VERSION "dbc-export 1 2026.26.6.5"

NS_ :

BS_:

BU_: ADSP APB APP APS APSB BB BMS CC CMP CMPD CP DAS DI DIF DIR DPB EPAS3P EPAS3S EPASTP EPASTS EPBL EPBR ESP EVSE FC GTW HCML HCMR HVP IBST ICR IDB LS OCS1P ODIN PARK PCS PCS2 PLG PM PMF PMR PNCD PTC RADC RCM RCM2 RCM3 RCU SCCM SCM SCS SDCR TAS TCU TCU2 TPMS TRCM UDS UI UIS UMC USM V2G VC VCBATT VCBATT0 VCBATT1 VCBATT2 VCCC VCFRONT VCFRONT1 VCFRONT2 VCLEFT VCRIGHT VCSEAT2L VCSEAT2R VCSEC VEH

BO_ 1317 PMF_alertLog: 8 PMF
 SG_ PMF_alertID M : 0|7@1+ (1,0) [0|127] "" Vector__XXX
 SG_ PMF_alertState : 15|1@1+ (1,0) [0|1] "" Vector__XXX
 SG_ PMF_a001_w0 m1 : 16|16@1+ (1,0) [0|65535] "" Vector__XXX
 SG_ PMF_a001_w1 m1 : 32|16@1+ (1,0) [0|65535] "" Vector__XXX
 SG_ PMF_a001_w2 m1 : 48|16@1+ (1,0) [0|65535] "" Vector__XXX
 SG_ PMF_a002_torqueAverage m2 : 16|1@1+ (1,0) [0|1] "" Vector__XXX
 SG_ PMF_a002_torqueWindow m2 : 17|1@1+ (1,0) [0|1] "" Vector__XXX
 SG_ PMF_a002_torqueMeasured m2 : 18|13@1- (2,0) [-8192|8190] "Nm" Vector__XXX
 SG_ PMF_a002_torqueAccelAverage m2 : 32|13@1- (2,0) [-8192|8190] "Nm" Vector__XXX
 SG_ PMF_a002_torqueAccelWindow m2 : 48|13@1- (2,0) [-8192|8190] "Nm" Vector__XXX
 SG_ PMF_a003_reverseGear m3 : 16|1@1+ (1,0) [0|1] "" Vector__XXX
 SG_ PMF_a003_pedalPos m3 : 24|8@1+ (0.4,0) [0|102] "%" Vector__XXX
 SG_ PMF_a003_zeroPointPedal m3 : 32|8@1+ (0.4,0) [0|102] "%" Vector__XXX
 SG_ PMF_a004_torqueAverage m4 : 16|1@1+ (1,0) [0|1] "" Vector__XXX
 SG_ PMF_a004_torqueWindow m4 : 17|1@1+ (1,0) [0|1] "" Vector__XXX
 SG_ PMF_a004_torqueMeasured m4 : 18|13@1- (2,0) [-8192|8190] "Nm" Vector__XXX
 SG_ PMF_a004_torqueDecelAverage m4 : 32|13@1- (2,0) [-8192|8190] "Nm" Vector__XXX
 SG_ PMF_a004_torqueDecelWindow m4 : 48|13@1- (2,0) [-8192|8190] "Nm" Vector__XXX
 SG_ PMF_a005_torqueReason m5 : 16|2@1+ (1,0) [0|3] "" Vector__XXX
 SG_ PMF_a005_torqueMeasured m5 : 18|13@1- (2,0) [-8192|8190] "Nm" Vector__XXX
 SG_ PMF_a005_iDQmagnitude m5 : 32|16@1- (0.0939,0) [-3076.9152|3076.8213] "A" Vector__XXX
 SG_ PMF_a006_torqueActual m6 : 16|13@1- (2,0) [-8192|8190] "Nm" Vector__XXX
 SG_ PMF_a006_motorRPM m6 : 32|16@1- (1,0) [-32768|32767] "RPM" Vector__XXX
 SG_ PMF_a006_torqueMeasured m6 : 48|13@1- (2,0) [-8192|8190] "Nm" Vector__XXX
 SG_ PMF_a010_messageId m10 : 16|16@1+ (1,0) [0|65535] "" Vector__XXX
 SG_ PMF_a010_DI_status m10 : 32|1@1+ (1,0) [0|1] "" Vector__XXX
 SG_ PMF_a010_DI_torque m10 : 33|1@1+ (1,0) [0|1] "" Vector__XXX
 SG_ PMF_a010_DI_slaveCommand m10 : 34|1@1+ (1,0) [0|1] "" Vector__XXX
 SG_ PMF_a010_DI_locStatus m10 : 35|1@1+ (1,0) [0|1] "" Vector__XXX
 SG_ PMF_a010_DI_speed m10 : 36|1@1+ (1,0) [0|1] "" Vector__XXX
 SG_ PMF_a010_DI_systemStatus m10 : 37|1@1+ (1,0) [0|1] "" Vector__XXX
 SG_ PMF_a010_DI_chassisControl m10 : 38|1@1+ (1,0) [0|1] "" Vector__XXX
 SG_ PMF_a010_DI_chassisControl2 m10 : 39|1@1+ (1,0) [0|1] "" Vector__XXX
 SG_ PMF_a010_vdcLeft m10 : 40|1@1+ (1,0) [0|1] "" Vector__XXX
 SG_ PMF_a010_vdcRight m10 : 41|1@1+ (1,0) [0|1] "" Vector__XXX
 SG_ PMF_a010_DI_vehicleEstimates m10 : 42|1@1+ (1,0) [0|1] "" Vector__XXX
 SG_ PMF_a010_DI_brakeCommand m10 : 43|1@1+ (1,0) [0|1] "" Vector__XXX
 SG_ PMF_a010_DI_autonomyHealth m10 : 44|1@1+ (1,0) [0|1] "" Vector__XXX
 SG_ PMF_a010_DI_difCommand m10 : 45|1@1+ (1,0) [0|1] "" Vector__XXX
 SG_ PMF_a010_DI_dirCommand m10 : 46|1@1+ (1,0) [0|1] "" Vector__XXX
 SG_ PMF_a010_DI_dirVehicle m10 : 47|1@1+ (1,0) [0|1] "" Vector__XXX
 SG_ PMF_a010_DI_locStatus2 m10 : 48|1@1+ (1,0) [0|1] "" Vector__XXX
 SG_ PMF_a011_Ia m11 : 16|9@1- (12.0192,0) [-3076.9152|3064.896] "A" Vector__XXX
 SG_ PMF_a011_IaDelta m11 : 25|8@1- (24.0384,0) [-3076.9152|3052.8768] "A" Vector__XXX
 SG_ PMF_a011_Ib m11 : 33|9@1- (12.0192,0) [-3076.9152|3064.896] "A" Vector__XXX
 SG_ PMF_a011_IbDelta m11 : 42|8@1- (24.0384,0) [-3076.9152|3052.8768] "A" Vector__XXX
 SG_ PMF_a011_currentVref m11 : 50|8@1+ (0.04,0) [0|10.2] "V" Vector__XXX
 SG_ PMF_a011_badPhaseAsample m11 : 58|1@1+ (1,0) [0|1] "" Vector__XXX
 SG_ PMF_a011_badPhaseBsample m11 : 59|1@1+ (1,0) [0|1] "" Vector__XXX
 SG_ PMF_a011_sampleFreeze m11 : 60|1@1+ (1,0) [0|1] "" Vector__XXX
 SG_ PMF_a011_rateOfChangeIrrational m11 : 61|1@1+ (1,0) [0|1] "" Vector__XXX
 SG_ PMF_a011_currentReadingIrrationa m11 : 62|1@1+ (1,0) [0|1] "" Vector__XXX
 SG_ PMF_a011_vrefIrrational m11 : 63|1@1+ (1,0) [0|1] "" Vector__XXX
 SG_ PMF_a017_EPBL_status m17 : 16|1@1+ (1,0) [0|1] "" Vector__XXX
 SG_ PMF_a017_EPBR_status m17 : 17|1@1+ (1,0) [0|1] "" Vector__XXX
 SG_ PMF_a017_EPBL_autonomyHealth m17 : 18|1@1+ (1,0) [0|1] "" Vector__XXX
 SG_ PMF_a017_EPBR_autonomyHealth m17 : 19|1@1+ (1,0) [0|1] "" Vector__XXX
 SG_ PMF_a018_w0 m18 : 16|16@1+ (1,0) [0|65535] "" Vector__XXX
 SG_ PMF_a018_w1 m18 : 32|16@1+ (1,0) [0|65535] "" Vector__XXX
 SG_ PMF_a018_w2 m18 : 48|16@1+ (1,0) [0|65535] "" Vector__XXX
 SG_ PMF_a019_statorTemp1 m19 : 16|16@1- (0.1,0) [-3276.8|3276.7] "DegC" Vector__XXX
 SG_ PMF_a019_statorTslope1 m19 : 32|16@1- (0.1,0) [-3276.8|3276.7] "DegC/s" Vector__XXX
 SG_ PMF_a025_sccReset m25 : 16|1@1+ (1,0) [0|1] "" Vector__XXX
 SG_ PMF_a025_hibernate m25 : 17|1@1+ (1,0) [0|1] "" Vector__XXX
 SG_ PMF_a025_hwBist m25 : 18|1@1+ (1,0) [0|1] "" Vector__XXX
 SG_ PMF_a025_nmiWatchdog m25 : 19|1@1+ (1,0) [0|1] "" Vector__XXX
 SG_ PMF_a025_watchdog m25 : 20|1@1+ (1,0) [0|1] "" Vector__XXX
 SG_ PMF_a025_clockFailNmi m25 : 21|1@1+ (1,0) [0|1] "" Vector__XXX
 SG_ PMF_a025_ramUncErrorNmi m25 : 22|1@1+ (1,0) [0|1] "" Vector__XXX
 SG_ PMF_a025_flashUncErrorNmi m25 : 23|1@1+ (1,0) [0|1] "" Vector__XXX
 SG_ PMF_a025_cpu1signMismatchNmi m25 : 24|1@1+ (1,0) [0|1] "" Vector__XXX
 SG_ PMF_a025_cpu2signMismatchNmi m25 : 25|1@1+ (1,0) [0|1] "" Vector__XXX
 SG_ PMF_a025_pieVectErrorNmi m25 : 26|1@1+ (1,0) [0|1] "" Vector__XXX
 SG_ PMF_a025_sysDbgNmi m25 : 27|1@1+ (1,0) [0|1] "" Vector__XXX
 SG_ PMF_a025_rlNmi m25 : 28|1@1+ (1,0) [0|1] "" Vector__XXX
 SG_ PMF_a025_ovfNmi m25 : 29|1@1+ (1,0) [0|1] "" Vector__XXX
 SG_ PMF_a025_possibleSafetyICReset m25 : 30|1@1+ (1,0) [0|1] "" Vector__XXX
 SG_ PMF_a025_powerOnReset m25 : 31|1@1+ (1,0) [0|1] "" Vector__XXX
 SG_ PMF_a025_watchdogTimer0 m25 : 32|1@1+ (1,0) [0|1] "" Vector__XXX
 SG_ PMF_a025_watchdogTimer1 m25 : 33|1@1+ (1,0) [0|1] "" Vector__XXX
 SG_ PMF_a025_watchdogTimer2 m25 : 34|1@1+ (1,0) [0|1] "" Vector__XXX
 SG_ PMF_a025_watchdogTimer3 m25 : 35|1@1+ (1,0) [0|1] "" Vector__XXX
 SG_ PMF_a025_warmResetReq m25 : 36|1@1+ (1,0) [0|1] "" Vector__XXX
 SG_ PMF_a025_externalPadReset m25 : 37|1@1+ (1,0) [0|1] "" Vector__XXX
 SG_ PMF_a025_hwSecModuleWatchdogTime m25 : 38|1@1+ (1,0) [0|1] "" Vector__XXX
 SG_ PMF_a025_debugReset m25 : 39|1@1+ (1,0) [0|1] "" Vector__XXX
 SG_ PMF_a025_tempSense0 m25 : 40|1@1+ (1,0) [0|1] "" Vector__XXX
 SG_ PMF_a025_tempSense1 m25 : 41|1@1+ (1,0) [0|1] "" Vector__XXX
 SG_ PMF_a026_reason m26 : 16|1@1+ (1,0) [0|1] "" Vector__XXX
 SG_ PMF_a026_isrCount20kHz m26 : 17|5@1+ (1,0) [0|31] "" Vector__XXX
 SG_ PMF_a026_isrCount1kHz m26 : 22|4@1+ (1,0) [0|15] "" Vector__XXX
 SG_ PMF_a026_switchingActive m26 : 26|1@1+ (1,0) [0|1] "" Vector__XXX
 SG_ PMF_a026_systemStackOvf m26 : 27|1@1+ (1,0) [0|1] "" Vector__XXX
 SG_ PMF_a026_controlStackOvf m26 : 28|1@1+ (1,0) [0|1] "" Vector__XXX
 SG_ PMF_a026_idleStackOvf m26 : 29|1@1+ (1,0) [0|1] "" Vector__XXX
 SG_ PMF_a026_eepStackOvf m26 : 30|1@1+ (1,0) [0|1] "" Vector__XXX
 SG_ PMF_a026_immStackOvf m26 : 31|1@1+ (1,0) [0|1] "" Vector__XXX
 SG_ PMF_a026_xdcErrorIdMSW m26 : 32|10@1+ (1,0) [0|1023] "" Vector__XXX
 SG_ PMF_a026_xdcErrorArg1 m26 : 42|22@1- (1,0) [-2097152|2097151] "" Vector__XXX
 SG_ PMF_a032_w0 m32 : 16|16@1+ (1,0) [0|65535] "" Vector__XXX
 SG_ PMF_a032_w1 m32 : 32|16@1+ (1,0) [0|65535] "" Vector__XXX
 SG_ PMF_a032_w2 m32 : 48|16@1+ (1,0) [0|65535] "" Vector__XXX
 SG_ PMF_a033_state m33 : 16|4@1+ (1,0) [0|15] "" Vector__XXX
 SG_ PMF_a033_failReason m33 : 20|3@1+ (1,0) [0|7] "" Vector__XXX
 SG_ PMF_a033_DSADC_Ia m33 : 24|16@1- (0.0939,0) [-3076.9152|3076.8213] "A" Vector__XXX
 SG_ PMF_a033_DSADC_Ib m33 : 40|16@1- (0.0939,0) [-3076.9152|3076.8213] "A" Vector__XXX
 SG_ PMF_a036_timeSinceTxHWI m36 : 16|6@1+ (64,0) [0|4032] "us" Vector__XXX
 SG_ PMF_a036_timeSinceRxHWI m36 : 22|6@1+ (64,0) [0|4032] "us" Vector__XXX
 SG_ PMF_a036_timeSince100HzTxSWI m36 : 28|6@1+ (0.32,0) [0|20.16] "ms" Vector__XXX
 SG_ PMF_a036_timeSince1kHzCLK m36 : 34|6@1+ (32,0) [0|2016] "us" Vector__XXX
 SG_ PMF_a036_timeSince1kHzSWI m36 : 40|6@1+ (32,0) [0|2016] "us" Vector__XXX
 SG_ PMF_a036_timeSinceIdle m36 : 46|6@1+ (0.16,0) [0|10.08] "ms" Vector__XXX
 SG_ PMF_a036_ovfStackId m36 : 52|4@1+ (1,0) [0|14] "" Vector__XXX
 SG_ PMF_a036_inTxISR m36 : 56|1@1+ (1,0) [0|1] "" Vector__XXX
 SG_ PMF_a036_inTxHWI m36 : 57|1@1+ (1,0) [0|1] "" Vector__XXX
 SG_ PMF_a036_inRxHWI m36 : 58|1@1+ (1,0) [0|1] "" Vector__XXX
 SG_ PMF_a036_in1kHzSWI m36 : 59|1@1+ (1,0) [0|1] "" Vector__XXX
 SG_ PMF_a036_in1kHzCLK m36 : 60|1@1+ (1,0) [0|1] "" Vector__XXX
 SG_ PMF_a036_in100HzCLK m36 : 61|1@1+ (1,0) [0|1] "" Vector__XXX
 SG_ PMF_a036_in10HzCLK m36 : 62|1@1+ (1,0) [0|1] "" Vector__XXX
 SG_ PMF_a036_in1HzCLK m36 : 63|1@1+ (1,0) [0|1] "" Vector__XXX
 SG_ PMF_a037_hvpFaults m37 : 16|1@1+ (1,0) [0|1] "" Vector__XXX
 SG_ PMF_a039_DIS_status m39 : 16|1@1+ (1,0) [0|1] "" Vector__XXX
 SG_ PMF_a039_DIS_torque m39 : 17|1@1+ (1,0) [0|1] "" Vector__XXX
 SG_ PMF_a039_messageId m39 : 24|16@1+ (1,0) [0|65535] "" Vector__XXX
 SG_ PMF_a040_PM_state m40 : 16|1@1+ (1,0) [0|1] "" Vector__XXX
 SG_ PMF_a040_messageId m40 : 24|16@1+ (1,0) [0|65535] "" Vector__XXX
 SG_ PMF_a040_PM_locState m40 : 40|1@1+ (1,0) [0|1] "" Vector__XXX
 SG_ PMF_a042_GTW_carConfig m42 : 16|1@1+ (1,0) [0|1] "" Vector__XXX
 SG_ PMF_a042_GTW_time m42 : 17|1@1+ (1,0) [0|1] "" Vector__XXX
 SG_ PMF_a042_GTW_drivetrainType m42 : 18|3@1+ (1,0) [0|7] "" Vector__XXX
 SG_ PMF_a042_expectedPerformanceCfg m42 : 21|3@1+ (1,0) [0|7] "" Vector__XXX
 SG_ PMF_a042_gearControl m42 : 24|1@1+ (1,0) [0|1] "" Vector__XXX
 SG_ PMF_a053_LVPowerState m53 : 16|1@1+ (1,0) [0|1] "" Vector__XXX
 SG_ PMF_a053_coolant m53 : 17|1@1+ (1,0) [0|1] "" Vector__XXX
 SG_ PMF_a053_vcleftSwitchStatus m53 : 18|1@1+ (1,0) [0|1] "" Vector__XXX
 SG_ PMF_a053_restraintStatus m53 : 19|1@1+ (1,0) [0|1] "" Vector__XXX
 SG_ PMF_a053_sensors m53 : 20|1@1+ (1,0) [0|1] "" Vector__XXX
 SG_ PMF_a054_uiPowertrainControl m54 : 16|1@1+ (1,0) [0|1] "" Vector__XXX
 SG_ PMF_a054_uiChassisControl m54 : 17|1@1+ (1,0) [0|1] "" Vector__XXX
 SG_ PMF_a054_uiCruiseControl m54 : 18|1@1+ (1,0) [0|1] "" Vector__XXX
 SG_ PMF_a054_uiTrackModeSettings m54 : 19|1@1+ (1,0) [0|1] "" Vector__XXX
 SG_ PMF_a054_uiTPMSRCPSetting m54 : 20|1@1+ (1,0) [0|1] "" Vector__XXX
 SG_ PMF_a055_motorRPM m55 : 16|16@1- (1,0) [-32768|32767] "RPM" Vector__XXX
 SG_ PMF_a055_phaseAngle m55 : 32|8@1+ (0.00308,0) [0|0.7854] "1" Vector__XXX
 SG_ PMF_a055_commonGain m55 : 40|8@1+ (0.02,0) [0|5.1] "1" Vector__XXX
 SG_ PMF_a055_notReady m55 : 48|1@1+ (1,0) [0|1] "" Vector__XXX
 SG_ PMF_a055_noCarrier m55 : 49|1@1+ (1,0) [0|1] "" Vector__XXX
 SG_ PMF_a055_phaseOutOfSpec m55 : 50|1@1+ (1,0) [0|1] "" Vector__XXX
 SG_ PMF_a055_diElecAngleMismatch m55 : 51|1@1+ (1,0) [0|1] "" Vector__XXX
 SG_ PMF_a055_diSpeedMismatch m55 : 52|1@1+ (1,0) [0|1] "" Vector__XXX
 SG_ PMF_a055_claMIA m55 : 53|1@1+ (1,0) [0|1] "" Vector__XXX
 SG_ PMF_a055_diMIA m55 : 54|1@1+ (1,0) [0|1] "" Vector__XXX
 SG_ PMF_a055_diElecAngleMismatchWarn m55 : 55|1@1+ (1,0) [0|1] "" Vector__XXX
 SG_ PMF_a058_hvilCurrent m58 : 16|8@1+ (0.1,0) [0|25.5] "mA" Vector__XXX
 SG_ PMF_a061_diIpcVersion m61 : 16|8@1+ (1,0) [0|255] "" Vector__XXX
 SG_ PMF_a061_pmIpcVersion m61 : 24|8@1+ (1,0) [0|255] "" Vector__XXX
 SG_ PMF_a062_address m62 : 16|32@1+ (1,0) [0|4294967295] "" Vector__XXX
 SG_ PMF_a062_errorType m62 : 48|4@1+ (1,0) [0|15] "" Vector__XXX
 SG_ PMF_a062_detectedByRamScrub m62 : 52|1@1+ (1,0) [0|1] "" Vector__XXX
 SG_ PMF_a064_interventionType m64 : 16|4@1+ (1,0) [0|15] "" Vector__XXX
 SG_ PMF_a064_torqueCmdState m64 : 20|4@1+ (1,0) [1|15] "" Vector__XXX
 SG_ PMF_a064_shortDetectedByDI m64 : 24|1@1+ (1,0) [0|1] "" Vector__XXX
 SG_ PMF_a064_UI_stoppingMode m64 : 25|2@1+ (1,0) [0|3] "" Vector__XXX
 SG_ PMF_a064_diCrsState m64 : 27|3@1+ (1,0) [0|7] "" Vector__XXX
 SG_ PMF_a064_pmCrsState m64 : 32|3@1+ (1,0) [0|7] "" Vector__XXX
 SG_ PMF_a082_faultAddress m82 : 16|32@1+ (1,0) [0|4294967295] "" Vector__XXX
 SG_ PMF_a082_isWriteNotRead m82 : 48|1@1+ (1,0) [0|1] "" Vector__XXX
 SG_ PMF_a084_faultAddress m84 : 16|32@1+ (1,0) [0|4294967295] "" Vector__XXX
 SG_ PMF_a084_firewallId m84 : 48|5@1+ (1,0) [0|31] "" Vector__XXX
 SG_ PMF_a084_privId m84 : 56|4@1+ (1,0) [0|15] "" Vector__XXX
 SG_ PMF_a084_ns m84 : 60|1@1+ (1,0) [0|1] "" Vector__XXX
 SG_ PMF_a084_faultType m84 : 61|3@1+ (1,0) [0|7] "" Vector__XXX
 SG_ PMF_a092_pllClockSource m92 : 16|2@1+ (1,0) [0|3] "" Vector__XXX
 SG_ PMF_a095_wwdErrIntFlag m95 : 16|1@1+ (1,0) [0|1] "" Vector__XXX
 SG_ PMF_a095_fwdErrIntFlag m95 : 17|1@1+ (1,0) [0|1] "" Vector__XXX
 SG_ PMF_a095_errMissStsFlag m95 : 18|1@1+ (1,0) [0|1] "" Vector__XXX
 SG_ PMF_a095_preRegulatorOT m95 : 19|1@1+ (1,0) [0|1] "" Vector__XXX
 SG_ PMF_a095_ucLdoOT m95 : 20|1@1+ (1,0) [0|1] "" Vector__XXX
 SG_ PMF_a095_monitoringOT m95 : 21|1@1+ (1,0) [0|1] "" Vector__XXX
 SG_ PMF_a095_preRegulatorVoltShort m95 : 22|1@1+ (1,0) [0|1] "" Vector__XXX
 SG_ PMF_a095_ucLdoShort m95 : 23|1@1+ (1,0) [0|1] "" Vector__XXX
 SG_ PMF_a095_standbyLdoShort m95 : 24|1@1+ (1,0) [0|1] "" Vector__XXX
 SG_ PMF_a095_coreVoltShort m95 : 25|1@1+ (1,0) [0|1] "" Vector__XXX
 SG_ PMF_a095_preRegulatorOV m95 : 26|1@1+ (1,0) [0|1] "" Vector__XXX
 SG_ PMF_a095_ucLdoOV m95 : 27|1@1+ (1,0) [0|1] "" Vector__XXX
 SG_ PMF_a095_standbyLdoOV m95 : 28|1@1+ (1,0) [0|1] "" Vector__XXX
 SG_ PMF_a095_coreOV m95 : 29|1@1+ (1,0) [0|1] "" Vector__XXX
 SG_ PMF_a095_voltRefOV m95 : 30|1@1+ (1,0) [0|1] "" Vector__XXX
 SG_ PMF_a095_ucLdoUV m95 : 31|1@1+ (1,0) [0|1] "" Vector__XXX
 SG_ PMF_a095_standbyLdoUV m95 : 32|1@1+ (1,0) [0|1] "" Vector__XXX
 SG_ PMF_a095_coreUV m95 : 33|1@1+ (1,0) [0|1] "" Vector__XXX
 SG_ PMF_a095_supplyVoltOV m95 : 34|1@1+ (1,0) [0|1] "" Vector__XXX
 SG_ PMF_a095_bandgapComparatorUV m95 : 35|1@1+ (1,0) [0|1] "" Vector__XXX
 SG_ PMF_a095_bandgapComparatorOV m95 : 36|1@1+ (1,0) [0|1] "" Vector__XXX
 SG_ PMF_a095_biasCurrentTooLow m95 : 37|1@1+ (1,0) [0|1] "" Vector__XXX
 SG_ PMF_a095_biasCurrentTooHigh m95 : 38|1@1+ (1,0) [0|1] "" Vector__XXX
 SG_ PMF_a095_safetyICstate m95 : 40|3@1+ (1,0) [0|7] "" Vector__XXX
 SG_ PMF_a095_motorRPM m95 : 43|12@1- (10,0) [-20480|20470] "RPM" Vector__XXX
 SG_ PMF_a095_wwdErrCounter m95 : 56|4@1+ (1,0) [0|15] "" Vector__XXX
 SG_ PMF_a095_fwdErrCounter m95 : 60|4@1+ (1,0) [0|15] "" Vector__XXX
 SG_ PMF_a100_index1kHzPeriodic m100 : 16|8@1+ (1,0) [0|255] "" Vector__XXX
 SG_ PMF_a100_index100HzPeriodic m100 : 24|8@1+ (1,0) [0|255] "" Vector__XXX
 SG_ PMF_a100_index10HzPeriodic m100 : 32|8@1+ (1,0) [0|255] "" Vector__XXX
 SG_ PMF_a100_indexSWI m100 : 40|8@1+ (1,0) [0|255] "" Vector__XXX
 SG_ PMF_a100_eepEvent m100 : 48|8@1+ (1,0) [0|255] "" Vector__XXX
 SG_ PMF_a100_module500HzActive m100 : 56|1@1+ (1,0) [0|1] "" Vector__XXX
 SG_ PMF_a100_module50HzActive m100 : 57|1@1+ (1,0) [0|1] "" Vector__XXX
 SG_ PMF_a100_module1HzActive m100 : 58|1@1+ (1,0) [0|1] "" Vector__XXX
 SG_ PMF_a100_task10HzActive m100 : 59|1@1+ (1,0) [0|1] "" Vector__XXX
 SG_ PMF_a100_taskUdsActive m100 : 60|1@1+ (1,0) [0|1] "" Vector__XXX

BO_ 772 PMF_alertMatrix: 8 PMF
 SG_ PMF_matrixIndex M : 0|4@1+ (1,0) [0|15] "" Vector__XXX
 SG_ PMF_a001_absoluteTorque m0 : 4|1@1+ (1,0) [0|1] "" Vector__XXX
 SG_ PMF_a002_excessiveAccelTorque m0 : 5|1@1+ (1,0) [0|1] "" Vector__XXX
 SG_ PMF_a003_excessiveReversalTorque m0 : 6|1@1+ (1,0) [0|1] "" Vector__XXX
 SG_ PMF_a004_excessiveDecelTorque m0 : 7|1@1+ (1,0) [0|1] "" Vector__XXX
 SG_ PMF_a005_torqueInNeutralOrPark m0 : 8|1@1+ (1,0) [0|1] "" Vector__XXX
 SG_ PMF_a006_underTorqueCheck m0 : 9|1@1+ (1,0) [0|1] "" Vector__XXX
 SG_ PMF_a008_memoryError m0 : 11|1@1+ (1,0) [0|1] "" Vector__XXX
 SG_ PMF_a010_diMIA m0 : 13|1@1+ (1,0) [0|1] "" Vector__XXX
 SG_ PMF_a011_phaseCurrentIrrational m0 : 14|1@1+ (1,0) [0|1] "" Vector__XXX
 SG_ PMF_a012_canDataBusA m0 : 15|1@1+ (1,0) [0|1] "" Vector__XXX
 SG_ PMF_a013_canHardwareBusA m0 : 16|1@1+ (1,0) [0|1] "" Vector__XXX
 SG_ PMF_a017_brakeMIA m0 : 20|1@1+ (1,0) [0|1] "" Vector__XXX
 SG_ PMF_a018_encoderIrrational m0 : 21|1@1+ (1,0) [0|1] "" Vector__XXX
 SG_ PMF_a019_statorTempIrrational m0 : 22|1@1+ (1,0) [0|1] "" Vector__XXX
 SG_ PMF_a025_unintendedReset m0 : 28|1@1+ (1,0) [0|1] "" Vector__XXX
 SG_ PMF_a026_diHeartBeatMIA m0 : 29|1@1+ (1,0) [0|1] "" Vector__XXX
 SG_ PMF_a027_torqueEstimationOutOfBo m0 : 30|1@1+ (1,0) [0|1] "" Vector__XXX
 SG_ PMF_a028_torqueCmdError m0 : 31|1@1+ (1,0) [0|1] "" Vector__XXX
 SG_ PMF_a031_highStackUsage m0 : 34|1@1+ (1,0) [0|1] "" Vector__XXX
 SG_ PMF_a032_registerConfigError m0 : 35|1@1+ (1,0) [0|1] "" Vector__XXX
 SG_ PMF_a033_selfTest m0 : 36|1@1+ (1,0) [0|1] "" Vector__XXX
 SG_ PMF_a034_trqCrossCheck m0 : 37|1@1+ (1,0) [0|1] "" Vector__XXX
 SG_ PMF_a035_udsTransactionInitiated m0 : 38|1@1+ (1,0) [0|1] "" Vector__XXX
 SG_ PMF_a036_preWatchdog m0 : 39|1@1+ (1,0) [0|1] "" Vector__XXX
 SG_ PMF_a037_hvpMIA m0 : 40|1@1+ (1,0) [0|1] "" Vector__XXX
 SG_ PMF_a039_disMIA m0 : 42|1@1+ (1,0) [0|1] "" Vector__XXX
 SG_ PMF_a040_pmMIA m0 : 43|1@1+ (1,0) [0|1] "" Vector__XXX
 SG_ PMF_a042_gtwMIA m0 : 45|1@1+ (1,0) [0|1] "" Vector__XXX
 SG_ PMF_a045_motorMovementDetected m0 : 48|1@1+ (1,0) [0|1] "" Vector__XXX
 SG_ PMF_a053_vcfrontMIA m0 : 56|1@1+ (1,0) [0|1] "" Vector__XXX
 SG_ PMF_a054_uiMIA m0 : 57|1@1+ (1,0) [0|1] "" Vector__XXX
 SG_ PMF_a055_resolver m0 : 58|1@1+ (1,0) [0|1] "" Vector__XXX
 SG_ PMF_a056_canHardwareBusB m0 : 59|1@1+ (1,0) [0|1] "" Vector__XXX
 SG_ PMF_a057_canDataBusB m0 : 60|1@1+ (1,0) [0|1] "" Vector__XXX
 SG_ PMF_a058_measuredHvilCurrentFroz m0 : 61|1@1+ (1,0) [0|1] "" Vector__XXX
 SG_ PMF_a061_DIPMVersionMismatch m1 : 4|1@1+ (1,0) [0|1] "" Vector__XXX
 SG_ PMF_a062_eccError m1 : 5|1@1+ (1,0) [0|1] "" Vector__XXX
 SG_ PMF_a064_torqueIntervention m1 : 7|1@1+ (1,0) [0|1] "" Vector__XXX
 SG_ PMF_a080_exceptionPrefetchAbort m1 : 23|1@1+ (1,0) [0|1] "" Vector__XXX
 SG_ PMF_a081_exceptionDataAbort m1 : 24|1@1+ (1,0) [0|1] "" Vector__XXX
 SG_ PMF_a082_exceptionDataAbort2 m1 : 25|1@1+ (1,0) [0|1] "" Vector__XXX
 SG_ PMF_a083_ahbWriteError m1 : 26|1@1+ (1,0) [0|1] "" Vector__XXX
 SG_ PMF_a084_exceptionMpuFirewall m1 : 27|1@1+ (1,0) [0|1] "" Vector__XXX
 SG_ PMF_a086_exceptionUndefinedInstr m1 : 29|1@1+ (1,0) [0|1] "" Vector__XXX
 SG_ PMF_a092_xtalOscillator m1 : 35|1@1+ (1,0) [0|1] "" Vector__XXX
 SG_ PMF_a094_safetyICWarn m1 : 37|1@1+ (1,0) [0|1] "" Vector__XXX
 SG_ PMF_a095_safetyICFault m1 : 38|1@1+ (1,0) [0|1] "" Vector__XXX
 SG_ PMF_a096_safetyICDebug m1 : 39|1@1+ (1,0) [0|1] "" Vector__XXX
 SG_ PMF_a097_lowFlowAlmostTripped m1 : 40|1@1+ (1,0) [0|1] "" Vector__XXX
 SG_ PMF_a100_diTraceInfo1 m1 : 43|1@1+ (1,0) [0|1] "" Vector__XXX
 SG_ PMF_a114_ramScrubTimedOut m1 : 57|1@1+ (1,0) [0|1] "" Vector__XXX
 SG_ PMF_a121_unintendedReset2 m2 : 4|1@1+ (1,0) [0|1] "" Vector__XXX

BO_ 790 PMF_info: 8 PMF
 SG_ PMF_infoIndex M : 0|8@1+ (1,0) [0|255] "" Vector__XXX
 SG_ PMF_buildType m10 : 8|8@1+ (1,0) [0|255] "" Vector__XXX
 SG_ PMF_buildConfigurationId m10 : 16|16@1+ (1,0) [0|65535] "" Vector__XXX
 SG_ PMF_hardwareId m10 : 32|8@1+ (1,0) [0|252] "" Vector__XXX
 SG_ PMF_deviceFused m10 : 40|1@1+ (1,0) [0|1] "" Vector__XXX
 SG_ PMF_componentId m10 : 48|16@1+ (1,0) [0|65535] "" Vector__XXX
 SG_ PMF_pcbaId m11 : 16|8@1+ (1,0) [0|255] "" Vector__XXX
 SG_ PMF_assemblyId m11 : 24|8@1+ (1,0) [0|255] "" Vector__XXX
 SG_ PMF_usageId m11 : 32|16@1+ (1,0) [0|65535] "" Vector__XXX
 SG_ PMF_subUsageId m11 : 48|16@1+ (1,0) [0|65535] "" Vector__XXX
 SG_ PMF_applicationCrc m13 : 32|32@1+ (1,0) [0|4294967295] "" Vector__XXX
 SG_ PMF_appGitHash m17 : 8|56@1+ (1,0) [0|7.20575940379e+16] "" Vector__XXX
 SG_ PMF_bootGitHash m18 : 8|56@1+ (1,0) [0|7.20575940379e+16] "" Vector__XXX
 SG_ PMF_platformTyp m19 : 8|8@1+ (1,0) [0|255] "" Vector__XXX
 SG_ PMF_udsProtocolVersion m20 : 8|8@1+ (1,0) [0|255] "" Vector__XXX
 SG_ PMF_bootloaderCrc m20 : 32|32@1+ (1,0) [0|4294967295] "" Vector__XXX

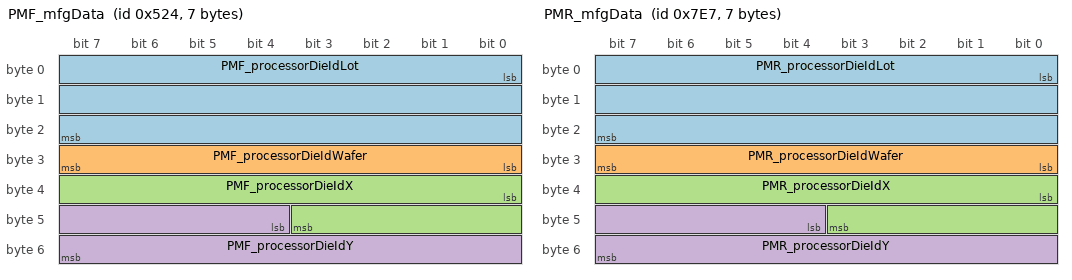
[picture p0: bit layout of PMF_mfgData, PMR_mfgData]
BO_ 1316 PMF_mfgData: 7 PMF
 SG_ PMF_processorDieIdLot : 0|24@1+ (1,0) [0|16777215] "" Vector__XXX
 SG_ PMF_processorDieIdWafer : 24|8@1+ (1,0) [0|255] "" Vector__XXX
 SG_ PMF_processorDieIdX : 32|12@1+ (1,0) [0|4095] "" Vector__XXX
 SG_ PMF_processorDieIdY : 44|12@1+ (1,0) [0|4095] "" Vector__XXX

BO_ 1620 PMF_udsResponse: 8 PMF
 SG_ PMF_udsResponseData : 7|64@0+ (1,0) [0|1.84467440737e+19] "" Vector__XXX

BO_ 1446 PMR_alertLog: 8 PMR
 SG_ PMR_alertID M : 0|7@1+ (1,0) [0|127] "" Vector__XXX
 SG_ PMR_alertState : 15|1@1+ (1,0) [0|1] "" Vector__XXX
 SG_ PMR_a001_w0 m1 : 16|16@1+ (1,0) [0|65535] "" Vector__XXX
 SG_ PMR_a001_w1 m1 : 32|16@1+ (1,0) [0|65535] "" Vector__XXX
 SG_ PMR_a001_w2 m1 : 48|16@1+ (1,0) [0|65535] "" Vector__XXX
 SG_ PMR_a002_torqueAverage m2 : 16|1@1+ (1,0) [0|1] "" Vector__XXX
 SG_ PMR_a002_torqueWindow m2 : 17|1@1+ (1,0) [0|1] "" Vector__XXX
 SG_ PMR_a002_torqueMeasured m2 : 18|13@1- (2,0) [-8192|8190] "Nm" Vector__XXX
 SG_ PMR_a002_torqueAccelAverage m2 : 32|13@1- (2,0) [-8192|8190] "Nm" Vector__XXX
 SG_ PMR_a002_torqueAccelWindow m2 : 48|13@1- (2,0) [-8192|8190] "Nm" Vector__XXX
 SG_ PMR_a003_reverseGear m3 : 16|1@1+ (1,0) [0|1] "" Vector__XXX
 SG_ PMR_a003_pedalPos m3 : 24|8@1+ (0.4,0) [0|102] "%" Vector__XXX
 SG_ PMR_a003_zeroPointPedal m3 : 32|8@1+ (0.4,0) [0|102] "%" Vector__XXX
 SG_ PMR_a004_torqueAverage m4 : 16|1@1+ (1,0) [0|1] "" Vector__XXX
 SG_ PMR_a004_torqueWindow m4 : 17|1@1+ (1,0) [0|1] "" Vector__XXX
 SG_ PMR_a004_torqueMeasured m4 : 18|13@1- (2,0) [-8192|8190] "Nm" Vector__XXX
 SG_ PMR_a004_torqueDecelAverage m4 : 32|13@1- (2,0) [-8192|8190] "Nm" Vector__XXX
 SG_ PMR_a004_torqueDecelWindow m4 : 48|13@1- (2,0) [-8192|8190] "Nm" Vector__XXX
 SG_ PMR_a005_torqueReason m5 : 16|2@1+ (1,0) [0|3] "" Vector__XXX
 SG_ PMR_a005_torqueMeasured m5 : 18|13@1- (2,0) [-8192|8190] "Nm" Vector__XXX
 SG_ PMR_a005_iDQmagnitude m5 : 32|16@1- (0.0939,0) [-3076.9152|3076.8213] "A" Vector__XXX
 SG_ PMR_a006_torqueActual m6 : 16|13@1- (2,0) [-8192|8190] "Nm" Vector__XXX
 SG_ PMR_a006_motorRPM m6 : 32|16@1- (1,0) [-32768|32767] "RPM" Vector__XXX
 SG_ PMR_a006_torqueMeasured m6 : 48|13@1- (2,0) [-8192|8190] "Nm" Vector__XXX
 SG_ PMR_a010_messageId m10 : 16|16@1+ (1,0) [0|65535] "" Vector__XXX
 SG_ PMR_a010_DI_status m10 : 32|1@1+ (1,0) [0|1] "" Vector__XXX
 SG_ PMR_a010_DI_torque m10 : 33|1@1+ (1,0) [0|1] "" Vector__XXX
 SG_ PMR_a010_DI_slaveCommand m10 : 34|1@1+ (1,0) [0|1] "" Vector__XXX
 SG_ PMR_a010_DI_locStatus m10 : 35|1@1+ (1,0) [0|1] "" Vector__XXX
 SG_ PMR_a010_DI_speed m10 : 36|1@1+ (1,0) [0|1] "" Vector__XXX
 SG_ PMR_a010_DI_systemStatus m10 : 37|1@1+ (1,0) [0|1] "" Vector__XXX
 SG_ PMR_a010_DI_chassisControl m10 : 38|1@1+ (1,0) [0|1] "" Vector__XXX
 SG_ PMR_a010_DI_chassisControl2 m10 : 39|1@1+ (1,0) [0|1] "" Vector__XXX
 SG_ PMR_a010_vdcLeft m10 : 40|1@1+ (1,0) [0|1] "" Vector__XXX
 SG_ PMR_a010_vdcRight m10 : 41|1@1+ (1,0) [0|1] "" Vector__XXX
 SG_ PMR_a010_DI_vehicleEstimates m10 : 42|1@1+ (1,0) [0|1] "" Vector__XXX
 SG_ PMR_a010_DI_brakeCommand m10 : 43|1@1+ (1,0) [0|1] "" Vector__XXX
 SG_ PMR_a010_DI_autonomyHealth m10 : 44|1@1+ (1,0) [0|1] "" Vector__XXX
 SG_ PMR_a010_DI_difCommand m10 : 45|1@1+ (1,0) [0|1] "" Vector__XXX
 SG_ PMR_a010_DI_dirCommand m10 : 46|1@1+ (1,0) [0|1] "" Vector__XXX
 SG_ PMR_a010_DI_dirVehicle m10 : 47|1@1+ (1,0) [0|1] "" Vector__XXX
 SG_ PMR_a010_DI_locStatus2 m10 : 48|1@1+ (1,0) [0|1] "" Vector__XXX
 SG_ PMR_a011_Ia m11 : 16|9@1- (12.0192,0) [-3076.9152|3064.896] "A" Vector__XXX
 SG_ PMR_a011_IaDelta m11 : 25|8@1- (24.0384,0) [-3076.9152|3052.8768] "A" Vector__XXX
 SG_ PMR_a011_Ib m11 : 33|9@1- (12.0192,0) [-3076.9152|3064.896] "A" Vector__XXX
 SG_ PMR_a011_IbDelta m11 : 42|8@1- (24.0384,0) [-3076.9152|3052.8768] "A" Vector__XXX
 SG_ PMR_a011_currentVref m11 : 50|8@1+ (0.04,0) [0|10.2] "V" Vector__XXX
 SG_ PMR_a011_badPhaseAsample m11 : 58|1@1+ (1,0) [0|1] "" Vector__XXX
 SG_ PMR_a011_badPhaseBsample m11 : 59|1@1+ (1,0) [0|1] "" Vector__XXX
 SG_ PMR_a011_sampleFreeze m11 : 60|1@1+ (1,0) [0|1] "" Vector__XXX
 SG_ PMR_a011_rateOfChangeIrrational m11 : 61|1@1+ (1,0) [0|1] "" Vector__XXX
 SG_ PMR_a011_currentReadingIrrationa m11 : 62|1@1+ (1,0) [0|1] "" Vector__XXX
 SG_ PMR_a011_vrefIrrational m11 : 63|1@1+ (1,0) [0|1] "" Vector__XXX
 SG_ PMR_a017_EPBL_status m17 : 16|1@1+ (1,0) [0|1] "" Vector__XXX
 SG_ PMR_a017_EPBR_status m17 : 17|1@1+ (1,0) [0|1] "" Vector__XXX
 SG_ PMR_a017_EPBL_autonomyHealth m17 : 18|1@1+ (1,0) [0|1] "" Vector__XXX
 SG_ PMR_a017_EPBR_autonomyHealth m17 : 19|1@1+ (1,0) [0|1] "" Vector__XXX
 SG_ PMR_a018_w0 m18 : 16|16@1+ (1,0) [0|65535] "" Vector__XXX
 SG_ PMR_a018_w1 m18 : 32|16@1+ (1,0) [0|65535] "" Vector__XXX
 SG_ PMR_a018_w2 m18 : 48|16@1+ (1,0) [0|65535] "" Vector__XXX
 SG_ PMR_a019_statorTemp1 m19 : 16|16@1- (0.1,0) [-3276.8|3276.7] "DegC" Vector__XXX
 SG_ PMR_a019_statorTslope1 m19 : 32|16@1- (0.1,0) [-3276.8|3276.7] "DegC/s" Vector__XXX
 SG_ PMR_a025_sccReset m25 : 16|1@1+ (1,0) [0|1] "" Vector__XXX
 SG_ PMR_a025_hibernate m25 : 17|1@1+ (1,0) [0|1] "" Vector__XXX
 SG_ PMR_a025_hwBist m25 : 18|1@1+ (1,0) [0|1] "" Vector__XXX
 SG_ PMR_a025_nmiWatchdog m25 : 19|1@1+ (1,0) [0|1] "" Vector__XXX
 SG_ PMR_a025_watchdog m25 : 20|1@1+ (1,0) [0|1] "" Vector__XXX
 SG_ PMR_a025_clockFailNmi m25 : 21|1@1+ (1,0) [0|1] "" Vector__XXX
 SG_ PMR_a025_ramUncErrorNmi m25 : 22|1@1+ (1,0) [0|1] "" Vector__XXX
 SG_ PMR_a025_flashUncErrorNmi m25 : 23|1@1+ (1,0) [0|1] "" Vector__XXX
 SG_ PMR_a025_cpu1signMismatchNmi m25 : 24|1@1+ (1,0) [0|1] "" Vector__XXX
 SG_ PMR_a025_cpu2signMismatchNmi m25 : 25|1@1+ (1,0) [0|1] "" Vector__XXX
 SG_ PMR_a025_pieVectErrorNmi m25 : 26|1@1+ (1,0) [0|1] "" Vector__XXX
 SG_ PMR_a025_sysDbgNmi m25 : 27|1@1+ (1,0) [0|1] "" Vector__XXX
 SG_ PMR_a025_rlNmi m25 : 28|1@1+ (1,0) [0|1] "" Vector__XXX
 SG_ PMR_a025_ovfNmi m25 : 29|1@1+ (1,0) [0|1] "" Vector__XXX
 SG_ PMR_a025_possibleSafetyICReset m25 : 30|1@1+ (1,0) [0|1] "" Vector__XXX
 SG_ PMR_a025_powerOnReset m25 : 31|1@1+ (1,0) [0|1] "" Vector__XXX
 SG_ PMR_a025_watchdogTimer0 m25 : 32|1@1+ (1,0) [0|1] "" Vector__XXX
 SG_ PMR_a025_watchdogTimer1 m25 : 33|1@1+ (1,0) [0|1] "" Vector__XXX
 SG_ PMR_a025_watchdogTimer2 m25 : 34|1@1+ (1,0) [0|1] "" Vector__XXX
 SG_ PMR_a025_watchdogTimer3 m25 : 35|1@1+ (1,0) [0|1] "" Vector__XXX
 SG_ PMR_a025_warmResetReq m25 : 36|1@1+ (1,0) [0|1] "" Vector__XXX
 SG_ PMR_a025_externalPadReset m25 : 37|1@1+ (1,0) [0|1] "" Vector__XXX
 SG_ PMR_a025_hwSecModuleWatchdogTime m25 : 38|1@1+ (1,0) [0|1] "" Vector__XXX
 SG_ PMR_a025_debugReset m25 : 39|1@1+ (1,0) [0|1] "" Vector__XXX
 SG_ PMR_a025_tempSense0 m25 : 40|1@1+ (1,0) [0|1] "" Vector__XXX
 SG_ PMR_a025_tempSense1 m25 : 41|1@1+ (1,0) [0|1] "" Vector__XXX
 SG_ PMR_a026_reason m26 : 16|1@1+ (1,0) [0|1] "" Vector__XXX
 SG_ PMR_a026_isrCount20kHz m26 : 17|5@1+ (1,0) [0|31] "" Vector__XXX
 SG_ PMR_a026_isrCount1kHz m26 : 22|4@1+ (1,0) [0|15] "" Vector__XXX
 SG_ PMR_a026_switchingActive m26 : 26|1@1+ (1,0) [0|1] "" Vector__XXX
 SG_ PMR_a026_systemStackOvf m26 : 27|1@1+ (1,0) [0|1] "" Vector__XXX
 SG_ PMR_a026_controlStackOvf m26 : 28|1@1+ (1,0) [0|1] "" Vector__XXX
 SG_ PMR_a026_idleStackOvf m26 : 29|1@1+ (1,0) [0|1] "" Vector__XXX
 SG_ PMR_a026_eepStackOvf m26 : 30|1@1+ (1,0) [0|1] "" Vector__XXX
 SG_ PMR_a026_immStackOvf m26 : 31|1@1+ (1,0) [0|1] "" Vector__XXX
 SG_ PMR_a026_xdcErrorIdMSW m26 : 32|10@1+ (1,0) [0|1023] "" Vector__XXX
 SG_ PMR_a026_xdcErrorArg1 m26 : 42|22@1- (1,0) [-2097152|2097151] "" Vector__XXX
 SG_ PMR_a032_w0 m32 : 16|16@1+ (1,0) [0|65535] "" Vector__XXX
 SG_ PMR_a032_w1 m32 : 32|16@1+ (1,0) [0|65535] "" Vector__XXX
 SG_ PMR_a032_w2 m32 : 48|16@1+ (1,0) [0|65535] "" Vector__XXX
 SG_ PMR_a033_state m33 : 16|4@1+ (1,0) [0|15] "" Vector__XXX
 SG_ PMR_a033_failReason m33 : 20|3@1+ (1,0) [0|7] "" Vector__XXX
 SG_ PMR_a033_DSADC_Ia m33 : 24|16@1- (0.0939,0) [-3076.9152|3076.8213] "A" Vector__XXX
 SG_ PMR_a033_DSADC_Ib m33 : 40|16@1- (0.0939,0) [-3076.9152|3076.8213] "A" Vector__XXX
 SG_ PMR_a036_timeSinceTxHWI m36 : 16|6@1+ (64,0) [0|4032] "us" Vector__XXX
 SG_ PMR_a036_timeSinceRxHWI m36 : 22|6@1+ (64,0) [0|4032] "us" Vector__XXX
 SG_ PMR_a036_timeSince100HzTxSWI m36 : 28|6@1+ (0.32,0) [0|20.16] "ms" Vector__XXX
 SG_ PMR_a036_timeSince1kHzCLK m36 : 34|6@1+ (32,0) [0|2016] "us" Vector__XXX
 SG_ PMR_a036_timeSince1kHzSWI m36 : 40|6@1+ (32,0) [0|2016] "us" Vector__XXX
 SG_ PMR_a036_timeSinceIdle m36 : 46|6@1+ (0.16,0) [0|10.08] "ms" Vector__XXX
 SG_ PMR_a036_ovfStackId m36 : 52|4@1+ (1,0) [0|14] "" Vector__XXX
 SG_ PMR_a036_inTxISR m36 : 56|1@1+ (1,0) [0|1] "" Vector__XXX
 SG_ PMR_a036_inTxHWI m36 : 57|1@1+ (1,0) [0|1] "" Vector__XXX
 SG_ PMR_a036_inRxHWI m36 : 58|1@1+ (1,0) [0|1] "" Vector__XXX
 SG_ PMR_a036_in1kHzSWI m36 : 59|1@1+ (1,0) [0|1] "" Vector__XXX
 SG_ PMR_a036_in1kHzCLK m36 : 60|1@1+ (1,0) [0|1] "" Vector__XXX
 SG_ PMR_a036_in100HzCLK m36 : 61|1@1+ (1,0) [0|1] "" Vector__XXX
 SG_ PMR_a036_in10HzCLK m36 : 62|1@1+ (1,0) [0|1] "" Vector__XXX
 SG_ PMR_a036_in1HzCLK m36 : 63|1@1+ (1,0) [0|1] "" Vector__XXX
 SG_ PMR_a037_hvpFaults m37 : 16|1@1+ (1,0) [0|1] "" Vector__XXX
 SG_ PMR_a039_DIS_status m39 : 16|1@1+ (1,0) [0|1] "" Vector__XXX
 SG_ PMR_a039_DIS_torque m39 : 17|1@1+ (1,0) [0|1] "" Vector__XXX
 SG_ PMR_a039_messageId m39 : 24|16@1+ (1,0) [0|65535] "" Vector__XXX
 SG_ PMR_a040_PM_state m40 : 16|1@1+ (1,0) [0|1] "" Vector__XXX
 SG_ PMR_a040_messageId m40 : 24|16@1+ (1,0) [0|65535] "" Vector__XXX
 SG_ PMR_a040_PM_locState m40 : 40|1@1+ (1,0) [0|1] "" Vector__XXX
 SG_ PMR_a042_GTW_carConfig m42 : 16|1@1+ (1,0) [0|1] "" Vector__XXX
 SG_ PMR_a042_GTW_time m42 : 17|1@1+ (1,0) [0|1] "" Vector__XXX
 SG_ PMR_a042_GTW_drivetrainType m42 : 18|3@1+ (1,0) [0|7] "" Vector__XXX
 SG_ PMR_a042_expectedPerformanceCfg m42 : 21|3@1+ (1,0) [0|7] "" Vector__XXX
 SG_ PMR_a042_gearControl m42 : 24|1@1+ (1,0) [0|1] "" Vector__XXX
 SG_ PMR_a053_LVPowerState m53 : 16|1@1+ (1,0) [0|1] "" Vector__XXX
 SG_ PMR_a053_coolant m53 : 17|1@1+ (1,0) [0|1] "" Vector__XXX
 SG_ PMR_a053_vcleftSwitchStatus m53 : 18|1@1+ (1,0) [0|1] "" Vector__XXX
 SG_ PMR_a053_restraintStatus m53 : 19|1@1+ (1,0) [0|1] "" Vector__XXX
 SG_ PMR_a053_sensors m53 : 20|1@1+ (1,0) [0|1] "" Vector__XXX
 SG_ PMR_a054_uiPowertrainControl m54 : 16|1@1+ (1,0) [0|1] "" Vector__XXX
 SG_ PMR_a054_uiChassisControl m54 : 17|1@1+ (1,0) [0|1] "" Vector__XXX
 SG_ PMR_a054_uiCruiseControl m54 : 18|1@1+ (1,0) [0|1] "" Vector__XXX
 SG_ PMR_a054_uiTrackModeSettings m54 : 19|1@1+ (1,0) [0|1] "" Vector__XXX
 SG_ PMR_a054_uiTPMSRCPSetting m54 : 20|1@1+ (1,0) [0|1] "" Vector__XXX
 SG_ PMR_a055_motorRPM m55 : 16|16@1- (1,0) [-32768|32767] "RPM" Vector__XXX
 SG_ PMR_a055_phaseAngle m55 : 32|8@1+ (0.00308,0) [0|0.7854] "1" Vector__XXX
 SG_ PMR_a055_commonGain m55 : 40|8@1+ (0.02,0) [0|5.1] "1" Vector__XXX
 SG_ PMR_a055_notReady m55 : 48|1@1+ (1,0) [0|1] "" Vector__XXX
 SG_ PMR_a055_noCarrier m55 : 49|1@1+ (1,0) [0|1] "" Vector__XXX
 SG_ PMR_a055_phaseOutOfSpec m55 : 50|1@1+ (1,0) [0|1] "" Vector__XXX
 SG_ PMR_a055_diElecAngleMismatch m55 : 51|1@1+ (1,0) [0|1] "" Vector__XXX
 SG_ PMR_a055_diSpeedMismatch m55 : 52|1@1+ (1,0) [0|1] "" Vector__XXX
 SG_ PMR_a055_claMIA m55 : 53|1@1+ (1,0) [0|1] "" Vector__XXX
 SG_ PMR_a055_diMIA m55 : 54|1@1+ (1,0) [0|1] "" Vector__XXX
 SG_ PMR_a055_diElecAngleMismatchWarn m55 : 55|1@1+ (1,0) [0|1] "" Vector__XXX
 SG_ PMR_a058_hvilCurrent m58 : 16|8@1+ (0.1,0) [0|25.5] "mA" Vector__XXX
 SG_ PMR_a061_diIpcVersion m61 : 16|8@1+ (1,0) [0|255] "" Vector__XXX
 SG_ PMR_a061_pmIpcVersion m61 : 24|8@1+ (1,0) [0|255] "" Vector__XXX
 SG_ PMR_a062_address m62 : 16|32@1+ (1,0) [0|4294967295] "" Vector__XXX
 SG_ PMR_a062_errorType m62 : 48|4@1+ (1,0) [0|15] "" Vector__XXX
 SG_ PMR_a062_detectedByRamScrub m62 : 52|1@1+ (1,0) [0|1] "" Vector__XXX
 SG_ PMR_a064_interventionType m64 : 16|4@1+ (1,0) [0|15] "" Vector__XXX
 SG_ PMR_a064_torqueCmdState m64 : 20|4@1+ (1,0) [1|15] "" Vector__XXX
 SG_ PMR_a064_shortDetectedByDI m64 : 24|1@1+ (1,0) [0|1] "" Vector__XXX
 SG_ PMR_a064_UI_stoppingMode m64 : 25|2@1+ (1,0) [0|3] "" Vector__XXX
 SG_ PMR_a064_diCrsState m64 : 27|3@1+ (1,0) [0|7] "" Vector__XXX
 SG_ PMR_a064_pmCrsState m64 : 32|3@1+ (1,0) [0|7] "" Vector__XXX
 SG_ PMR_a082_faultAddress m82 : 16|32@1+ (1,0) [0|4294967295] "" Vector__XXX
 SG_ PMR_a082_isWriteNotRead m82 : 48|1@1+ (1,0) [0|1] "" Vector__XXX
 SG_ PMR_a084_faultAddress m84 : 16|32@1+ (1,0) [0|4294967295] "" Vector__XXX
 SG_ PMR_a084_firewallId m84 : 48|5@1+ (1,0) [0|31] "" Vector__XXX
 SG_ PMR_a084_privId m84 : 56|4@1+ (1,0) [0|15] "" Vector__XXX
 SG_ PMR_a084_ns m84 : 60|1@1+ (1,0) [0|1] "" Vector__XXX
 SG_ PMR_a084_faultType m84 : 61|3@1+ (1,0) [0|7] "" Vector__XXX
 SG_ PMR_a092_pllClockSource m92 : 16|2@1+ (1,0) [0|3] "" Vector__XXX
 SG_ PMR_a095_wwdErrIntFlag m95 : 16|1@1+ (1,0) [0|1] "" Vector__XXX
 SG_ PMR_a095_fwdErrIntFlag m95 : 17|1@1+ (1,0) [0|1] "" Vector__XXX
 SG_ PMR_a095_errMissStsFlag m95 : 18|1@1+ (1,0) [0|1] "" Vector__XXX
 SG_ PMR_a095_preRegulatorOT m95 : 19|1@1+ (1,0) [0|1] "" Vector__XXX
 SG_ PMR_a095_ucLdoOT m95 : 20|1@1+ (1,0) [0|1] "" Vector__XXX
 SG_ PMR_a095_monitoringOT m95 : 21|1@1+ (1,0) [0|1] "" Vector__XXX
 SG_ PMR_a095_preRegulatorVoltShort m95 : 22|1@1+ (1,0) [0|1] "" Vector__XXX
 SG_ PMR_a095_ucLdoShort m95 : 23|1@1+ (1,0) [0|1] "" Vector__XXX
 SG_ PMR_a095_standbyLdoShort m95 : 24|1@1+ (1,0) [0|1] "" Vector__XXX
 SG_ PMR_a095_coreVoltShort m95 : 25|1@1+ (1,0) [0|1] "" Vector__XXX
 SG_ PMR_a095_preRegulatorOV m95 : 26|1@1+ (1,0) [0|1] "" Vector__XXX
 SG_ PMR_a095_ucLdoOV m95 : 27|1@1+ (1,0) [0|1] "" Vector__XXX
 SG_ PMR_a095_standbyLdoOV m95 : 28|1@1+ (1,0) [0|1] "" Vector__XXX
 SG_ PMR_a095_coreOV m95 : 29|1@1+ (1,0) [0|1] "" Vector__XXX
 SG_ PMR_a095_voltRefOV m95 : 30|1@1+ (1,0) [0|1] "" Vector__XXX
 SG_ PMR_a095_ucLdoUV m95 : 31|1@1+ (1,0) [0|1] "" Vector__XXX
 SG_ PMR_a095_standbyLdoUV m95 : 32|1@1+ (1,0) [0|1] "" Vector__XXX
 SG_ PMR_a095_coreUV m95 : 33|1@1+ (1,0) [0|1] "" Vector__XXX
 SG_ PMR_a095_supplyVoltOV m95 : 34|1@1+ (1,0) [0|1] "" Vector__XXX
 SG_ PMR_a095_bandgapComparatorUV m95 : 35|1@1+ (1,0) [0|1] "" Vector__XXX
 SG_ PMR_a095_bandgapComparatorOV m95 : 36|1@1+ (1,0) [0|1] "" Vector__XXX
 SG_ PMR_a095_biasCurrentTooLow m95 : 37|1@1+ (1,0) [0|1] "" Vector__XXX
 SG_ PMR_a095_biasCurrentTooHigh m95 : 38|1@1+ (1,0) [0|1] "" Vector__XXX
 SG_ PMR_a095_safetyICstate m95 : 40|3@1+ (1,0) [0|7] "" Vector__XXX
 SG_ PMR_a095_motorRPM m95 : 43|12@1- (10,0) [-20480|20470] "RPM" Vector__XXX
 SG_ PMR_a095_wwdErrCounter m95 : 56|4@1+ (1,0) [0|15] "" Vector__XXX
 SG_ PMR_a095_fwdErrCounter m95 : 60|4@1+ (1,0) [0|15] "" Vector__XXX
 SG_ PMR_a100_index1kHzPeriodic m100 : 16|8@1+ (1,0) [0|255] "" Vector__XXX
 SG_ PMR_a100_index100HzPeriodic m100 : 24|8@1+ (1,0) [0|255] "" Vector__XXX
 SG_ PMR_a100_index10HzPeriodic m100 : 32|8@1+ (1,0) [0|255] "" Vector__XXX
 SG_ PMR_a100_indexSWI m100 : 40|8@1+ (1,0) [0|255] "" Vector__XXX
 SG_ PMR_a100_eepEvent m100 : 48|8@1+ (1,0) [0|255] "" Vector__XXX
 SG_ PMR_a100_module500HzActive m100 : 56|1@1+ (1,0) [0|1] "" Vector__XXX
 SG_ PMR_a100_module50HzActive m100 : 57|1@1+ (1,0) [0|1] "" Vector__XXX
 SG_ PMR_a100_module1HzActive m100 : 58|1@1+ (1,0) [0|1] "" Vector__XXX
 SG_ PMR_a100_task10HzActive m100 : 59|1@1+ (1,0) [0|1] "" Vector__XXX
 SG_ PMR_a100_taskUdsActive m100 : 60|1@1+ (1,0) [0|1] "" Vector__XXX
 SG_ PMR_a101_VDDA18_ref33_uv m101 : 16|1@1+ (1,0) [0|1] "" Vector__XXX
 SG_ PMR_a101_VBGAP09_ov m101 : 17|1@1+ (1,0) [0|1] "" Vector__XXX
 SG_ PMR_a101_VBGAP09_uv m101 : 18|1@1+ (1,0) [0|1] "" Vector__XXX
 SG_ PMR_a101_VDDA18_refBGAP_ov m101 : 19|1@1+ (1,0) [0|1] "" Vector__XXX
 SG_ PMR_a101_VDDA18_refBGAP_uv m101 : 20|1@1+ (1,0) [0|1] "" Vector__XXX
 SG_ PMR_a101_VDD12_ov m101 : 21|1@1+ (1,0) [0|1] "" Vector__XXX
 SG_ PMR_a101_VDD12_uv m101 : 22|1@1+ (1,0) [0|1] "" Vector__XXX
 SG_ PMR_a101_VDDSBIO_ov m101 : 23|1@1+ (1,0) [0|1] "" Vector__XXX
 SG_ PMR_a101_VDDSBIO_uv m101 : 24|1@1+ (1,0) [0|1] "" Vector__XXX
 SG_ PMR_a101_VSYS_MON_uv m101 : 25|1@1+ (1,0) [0|1] "" Vector__XXX
 SG_ PMR_a101_VDDA33_uv m101 : 26|1@1+ (1,0) [0|1] "" Vector__XXX
 SG_ PMR_a101_ADC0_REF_ov m101 : 27|1@1+ (1,0) [0|1] "" Vector__XXX
 SG_ PMR_a101_ADC0_REF_uv m101 : 28|1@1+ (1,0) [0|1] "" Vector__XXX
 SG_ PMR_a101_ADC12_REF_ov m101 : 29|1@1+ (1,0) [0|1] "" Vector__XXX
 SG_ PMR_a101_ADC12_REF_uv m101 : 30|1@1+ (1,0) [0|1] "" Vector__XXX
 SG_ PMR_a101_ADC34_REF_ov m101 : 31|1@1+ (1,0) [0|1] "" Vector__XXX
 SG_ PMR_a101_ADC34_REF_uv m101 : 32|1@1+ (1,0) [0|1] "" Vector__XXX
 SG_ PMR_a101_ADCR01_REF_ov m101 : 33|1@1+ (1,0) [0|1] "" Vector__XXX
 SG_ PMR_a101_ADCR01_REF_uv m101 : 34|1@1+ (1,0) [0|1] "" Vector__XXX

BO_ 902 PMR_alertMatrix: 8 PMR
 SG_ PMR_matrixIndex M : 0|4@1+ (1,0) [0|15] "" Vector__XXX
 SG_ PMR_a001_absoluteTorque m0 : 4|1@1+ (1,0) [0|1] "" Vector__XXX
 SG_ PMR_a002_excessiveAccelTorque m0 : 5|1@1+ (1,0) [0|1] "" Vector__XXX
 SG_ PMR_a003_excessiveReversalTorque m0 : 6|1@1+ (1,0) [0|1] "" Vector__XXX
 SG_ PMR_a004_excessiveDecelTorque m0 : 7|1@1+ (1,0) [0|1] "" Vector__XXX
 SG_ PMR_a005_torqueInNeutralOrPark m0 : 8|1@1+ (1,0) [0|1] "" Vector__XXX
 SG_ PMR_a006_underTorqueCheck m0 : 9|1@1+ (1,0) [0|1] "" Vector__XXX
 SG_ PMR_a008_memoryError m0 : 11|1@1+ (1,0) [0|1] "" Vector__XXX
 SG_ PMR_a010_diMIA m0 : 13|1@1+ (1,0) [0|1] "" Vector__XXX
 SG_ PMR_a011_phaseCurrentIrrational m0 : 14|1@1+ (1,0) [0|1] "" Vector__XXX
 SG_ PMR_a012_canDataBusA m0 : 15|1@1+ (1,0) [0|1] "" Vector__XXX
 SG_ PMR_a013_canHardwareBusA m0 : 16|1@1+ (1,0) [0|1] "" Vector__XXX
 SG_ PMR_a017_brakeMIA m0 : 20|1@1+ (1,0) [0|1] "" Vector__XXX
 SG_ PMR_a018_encoderIrrational m0 : 21|1@1+ (1,0) [0|1] "" Vector__XXX
 SG_ PMR_a019_statorTempIrrational m0 : 22|1@1+ (1,0) [0|1] "" Vector__XXX
 SG_ PMR_a025_unintendedReset m0 : 28|1@1+ (1,0) [0|1] "" Vector__XXX
 SG_ PMR_a026_diHeartBeatMIA m0 : 29|1@1+ (1,0) [0|1] "" Vector__XXX
 SG_ PMR_a027_torqueEstimationOutOfBo m0 : 30|1@1+ (1,0) [0|1] "" Vector__XXX
 SG_ PMR_a028_torqueCmdError m0 : 31|1@1+ (1,0) [0|1] "" Vector__XXX
 SG_ PMR_a031_highStackUsage m0 : 34|1@1+ (1,0) [0|1] "" Vector__XXX
 SG_ PMR_a032_registerConfigError m0 : 35|1@1+ (1,0) [0|1] "" Vector__XXX
 SG_ PMR_a033_selfTest m0 : 36|1@1+ (1,0) [0|1] "" Vector__XXX
 SG_ PMR_a034_trqCrossCheck m0 : 37|1@1+ (1,0) [0|1] "" Vector__XXX
 SG_ PMR_a035_udsTransactionInitiated m0 : 38|1@1+ (1,0) [0|1] "" Vector__XXX
 SG_ PMR_a036_preWatchdog m0 : 39|1@1+ (1,0) [0|1] "" Vector__XXX
 SG_ PMR_a037_hvpMIA m0 : 40|1@1+ (1,0) [0|1] "" Vector__XXX
 SG_ PMR_a039_disMIA m0 : 42|1@1+ (1,0) [0|1] "" Vector__XXX
 SG_ PMR_a040_pmMIA m0 : 43|1@1+ (1,0) [0|1] "" Vector__XXX
 SG_ PMR_a042_gtwMIA m0 : 45|1@1+ (1,0) [0|1] "" Vector__XXX
 SG_ PMR_a045_motorMovementDetected m0 : 48|1@1+ (1,0) [0|1] "" Vector__XXX
 SG_ PMR_a053_vcfrontMIA m0 : 56|1@1+ (1,0) [0|1] "" Vector__XXX
 SG_ PMR_a054_uiMIA m0 : 57|1@1+ (1,0) [0|1] "" Vector__XXX
 SG_ PMR_a055_resolver m0 : 58|1@1+ (1,0) [0|1] "" Vector__XXX
 SG_ PMR_a056_canHardwareBusB m0 : 59|1@1+ (1,0) [0|1] "" Vector__XXX
 SG_ PMR_a057_canDataBusB m0 : 60|1@1+ (1,0) [0|1] "" Vector__XXX
 SG_ PMR_a058_measuredHvilCurrentFroz m0 : 61|1@1+ (1,0) [0|1] "" Vector__XXX
 SG_ PMR_a061_DIPMVersionMismatch m1 : 4|1@1+ (1,0) [0|1] "" Vector__XXX
 SG_ PMR_a062_eccError m1 : 5|1@1+ (1,0) [0|1] "" Vector__XXX
 SG_ PMR_a064_torqueIntervention m1 : 7|1@1+ (1,0) [0|1] "" Vector__XXX
 SG_ PMR_a080_exceptionPrefetchAbort m1 : 23|1@1+ (1,0) [0|1] "" Vector__XXX
 SG_ PMR_a081_exceptionDataAbort m1 : 24|1@1+ (1,0) [0|1] "" Vector__XXX
 SG_ PMR_a082_exceptionDataAbort2 m1 : 25|1@1+ (1,0) [0|1] "" Vector__XXX
 SG_ PMR_a083_ahbWriteError m1 : 26|1@1+ (1,0) [0|1] "" Vector__XXX
 SG_ PMR_a084_exceptionMpuFirewall m1 : 27|1@1+ (1,0) [0|1] "" Vector__XXX
 SG_ PMR_a086_exceptionUndefinedInstr m1 : 29|1@1+ (1,0) [0|1] "" Vector__XXX
 SG_ PMR_a092_xtalOscillator m1 : 35|1@1+ (1,0) [0|1] "" Vector__XXX
 SG_ PMR_a094_safetyICWarn m1 : 37|1@1+ (1,0) [0|1] "" Vector__XXX
 SG_ PMR_a095_safetyICFault m1 : 38|1@1+ (1,0) [0|1] "" Vector__XXX
 SG_ PMR_a096_safetyICDebug m1 : 39|1@1+ (1,0) [0|1] "" Vector__XXX
 SG_ PMR_a097_lowFlowAlmostTripped m1 : 40|1@1+ (1,0) [0|1] "" Vector__XXX
 SG_ PMR_a100_diTraceInfo1 m1 : 43|1@1+ (1,0) [0|1] "" Vector__XXX
 SG_ PMR_a101_hwVoltageMonitorTrip m1 : 44|1@1+ (1,0) [0|1] "" Vector__XXX
 SG_ PMR_a102_ipcFluidTempHigh m1 : 45|1@1+ (1,0) [0|1] "" Vector__XXX
 SG_ PMR_a114_ramScrubTimedOut m1 : 57|1@1+ (1,0) [0|1] "" Vector__XXX
 SG_ PMR_a121_unintendedReset2 m2 : 4|1@1+ (1,0) [0|1] "" Vector__XXX

BO_ 1748 PMR_info: 8 PMR
 SG_ PMR_infoIndex M : 0|8@1+ (1,0) [0|255] "" Vector__XXX
 SG_ PMR_buildType m10 : 8|8@1+ (1,0) [0|255] "" Vector__XXX
 SG_ PMR_buildConfigurationId m10 : 16|16@1+ (1,0) [0|65535] "" Vector__XXX
 SG_ PMR_hardwareId m10 : 32|8@1+ (1,0) [0|252] "" Vector__XXX
 SG_ PMR_deviceFused m10 : 40|1@1+ (1,0) [0|1] "" Vector__XXX
 SG_ PMR_componentId m10 : 48|16@1+ (1,0) [0|65535] "" Vector__XXX
 SG_ PMR_pcbaId m11 : 16|8@1+ (1,0) [0|255] "" Vector__XXX
 SG_ PMR_assemblyId m11 : 24|8@1+ (1,0) [0|255] "" Vector__XXX
 SG_ PMR_usageId m11 : 32|16@1+ (1,0) [0|65535] "" Vector__XXX
 SG_ PMR_subUsageId m11 : 48|16@1+ (1,0) [0|65535] "" Vector__XXX
 SG_ PMR_applicationCrc m13 : 32|32@1+ (1,0) [0|4294967295] "" Vector__XXX
 SG_ PMR_appGitHash m17 : 8|56@1+ (1,0) [0|7.20575940379e+16] "" Vector__XXX
 SG_ PMR_bootGitHash m18 : 8|56@1+ (1,0) [0|7.20575940379e+16] "" Vector__XXX
 SG_ PMR_platformTyp m19 : 8|8@1+ (1,0) [0|255] "" Vector__XXX
 SG_ PMR_udsProtocolVersion m20 : 8|8@1+ (1,0) [0|255] "" Vector__XXX
 SG_ PMR_bootloaderCrc m20 : 32|32@1+ (1,0) [0|4294967295] "" Vector__XXX

BO_ 2023 PMR_mfgData: 7 PMR
 SG_ PMR_processorDieIdLot : 0|24@1+ (1,0) [0|16777215] "" Vector__XXX
 SG_ PMR_processorDieIdWafer : 24|8@1+ (1,0) [0|255] "" Vector__XXX
 SG_ PMR_processorDieIdX : 32|12@1+ (1,0) [0|4095] "" Vector__XXX
 SG_ PMR_processorDieIdY : 44|12@1+ (1,0) [0|4095] "" Vector__XXX

BO_ 1556 PMR_udsResponse: 8 PMR
 SG_ PMR_udsResponseData : 7|64@0+ (1,0) [0|1.84467440737e+19] "" Vector__XXX

BO_ 1444 PM_alertLog: 8 PM
 SG_ PM_alertID M : 0|7@1+ (1,0) [0|127] "" Vector__XXX
 SG_ PM_alertState : 15|1@1+ (1,0) [0|1] "" Vector__XXX
 SG_ PM_a001_w0 m1 : 16|16@1+ (1,0) [0|65535] "" Vector__XXX
 SG_ PM_a001_w1 m1 : 32|16@1+ (1,0) [0|65535] "" Vector__XXX
 SG_ PM_a001_w2 m1 : 48|16@1+ (1,0) [0|65535] "" Vector__XXX
 SG_ PM_a002_torqueAverage m2 : 16|1@1+ (1,0) [0|1] "" Vector__XXX
 SG_ PM_a002_torqueWindow m2 : 17|1@1+ (1,0) [0|1] "" Vector__XXX
 SG_ PM_a002_torqueMeasured m2 : 18|13@1- (2,0) [-8192|8190] "Nm" Vector__XXX
 SG_ PM_a002_torqueAccelAverage m2 : 32|13@1- (2,0) [-8192|8190] "Nm" Vector__XXX
 SG_ PM_a002_torqueAccelWindow m2 : 48|13@1- (2,0) [-8192|8190] "Nm" Vector__XXX
 SG_ PM_a003_torqueMeasured m3 : 16|13@1- (2,0) [-8192|8190] "Nm" Vector__XXX
 SG_ PM_a003_torqueCommanded m3 : 32|13@1- (2,0) [-8192|8190] "Nm" Vector__XXX
 SG_ PM_a003_reverseGear m3 : 45|1@1+ (1,0) [0|1] "" Vector__XXX
 SG_ PM_a003_pedalPos m3 : 48|8@1+ (0.4,0) [0|102] "%" Vector__XXX
 SG_ PM_a003_zeroPointPedal m3 : 56|8@1+ (0.4,0) [0|102] "%" Vector__XXX
 SG_ PM_a004_torqueAverage m4 : 16|1@1+ (1,0) [0|1] "" Vector__XXX
 SG_ PM_a004_torqueWindow m4 : 17|1@1+ (1,0) [0|1] "" Vector__XXX
 SG_ PM_a004_torqueMeasured m4 : 18|13@1- (2,0) [-8192|8190] "Nm" Vector__XXX
 SG_ PM_a004_torqueDecelAverage m4 : 32|13@1- (2,0) [-8192|8190] "Nm" Vector__XXX
 SG_ PM_a004_torqueDecelWindow m4 : 48|13@1- (2,0) [-8192|8190] "Nm" Vector__XXX
 SG_ PM_a005_torqueReason m5 : 16|2@1+ (1,0) [0|3] "" Vector__XXX
 SG_ PM_a005_torqueMeasured m5 : 18|13@1- (2,0) [-8192|8190] "Nm" Vector__XXX
 SG_ PM_a005_iDQmagnitude m5 : 32|16@1- (0.0939,0) [-3076.9152|3076.8213] "A" Vector__XXX
 SG_ PM_a006_unknownGearAllowed m6 : 16|1@1+ (1,0) [0|1] "" Vector__XXX
 SG_ PM_a006_parkGearAllowed m6 : 17|1@1+ (1,0) [0|1] "" Vector__XXX
 SG_ PM_a006_reverseGearAllowed m6 : 18|1@1+ (1,0) [0|1] "" Vector__XXX
 SG_ PM_a006_neutralGearAllowed m6 : 19|1@1+ (1,0) [0|1] "" Vector__XXX
 SG_ PM_a006_driveGearAllowed m6 : 20|1@1+ (1,0) [0|1] "" Vector__XXX
 SG_ PM_a006_shiftState m6 : 21|3@1+ (1,0) [0|6] "" Vector__XXX
 SG_ PM_a006_brakePedalPress m6 : 24|1@1+ (1,0) [0|1] "" Vector__XXX
 SG_ PM_a006_accelPedalBelowLimit m6 : 25|1@1+ (1,0) [0|1] "" Vector__XXX
 SG_ PM_a006_allowReverseShiftSpeed m6 : 26|1@1+ (1,0) [0|1] "" Vector__XXX
 SG_ PM_a006_allowDriveShiftSpeed m6 : 27|1@1+ (1,0) [0|1] "" Vector__XXX
 SG_ PM_a006_requireAccelPedalCheckSp m6 : 28|1@1+ (1,0) [0|1] "" Vector__XXX
 SG_ PM_a006_requireParkSpeed m6 : 29|1@1+ (1,0) [0|1] "" Vector__XXX
 SG_ PM_a006_stalkCommandP m6 : 30|1@1+ (1,0) [0|1] "" Vector__XXX
 SG_ PM_a006_stalkCommandR m6 : 31|1@1+ (1,0) [0|1] "" Vector__XXX
 SG_ PM_a006_stalkCommandN m6 : 32|1@1+ (1,0) [0|1] "" Vector__XXX
 SG_ PM_a006_stalkCommandD m6 : 33|1@1+ (1,0) [0|1] "" Vector__XXX
 SG_ PM_a006_unsecuredNeutralRequest m6 : 34|1@1+ (1,0) [0|1] "" Vector__XXX
 SG_ PM_a006_recentGearChange m6 : 35|1@1+ (1,0) [0|1] "" Vector__XXX
 SG_ PM_a006_smartShiftCommandD m6 : 36|1@1+ (1,0) [0|1] "" Vector__XXX
 SG_ PM_a006_smartShiftCommandR m6 : 37|1@1+ (1,0) [0|1] "" Vector__XXX
 SG_ PM_a006_driverSeatbeltBuckled m6 : 38|1@1+ (1,0) [0|1] "" Vector__XXX
 SG_ PM_a006_secGearSelRisingEdgeR m6 : 39|1@1+ (1,0) [0|1] "" Vector__XXX
 SG_ PM_a006_secGearSelRisingEdgeN m6 : 40|1@1+ (1,0) [0|1] "" Vector__XXX
 SG_ PM_a006_secGearSelRisingEdgeD m6 : 41|1@1+ (1,0) [0|1] "" Vector__XXX
 SG_ PM_a007_IBST_party1 m7 : 16|1@1+ (1,0) [0|1] "" Vector__XXX
 SG_ PM_a007_BUS1_IBST_status m7 : 17|1@1+ (1,0) [0|1] "" Vector__XXX
 SG_ PM_a007_BUS2_IBST_status m7 : 18|1@1+ (1,0) [0|1] "" Vector__XXX
 SG_ PM_a009_ESP_brakeTorque m9 : 16|1@1+ (1,0) [0|1] "" Vector__XXX
 SG_ PM_a009_ESP_motorLimits m9 : 17|1@1+ (1,0) [0|1] "" Vector__XXX
 SG_ PM_a009_ESP_offsets m9 : 18|1@1+ (1,0) [0|1] "" Vector__XXX
 SG_ PM_a009_ESP_party3 m9 : 19|1@1+ (1,0) [0|1] "" Vector__XXX
 SG_ PM_a009_ESP_status m9 : 20|1@1+ (1,0) [0|1] "" Vector__XXX
 SG_ PM_a009_ESP_wheelSpeeds m9 : 21|1@1+ (1,0) [0|1] "" Vector__XXX
 SG_ PM_a010_messageId m10 : 16|16@1+ (1,0) [0|65535] "" Vector__XXX
 SG_ PM_a010_DI_status m10 : 32|1@1+ (1,0) [0|1] "" Vector__XXX
 SG_ PM_a010_DI_torque m10 : 33|1@1+ (1,0) [0|1] "" Vector__XXX
 SG_ PM_a010_DI_slaveCommand m10 : 34|1@1+ (1,0) [0|1] "" Vector__XXX
 SG_ PM_a010_DI_locStatus m10 : 35|1@1+ (1,0) [0|1] "" Vector__XXX
 SG_ PM_a010_DI_speed m10 : 36|1@1+ (1,0) [0|1] "" Vector__XXX
 SG_ PM_a010_DI_systemStatus m10 : 37|1@1+ (1,0) [0|1] "" Vector__XXX
 SG_ PM_a010_DI_chassisControl m10 : 38|1@1+ (1,0) [0|1] "" Vector__XXX
 SG_ PM_a010_DI_chassisControl2 m10 : 39|1@1+ (1,0) [0|1] "" Vector__XXX
 SG_ PM_a010_vdcLeft m10 : 40|1@1+ (1,0) [0|1] "" Vector__XXX
 SG_ PM_a010_vdcRight m10 : 41|1@1+ (1,0) [0|1] "" Vector__XXX
 SG_ PM_a010_DI_vehicleEstimates m10 : 42|1@1+ (1,0) [0|1] "" Vector__XXX
 SG_ PM_a010_DI_brakeCommand m10 : 43|1@1+ (1,0) [0|1] "" Vector__XXX
 SG_ PM_a010_DI_autonomyHealth m10 : 44|1@1+ (1,0) [0|1] "" Vector__XXX
 SG_ PM_a010_DI_difCommand m10 : 45|1@1+ (1,0) [0|1] "" Vector__XXX
 SG_ PM_a010_DI_dirCommand m10 : 46|1@1+ (1,0) [0|1] "" Vector__XXX
 SG_ PM_a010_DI_dirVehicle m10 : 47|1@1+ (1,0) [0|1] "" Vector__XXX
 SG_ PM_a010_DI_locStatus2 m10 : 48|1@1+ (1,0) [0|1] "" Vector__XXX
 SG_ PM_a010_stalklessInterfaces m10 : 49|1@1+ (1,0) [0|1] "" Vector__XXX
 SG_ PM_a011_pmfHvilStatus m11 : 16|2@1+ (1,0) [0|2] "" Vector__XXX
 SG_ PM_a011_pmfStatusValid m11 : 18|1@1+ (1,0) [0|1] "" Vector__XXX
 SG_ PM_a011_pmrHvilStatus m11 : 19|2@1+ (1,0) [0|2] "" Vector__XXX
 SG_ PM_a011_pmrStatusValid m11 : 21|1@1+ (1,0) [0|1] "" Vector__XXX
 SG_ PM_a011_vehiclePowerState m11 : 22|2@1+ (1,0) [0|3] "" Vector__XXX
 SG_ PM_a011_hvilSystemStatus m11 : 24|2@1+ (1,0) [0|2] "" Vector__XXX
 SG_ PM_a014_track1Voltage m14 : 16|16@1+ (0.001,0) [0|65.535] "V" Vector__XXX
 SG_ PM_a014_track2Voltage m14 : 32|16@1+ (0.001,0) [0|65.535] "V" Vector__XXX
 SG_ PM_a014_accelErrorType m14 : 48|2@1+ (1,0) [1|3] "" Vector__XXX
 SG_ PM_a015_SCCM_rightStalk m15 : 16|1@1+ (1,0) [0|1] "" Vector__XXX
 SG_ PM_a016_BB_status m16 : 16|1@1+ (1,0) [0|1] "" Vector__XXX
 SG_ PM_a016_BB_brakeActuation m16 : 17|1@1+ (1,0) [0|1] "" Vector__XXX
 SG_ PM_a017_EPBL_status m17 : 16|1@1+ (1,0) [0|1] "" Vector__XXX
 SG_ PM_a017_EPBR_status m17 : 17|1@1+ (1,0) [0|1] "" Vector__XXX
 SG_ PM_a017_EPBL_autonomyHealth m17 : 18|1@1+ (1,0) [0|1] "" Vector__XXX
 SG_ PM_a017_EPBR_autonomyHealth m17 : 19|1@1+ (1,0) [0|1] "" Vector__XXX
 SG_ PM_a021_torque m21 : 16|1@1+ (1,0) [0|1] "" Vector__XXX
 SG_ PM_a021_capability m21 : 17|1@1+ (1,0) [0|1] "" Vector__XXX
 SG_ PM_a021_status m21 : 18|1@1+ (1,0) [0|1] "" Vector__XXX
 SG_ PM_a021_capability2 m21 : 19|1@1+ (1,0) [0|1] "" Vector__XXX
 SG_ PM_a021_power m21 : 20|1@1+ (1,0) [0|1] "" Vector__XXX
 SG_ PM_a022_torque m22 : 16|1@1+ (1,0) [0|1] "" Vector__XXX
 SG_ PM_a022_capability m22 : 17|1@1+ (1,0) [0|1] "" Vector__XXX
 SG_ PM_a022_status m22 : 18|1@1+ (1,0) [0|1] "" Vector__XXX
 SG_ PM_a022_capability2 m22 : 19|1@1+ (1,0) [0|1] "" Vector__XXX
 SG_ PM_a022_power m22 : 20|1@1+ (1,0) [0|1] "" Vector__XXX
 SG_ PM_a023_diCrsState m23 : 16|3@1+ (1,0) [0|7] "" Vector__XXX
 SG_ PM_a023_pmCrsState m23 : 19|3@1+ (1,0) [0|7] "" Vector__XXX
 SG_ PM_a023_crsFaultReason m23 : 24|5@1+ (1,0) [0|31] "" Vector__XXX
 SG_ PM_a023_crsCancelReason m23 : 29|4@1+ (1,0) [0|15] "" Vector__XXX
 SG_ PM_a023_cruiseTorquePed m23 : 33|11@1- (1,0) [-1024|1023] "Nm" Vector__XXX
 SG_ PM_a023_wheelSpdEstimateAbs m23 : 44|10@1+ (0.25,0) [0|255.75] "kph" Vector__XXX
 SG_ PM_a023_accelEstimateDis m23 : 54|10@1- (0.05,-4.7) [-30.3|20.85] "m/s^2" Vector__XXX
 SG_ PM_a025_powerOnReset m25 : 16|1@1+ (1,0) [0|1] "" Vector__XXX
 SG_ PM_a025_watchdogTimer0 m25 : 17|1@1+ (1,0) [0|1] "" Vector__XXX
 SG_ PM_a025_watchdogTimer1 m25 : 18|1@1+ (1,0) [0|1] "" Vector__XXX
 SG_ PM_a025_watchdogTimer2 m25 : 19|1@1+ (1,0) [0|1] "" Vector__XXX
 SG_ PM_a025_watchdogTimer3 m25 : 20|1@1+ (1,0) [0|1] "" Vector__XXX
 SG_ PM_a025_warmResetReq m25 : 21|1@1+ (1,0) [0|1] "" Vector__XXX
 SG_ PM_a025_externalPadReset m25 : 22|1@1+ (1,0) [0|1] "" Vector__XXX
 SG_ PM_a025_hwSecModuleWatchdogTimer m25 : 23|1@1+ (1,0) [0|1] "" Vector__XXX
 SG_ PM_a025_debugReset m25 : 24|1@1+ (1,0) [0|1] "" Vector__XXX
 SG_ PM_a025_tempSense0 m25 : 25|1@1+ (1,0) [0|1] "" Vector__XXX
 SG_ PM_a025_tempSense1 m25 : 26|1@1+ (1,0) [0|1] "" Vector__XXX
 SG_ PM_a026_reason m26 : 16|1@1+ (1,0) [0|1] "" Vector__XXX
 SG_ PM_a026_isrCount20kHz m26 : 17|5@1+ (1,0) [0|31] "" Vector__XXX
 SG_ PM_a026_isrCount1kHz m26 : 22|4@1+ (1,0) [0|15] "" Vector__XXX
 SG_ PM_a026_switchingActive m26 : 26|1@1+ (1,0) [0|1] "" Vector__XXX
 SG_ PM_a026_systemStackOvf m26 : 27|1@1+ (1,0) [0|1] "" Vector__XXX
 SG_ PM_a026_controlStackOvf m26 : 28|1@1+ (1,0) [0|1] "" Vector__XXX
 SG_ PM_a026_idleStackOvf m26 : 29|1@1+ (1,0) [0|1] "" Vector__XXX
 SG_ PM_a026_eepStackOvf m26 : 30|1@1+ (1,0) [0|1] "" Vector__XXX
 SG_ PM_a026_immStackOvf m26 : 31|1@1+ (1,0) [0|1] "" Vector__XXX
 SG_ PM_a026_xdcErrorIdMSW m26 : 32|10@1+ (1,0) [0|1023] "" Vector__XXX
 SG_ PM_a026_xdcErrorArg1 m26 : 42|22@1- (1,0) [-2097152|2097151] "" Vector__XXX
 SG_ PM_a030_diAebState m30 : 16|3@1+ (1,0) [0|6] "" Vector__XXX
 SG_ PM_a030_pmAebState m30 : 19|3@1+ (1,0) [0|6] "" Vector__XXX
 SG_ PM_a030_dasAebEvent m30 : 22|2@1+ (1,0) [0|2] "" Vector__XXX
 SG_ PM_a030_aebFaultReason m30 : 24|3@1+ (1,0) [0|7] "" Vector__XXX
 SG_ PM_a030_aebUnavailableReason m30 : 27|4@1+ (1,0) [0|15] "" Vector__XXX
 SG_ PM_a030_aebCancelReason m30 : 32|2@1+ (1,0) [0|3] "" Vector__XXX
 SG_ PM_a030_diBrakeTorqueCommand m30 : 34|13@1+ (2,0) [0|16382] "Nm" Vector__XXX
 SG_ PM_a032_w0 m32 : 16|16@1+ (1,0) [0|65535] "" Vector__XXX
 SG_ PM_a032_w1 m32 : 32|16@1+ (1,0) [0|65535] "" Vector__XXX
 SG_ PM_a032_w2 m32 : 48|16@1+ (1,0) [0|65535] "" Vector__XXX
 SG_ PM_a036_timeSinceTxHWI m36 : 16|6@1+ (64,0) [0|4032] "us" Vector__XXX
 SG_ PM_a036_timeSinceRxHWI m36 : 22|6@1+ (64,0) [0|4032] "us" Vector__XXX
 SG_ PM_a036_timeSince100HzTxSWI m36 : 28|6@1+ (0.32,0) [0|20.16] "ms" Vector__XXX
 SG_ PM_a036_timeSince1kHzCLK m36 : 34|6@1+ (32,0) [0|2016] "us" Vector__XXX
 SG_ PM_a036_timeSince1kHzSWI m36 : 40|6@1+ (32,0) [0|2016] "us" Vector__XXX
 SG_ PM_a036_timeSinceIdle m36 : 46|6@1+ (0.16,0) [0|10.08] "ms" Vector__XXX
 SG_ PM_a036_ovfStackId m36 : 52|4@1+ (1,0) [0|14] "" Vector__XXX
 SG_ PM_a036_inTxISR m36 : 56|1@1+ (1,0) [0|1] "" Vector__XXX
 SG_ PM_a036_inTxHWI m36 : 57|1@1+ (1,0) [0|1] "" Vector__XXX
 SG_ PM_a036_inRxHWI m36 : 58|1@1+ (1,0) [0|1] "" Vector__XXX
 SG_ PM_a036_in1kHzSWI m36 : 59|1@1+ (1,0) [0|1] "" Vector__XXX
 SG_ PM_a036_in1kHzCLK m36 : 60|1@1+ (1,0) [0|1] "" Vector__XXX
 SG_ PM_a036_in100HzCLK m36 : 61|1@1+ (1,0) [0|1] "" Vector__XXX
 SG_ PM_a036_in10HzCLK m36 : 62|1@1+ (1,0) [0|1] "" Vector__XXX
 SG_ PM_a036_in1HzCLK m36 : 63|1@1+ (1,0) [0|1] "" Vector__XXX
 SG_ PM_a038_masterTorque m38 : 16|13@1- (0.4,0) [-1638.4|1638] "Nm" Vector__XXX
 SG_ PM_a038_slaveTorque m38 : 32|13@1- (0.4,0) [-1638.4|1638] "Nm" Vector__XXX
 SG_ PM_a038_pedalPos m38 : 48|8@1- (0.4,50.4) [-0.8|101.2] "%" Vector__XXX
 SG_ PM_a039_DIS_status m39 : 16|1@1+ (1,0) [0|1] "" Vector__XXX
 SG_ PM_a039_DIS_torque m39 : 17|1@1+ (1,0) [0|1] "" Vector__XXX
 SG_ PM_a039_messageId m39 : 24|16@1+ (1,0) [0|65535] "" Vector__XXX
 SG_ PM_a041_DAS_control m41 : 16|1@1+ (1,0) [0|1] "" Vector__XXX
 SG_ PM_a041_DAS_longControl m41 : 17|1@1+ (1,0) [0|1] "" Vector__XXX
 SG_ PM_a041_DAS_longControlTuningPar m41 : 18|1@1+ (1,0) [0|1] "" Vector__XXX
 SG_ PM_a041_DAS_status m41 : 19|1@1+ (1,0) [0|1] "" Vector__XXX
 SG_ PM_a041_DAS_status2 m41 : 20|1@1+ (1,0) [0|1] "" Vector__XXX
 SG_ PM_a041_DAS_smartShift m41 : 21|1@1+ (1,0) [0|1] "" Vector__XXX
 SG_ PM_a041_DAS_autonomyControl m41 : 22|1@1+ (1,0) [0|1] "" Vector__XXX
 SG_ PM_a042_GTW_carConfig m42 : 16|1@1+ (1,0) [0|1] "" Vector__XXX
 SG_ PM_a042_GTW_time m42 : 17|1@1+ (1,0) [0|1] "" Vector__XXX
 SG_ PM_a042_GTW_drivetrainType m42 : 18|3@1+ (1,0) [0|7] "" Vector__XXX
 SG_ PM_a042_expectedPerformanceCfg m42 : 21|3@1+ (1,0) [0|7] "" Vector__XXX
 SG_ PM_a042_gearControl m42 : 24|1@1+ (1,0) [0|1] "" Vector__XXX
 SG_ PM_a043_configInconsistent m43 : 16|1@1+ (1,0) [0|1] "" Vector__XXX
 SG_ PM_a043_GTW_autopilot m43 : 17|1@1+ (1,0) [0|1] "" Vector__XXX
 SG_ PM_a043_expectedAutopilot m43 : 18|1@1+ (1,0) [0|1] "" Vector__XXX
 SG_ PM_a043_GTW_drivetrainType m43 : 19|2@1+ (1,0) [0|3] "" Vector__XXX
 SG_ PM_a043_expectedDrivetrainType m43 : 21|2@1+ (1,0) [0|3] "" Vector__XXX
 SG_ PM_a043_GTW_chassisType m43 : 24|2@1+ (1,0) [0|3] "" Vector__XXX
 SG_ PM_a043_expectedChassisType m43 : 26|2@1+ (1,0) [0|3] "" Vector__XXX
 SG_ PM_a043_packEnergy m43 : 28|1@1+ (1,0) [0|1] "" Vector__XXX
 SG_ PM_a043_packPerformanceDeviation m43 : 29|1@1+ (1,0) [0|1] "" Vector__XXX
 SG_ PM_a043_performancePackage m43 : 30|1@1+ (1,0) [0|1] "" Vector__XXX
 SG_ PM_a043_GTW_vdcType m43 : 31|1@1+ (1,0) [0|1] "" Vector__XXX
 SG_ PM_a043_expectedVdcType m43 : 32|1@1+ (1,0) [0|1] "" Vector__XXX
 SG_ PM_a043_brakeHWType m43 : 33|1@1+ (1,0) [0|1] "" Vector__XXX
 SG_ PM_a043_cabinPTCHeaterType m43 : 34|1@1+ (1,0) [0|1] "" Vector__XXX
 SG_ PM_a043_softPerformanceLimit m43 : 35|1@1+ (1,0) [0|1] "" Vector__XXX
 SG_ PM_a043_GTW_dasHw m43 : 36|1@1+ (1,0) [0|1] "" Vector__XXX
 SG_ PM_a044_pmCruiseState m44 : 16|3@1+ (1,0) [0|7] "" Vector__XXX
 SG_ PM_a044_diCruiseState m44 : 19|3@1+ (1,0) [0|7] "" Vector__XXX
 SG_ PM_a044_pmAebState m44 : 24|3@1+ (1,0) [0|6] "" Vector__XXX
 SG_ PM_a044_diAebState m44 : 27|3@1+ (1,0) [0|6] "" Vector__XXX
 SG_ PM_a044_diBrakeTorqueCommand m44 : 30|13@1+ (2,0) [0|16382] "Nm" Vector__XXX
 SG_ PM_a044_pmBfillTorqueAllowed m44 : 43|13@1+ (2,0) [0|16382] "Nm" Vector__XXX
 SG_ PM_a044_pmVehicleHoldState m44 : 56|3@1+ (1,0) [0|7] "" Vector__XXX
 SG_ PM_a044_diVehicleHoldState m44 : 59|3@1+ (1,0) [0|7] "" Vector__XXX
 SG_ PM_a044_regenBackfillPmState m44 : 62|2@1+ (1,0) [0|3] "" Vector__XXX
 SG_ PM_a045_regenBackfillPmState m45 : 16|2@1+ (1,0) [0|3] "" Vector__XXX
 SG_ PM_a045_regenBackfillDiState m45 : 18|2@1+ (1,0) [0|3] "" Vector__XXX
 SG_ PM_a045_unavailableReason m45 : 24|5@1+ (1,0) [0|31] "" Vector__XXX
 SG_ PM_a045_diBrakeTorqueCommand m45 : 32|13@1+ (2,0) [0|16382] "Nm" Vector__XXX
 SG_ PM_a045_pmBrakeTorqueAllowed m45 : 48|13@1+ (2,0) [0|16382] "Nm" Vector__XXX
 SG_ PM_a046_diVhldState m46 : 16|3@1+ (1,0) [0|7] "" Vector__XXX
 SG_ PM_a046_pmVhldState m46 : 19|3@1+ (1,0) [0|7] "" Vector__XXX
 SG_ PM_a046_vhldFaultReason m46 : 24|3@1+ (1,0) [0|7] "" Vector__XXX
 SG_ PM_a046_vhldUnavailableReason m46 : 27|4@1+ (1,0) [0|15] "" Vector__XXX
 SG_ PM_a046_diBrakeTorqueCommand m46 : 32|13@1+ (2,0) [0|16382] "Nm" Vector__XXX
 SG_ PM_a046_diBrakeCommandType m46 : 45|3@1+ (1,0) [0|7] "" Vector__XXX
 SG_ PM_a047_pmAutoparkState m47 : 16|4@1+ (1,0) [0|14] "" Vector__XXX
 SG_ PM_a047_diAutoparkState m47 : 20|4@1+ (1,0) [0|14] "" Vector__XXX
 SG_ PM_a047_autoparkCancelReason m47 : 24|2@1+ (1,0) [0|3] "" Vector__XXX
 SG_ PM_a048_vdcFaultReason m48 : 16|4@1+ (1,0) [0|15] "" Vector__XXX
 SG_ PM_a053_LVPowerState m53 : 16|1@1+ (1,0) [0|1] "" Vector__XXX
 SG_ PM_a053_coolant m53 : 17|1@1+ (1,0) [0|1] "" Vector__XXX
 SG_ PM_a053_vcleftSwitchStatus m53 : 18|1@1+ (1,0) [0|1] "" Vector__XXX
 SG_ PM_a053_restraintStatus m53 : 19|1@1+ (1,0) [0|1] "" Vector__XXX
 SG_ PM_a053_sensors m53 : 20|1@1+ (1,0) [0|1] "" Vector__XXX
 SG_ PM_a054_uiPowertrainControl m54 : 16|1@1+ (1,0) [0|1] "" Vector__XXX
 SG_ PM_a054_uiChassisControl m54 : 17|1@1+ (1,0) [0|1] "" Vector__XXX
 SG_ PM_a054_uiCruiseControl m54 : 18|1@1+ (1,0) [0|1] "" Vector__XXX
 SG_ PM_a054_uiTrackModeSettings m54 : 19|1@1+ (1,0) [0|1] "" Vector__XXX
 SG_ PM_a054_uiTPMSRCPSetting m54 : 20|1@1+ (1,0) [0|1] "" Vector__XXX
 SG_ PM_a058_CMP_HVStatus m58 : 16|1@1+ (1,0) [0|1] "" Vector__XXX
 SG_ PM_a058_CMPD_state m58 : 17|1@1+ (1,0) [0|1] "" Vector__XXX
 SG_ PM_a059_PTC_feedbackStatus m59 : 16|1@1+ (1,0) [0|1] "" Vector__XXX
 SG_ PM_a060_TorqueAccelWindow m60 : 16|16@1- (0.05,0) [-1638.4|1638.35] "NmS" Vector__XXX
 SG_ PM_a060_TorqueDecelWindow m60 : 32|16@1- (0.05,0) [-1638.4|1638.35] "NmS" Vector__XXX
 SG_ PM_a060_TorqueReversalWindow m60 : 48|16@1- (0.05,0) [-1638.4|1638.35] "NmS" Vector__XXX
 SG_ PM_a061_diIpcVersion m61 : 16|8@1+ (1,0) [0|255] "" Vector__XXX
 SG_ PM_a061_pmIpcVersion m61 : 24|8@1+ (1,0) [0|255] "" Vector__XXX
 SG_ PM_a062_address m62 : 16|32@1+ (1,0) [0|4294967295] "" Vector__XXX
 SG_ PM_a062_errorType m62 : 48|4@1+ (1,0) [0|15] "" Vector__XXX
 SG_ PM_a062_detectedByRamScrub m62 : 52|1@1+ (1,0) [0|1] "" Vector__XXX
 SG_ PM_a063_totalSystemTorqueCommand m63 : 16|13@1- (0.4,0) [-1638.4|1638] "Nm" Vector__XXX
 SG_ PM_a063_totalSystemTorqueMeasure m63 : 32|13@1- (0.4,0) [-1638.4|1638] "Nm" Vector__XXX
 SG_ PM_a064_interventionType m64 : 16|4@1+ (1,0) [0|15] "" Vector__XXX
 SG_ PM_a064_torqueCmdState m64 : 20|4@1+ (1,0) [1|15] "" Vector__XXX
 SG_ PM_a064_shortDetectedByDI m64 : 24|1@1+ (1,0) [0|1] "" Vector__XXX
 SG_ PM_a064_UI_stoppingMode m64 : 25|2@1+ (1,0) [0|3] "" Vector__XXX
 SG_ PM_a064_diCrsState m64 : 27|3@1+ (1,0) [0|7] "" Vector__XXX
 SG_ PM_a064_pmCrsState m64 : 32|3@1+ (1,0) [0|7] "" Vector__XXX
 SG_ PM_a066_state4 m66 : 16|1@1+ (1,0) [0|1] "" Vector__XXX
 SG_ PM_a067_state4 m67 : 16|1@1+ (1,0) [0|1] "" Vector__XXX
 SG_ PM_a070_unitTorqueActualMonitor m70 : 16|3@1+ (1,0) [0|7] "" Vector__XXX
 SG_ PM_a070_unitTorqueCommandedMonit m70 : 19|3@1+ (1,0) [0|7] "" Vector__XXX
 SG_ PM_a070_diTorqueCommandedMonitor m70 : 24|3@1+ (1,0) [0|7] "" Vector__XXX
 SG_ PM_a070_rearAxleMotorTorqueLimit m70 : 27|1@1+ (1,0) [0|1] "" Vector__XXX
 SG_ PM_a070_areAllInputsValid m70 : 28|1@1+ (1,0) [0|1] "" Vector__XXX
 SG_ PM_a070_isBrakeBlendingAvailable m70 : 29|1@1+ (1,0) [0|1] "" Vector__XXX
 SG_ PM_a070_faultReason m70 : 32|4@1+ (1,0) [0|15] "" Vector__XXX
 SG_ PM_a079_VEH_RCU_actuation m79 : 16|1@1+ (1,0) [0|1] "" Vector__XXX
 SG_ PM_a079_PARTY_RCU_actuation m79 : 17|1@1+ (1,0) [0|1] "" Vector__XXX
 SG_ PM_a082_faultAddress m82 : 16|32@1+ (1,0) [0|4294967295] "" Vector__XXX
 SG_ PM_a082_isWriteNotRead m82 : 48|1@1+ (1,0) [0|1] "" Vector__XXX
 SG_ PM_a084_faultAddress m84 : 16|32@1+ (1,0) [0|4294967295] "" Vector__XXX
 SG_ PM_a084_firewallId m84 : 48|5@1+ (1,0) [0|31] "" Vector__XXX
 SG_ PM_a084_privId m84 : 56|4@1+ (1,0) [0|15] "" Vector__XXX
 SG_ PM_a084_ns m84 : 60|1@1+ (1,0) [0|1] "" Vector__XXX
 SG_ PM_a084_faultType m84 : 61|3@1+ (1,0) [0|7] "" Vector__XXX
 SG_ PM_a085_DPB_actuator3 m85 : 16|1@1+ (1,0) [0|1] "" Vector__XXX
 SG_ PM_a087_mailboxID m87 : 16|16@1+ (1,0) [0|65535] "" Vector__XXX
 SG_ PM_a087_canID m87 : 32|16@1+ (1,0) [0|65535] "" Vector__XXX
 SG_ PM_a087_errorType m87 : 48|3@1+ (1,0) [0|7] "" Vector__XXX
 SG_ PM_a092_pllClockSource m92 : 16|2@1+ (1,0) [0|3] "" Vector__XXX
 SG_ PM_a100_index1kHzPeriodic m100 : 16|8@1+ (1,0) [0|255] "" Vector__XXX
 SG_ PM_a100_index100HzPeriodic m100 : 24|8@1+ (1,0) [0|255] "" Vector__XXX
 SG_ PM_a100_index10HzPeriodic m100 : 32|8@1+ (1,0) [0|255] "" Vector__XXX
 SG_ PM_a100_indexSWI m100 : 40|8@1+ (1,0) [0|255] "" Vector__XXX
 SG_ PM_a100_eepEvent m100 : 48|8@1+ (1,0) [0|255] "" Vector__XXX
 SG_ PM_a100_module500HzActive m100 : 56|1@1+ (1,0) [0|1] "" Vector__XXX
 SG_ PM_a100_module50HzActive m100 : 57|1@1+ (1,0) [0|1] "" Vector__XXX
 SG_ PM_a100_module1HzActive m100 : 58|1@1+ (1,0) [0|1] "" Vector__XXX
 SG_ PM_a100_task10HzActive m100 : 59|1@1+ (1,0) [0|1] "" Vector__XXX
 SG_ PM_a100_taskUdsActive m100 : 60|1@1+ (1,0) [0|1] "" Vector__XXX
 SG_ PM_a110_itpmsWarningFrL m110 : 16|2@1+ (1,0) [0|3] "" Vector__XXX
 SG_ PM_a110_itpmsWarningFrR m110 : 18|2@1+ (1,0) [0|3] "" Vector__XXX
 SG_ PM_a110_itpmsWarningReL m110 : 20|2@1+ (1,0) [0|3] "" Vector__XXX
 SG_ PM_a110_itpmsWarningReR m110 : 22|2@1+ (1,0) [0|3] "" Vector__XXX
 SG_ PM_a111_prevGearUnit0 m111 : 16|3@1+ (1,0) [0|6] "" Vector__XXX
 SG_ PM_a111_prevGearUnit1 m111 : 19|3@1+ (1,0) [0|6] "" Vector__XXX
 SG_ PM_a111_prevGearUnit2 m111 : 24|3@1+ (1,0) [0|6] "" Vector__XXX
 SG_ PM_a111_vehicleSpeed m111 : 27|12@1+ (0.08,-40) [-40|287.6] "kph" Vector__XXX
 SG_ PM_a111_recoveryTargetGear m111 : 40|3@1+ (1,0) [0|6] "" Vector__XXX
 SG_ PM_a111_unitsConsensus m111 : 43|1@1+ (1,0) [0|1] "" Vector__XXX
 SG_ PM_a111_speedPolarityMatch m111 : 44|1@1+ (1,0) [0|1] "" Vector__XXX
 SG_ PM_a111_failureReason m111 : 48|4@1+ (1,0) [0|15] "" Vector__XXX
 SG_ PM_a112_itpmsWarningFrL m112 : 16|2@1+ (1,0) [0|3] "" Vector__XXX
 SG_ PM_a112_itpmsWarningFrR m112 : 18|2@1+ (1,0) [0|3] "" Vector__XXX
 SG_ PM_a112_itpmsWarningReL m112 : 20|2@1+ (1,0) [0|3] "" Vector__XXX
 SG_ PM_a112_itpmsWarningReR m112 : 22|2@1+ (1,0) [0|3] "" Vector__XXX
 SG_ PM_a120_diMIA m120 : 16|1@1+ (1,0) [0|1] "" Vector__XXX
 SG_ PM_a120_diUnitsMIA m120 : 17|1@1+ (1,0) [0|1] "" Vector__XXX
 SG_ PM_a120_rcmMIA m120 : 18|1@1+ (1,0) [0|1] "" Vector__XXX
 SG_ PM_a120_wssMIA m120 : 19|1@1+ (1,0) [0|1] "" Vector__XXX
 SG_ PM_a120_gtwMIA m120 : 20|1@1+ (1,0) [0|1] "" Vector__XXX
 SG_ PM_a120_vcMIA m120 : 21|1@1+ (1,0) [0|1] "" Vector__XXX
 SG_ PM_a120_steeringMIA m120 : 22|1@1+ (1,0) [0|1] "" Vector__XXX
 SG_ PM_a120_gnssEpochMIA m120 : 23|1@1+ (1,0) [0|1] "" Vector__XXX

BO_ 900 PM_alertMatrix: 8 PM
 SG_ PM_matrixIndex M : 0|4@1+ (1,0) [0|15] "" Vector__XXX
 SG_ PM_a001_absoluteTorque m0 : 4|1@1+ (1,0) [0|1] "" Vector__XXX
 SG_ PM_a002_excessiveAccelTorque m0 : 5|1@1+ (1,0) [0|1] "" Vector__XXX
 SG_ PM_a003_excessiveReversalTorque m0 : 6|1@1+ (1,0) [0|1] "" Vector__XXX
 SG_ PM_a004_excessiveDecelTorque m0 : 7|1@1+ (1,0) [0|1] "" Vector__XXX
 SG_ PM_a005_torqueInNeutralOrPark m0 : 8|1@1+ (1,0) [0|1] "" Vector__XXX
 SG_ PM_a006_inconsistentDIGear m0 : 9|1@1+ (1,0) [0|1] "" Vector__XXX
 SG_ PM_a007_ibstMIA m0 : 10|1@1+ (1,0) [0|1] "" Vector__XXX
 SG_ PM_a008_memoryError m0 : 11|1@1+ (1,0) [0|1] "" Vector__XXX
 SG_ PM_a009_espMIA m0 : 12|1@1+ (1,0) [0|1] "" Vector__XXX
 SG_ PM_a010_diMIA m0 : 13|1@1+ (1,0) [0|1] "" Vector__XXX
 SG_ PM_a011_systemHvilNotClosed m0 : 14|1@1+ (1,0) [0|1] "" Vector__XXX
 SG_ PM_a012_canDataBusA m0 : 15|1@1+ (1,0) [0|1] "" Vector__XXX
 SG_ PM_a013_canHardwareBusA m0 : 16|1@1+ (1,0) [0|1] "" Vector__XXX
 SG_ PM_a014_accelPedalError m0 : 17|1@1+ (1,0) [0|1] "" Vector__XXX
 SG_ PM_a015_shifterMIA m0 : 18|1@1+ (1,0) [0|1] "" Vector__XXX
 SG_ PM_a016_bbMIA m0 : 19|1@1+ (1,0) [0|1] "" Vector__XXX
 SG_ PM_a017_brakeMIA m0 : 20|1@1+ (1,0) [0|1] "" Vector__XXX
 SG_ PM_a021_difMIA m0 : 24|1@1+ (1,0) [0|1] "" Vector__XXX
 SG_ PM_a022_dirMIA m0 : 25|1@1+ (1,0) [0|1] "" Vector__XXX
 SG_ PM_a023_cruiseInhibit m0 : 26|1@1+ (1,0) [0|1] "" Vector__XXX
 SG_ PM_a024_brakeIrrational m0 : 27|1@1+ (1,0) [0|1] "" Vector__XXX
 SG_ PM_a025_unintendedReset m0 : 28|1@1+ (1,0) [0|1] "" Vector__XXX
 SG_ PM_a026_diHeartBeatMIA m0 : 29|1@1+ (1,0) [0|1] "" Vector__XXX
 SG_ PM_a028_torqueCmdError m0 : 31|1@1+ (1,0) [0|1] "" Vector__XXX
 SG_ PM_a029_cruiseRollback m0 : 32|1@1+ (1,0) [0|1] "" Vector__XXX
 SG_ PM_a030_inconsistentAebState m0 : 33|1@1+ (1,0) [0|1] "" Vector__XXX
 SG_ PM_a031_highStackUsage m0 : 34|1@1+ (1,0) [0|1] "" Vector__XXX
 SG_ PM_a032_registerConfigError m0 : 35|1@1+ (1,0) [0|1] "" Vector__XXX
 SG_ PM_a033_appMIA m0 : 36|1@1+ (1,0) [0|1] "" Vector__XXX
 SG_ PM_a034_trqCrossCheck m0 : 37|1@1+ (1,0) [0|1] "" Vector__XXX
 SG_ PM_a035_udsTransactionInitiated m0 : 38|1@1+ (1,0) [0|1] "" Vector__XXX
 SG_ PM_a036_preWatchdog m0 : 39|1@1+ (1,0) [0|1] "" Vector__XXX
 SG_ PM_a038_inconsistentTorqueSign m0 : 41|1@1+ (1,0) [0|1] "" Vector__XXX
 SG_ PM_a039_disMIA m0 : 42|1@1+ (1,0) [0|1] "" Vector__XXX
 SG_ PM_a040_alignmentDriftDetected m0 : 43|1@1+ (1,0) [0|1] "" Vector__XXX
 SG_ PM_a041_dasMIA m0 : 44|1@1+ (1,0) [0|1] "" Vector__XXX
 SG_ PM_a042_gtwMIA m0 : 45|1@1+ (1,0) [0|1] "" Vector__XXX
 SG_ PM_a043_inconsistentConfig m0 : 46|1@1+ (1,0) [0|1] "" Vector__XXX
 SG_ PM_a044_ebrIntervention m0 : 47|1@1+ (1,0) [0|1] "" Vector__XXX
 SG_ PM_a045_regenBackfillInterventio m0 : 48|1@1+ (1,0) [0|1] "" Vector__XXX
 SG_ PM_a046_inconsVehicleHoldState m0 : 49|1@1+ (1,0) [0|1] "" Vector__XXX
 SG_ PM_a047_inconsAutoparkState m0 : 50|1@1+ (1,0) [0|1] "" Vector__XXX
 SG_ PM_a048_stabilityControlInhibit m0 : 51|1@1+ (1,0) [0|1] "" Vector__XXX
 SG_ PM_a049_stbCtrlInWrongDir m0 : 52|1@1+ (1,0) [0|1] "" Vector__XXX
 SG_ PM_a050_excessiveStbCtrlTrq m0 : 53|1@1+ (1,0) [0|1] "" Vector__XXX
 SG_ PM_a051_unintDecelStbCtrl m0 : 54|1@1+ (1,0) [0|1] "" Vector__XXX
 SG_ PM_a052_stbCtrlDrvrDecelCflct m0 : 55|1@1+ (1,0) [0|1] "" Vector__XXX
 SG_ PM_a053_vcfrontMIA m0 : 56|1@1+ (1,0) [0|1] "" Vector__XXX
 SG_ PM_a054_uiMIA m0 : 57|1@1+ (1,0) [0|1] "" Vector__XXX
 SG_ PM_a055_accelPedalSyncWarn m0 : 58|1@1+ (1,0) [0|1] "" Vector__XXX
 SG_ PM_a056_canHardwareBusB m0 : 59|1@1+ (1,0) [0|1] "" Vector__XXX
 SG_ PM_a057_canDataBusB m0 : 60|1@1+ (1,0) [0|1] "" Vector__XXX
 SG_ PM_a058_cmpMIA m0 : 61|1@1+ (1,0) [0|1] "" Vector__XXX
 SG_ PM_a059_ptcMIA m0 : 62|1@1+ (1,0) [0|1] "" Vector__XXX
 SG_ PM_a060_onePedalDrivingInhibit m0 : 63|1@1+ (1,0) [0|1] "" Vector__XXX
 SG_ PM_a061_DIPMVersionMismatch m1 : 4|1@1+ (1,0) [0|1] "" Vector__XXX
 SG_ PM_a062_eccError m1 : 5|1@1+ (1,0) [0|1] "" Vector__XXX
 SG_ PM_a063_torqueCommandInhibit m1 : 6|1@1+ (1,0) [0|1] "" Vector__XXX
 SG_ PM_a064_torqueIntervention m1 : 7|1@1+ (1,0) [0|1] "" Vector__XXX
 SG_ PM_a066_pmfMIA m1 : 9|1@1+ (1,0) [0|1] "" Vector__XXX
 SG_ PM_a067_pmrMIA m1 : 10|1@1+ (1,0) [0|1] "" Vector__XXX
 SG_ PM_a068_brakePedalMonitor m1 : 11|1@1+ (1,0) [0|1] "" Vector__XXX
 SG_ PM_a069_brakeMonitorsUnhealthy m1 : 12|1@1+ (1,0) [0|1] "" Vector__XXX
 SG_ PM_a070_brakeTorqueSplitMonitorT m1 : 13|1@1+ (1,0) [0|1] "" Vector__XXX
 SG_ PM_a071_baseBrakingMonitor m1 : 14|1@1+ (1,0) [0|1] "" Vector__XXX
 SG_ PM_a072_brakeTorqueCommandInterf m1 : 15|1@1+ (1,0) [0|1] "" Vector__XXX
 SG_ PM_a073_canDataBusC m1 : 16|1@1+ (1,0) [0|1] "" Vector__XXX
 SG_ PM_a074_canHardwareBusC m1 : 17|1@1+ (1,0) [0|1] "" Vector__XXX
 SG_ PM_a075_canDataBusD m1 : 18|1@1+ (1,0) [0|1] "" Vector__XXX
 SG_ PM_a076_canHardwareBusD m1 : 19|1@1+ (1,0) [0|1] "" Vector__XXX
 SG_ PM_a077_canDataBusE m1 : 20|1@1+ (1,0) [0|1] "" Vector__XXX
 SG_ PM_a078_canHardwareBusE m1 : 21|1@1+ (1,0) [0|1] "" Vector__XXX
 SG_ PM_a079_rcuMIA m1 : 22|1@1+ (1,0) [0|1] "" Vector__XXX
 SG_ PM_a080_exceptionPrefetchAbort m1 : 23|1@1+ (1,0) [0|1] "" Vector__XXX
 SG_ PM_a081_exceptionDataAbort m1 : 24|1@1+ (1,0) [0|1] "" Vector__XXX
 SG_ PM_a082_exceptionDataAbort2 m1 : 25|1@1+ (1,0) [0|1] "" Vector__XXX
 SG_ PM_a083_ahbWriteError m1 : 26|1@1+ (1,0) [0|1] "" Vector__XXX
 SG_ PM_a084_exceptionMpuFirewall m1 : 27|1@1+ (1,0) [0|1] "" Vector__XXX
 SG_ PM_a085_dpbMIA m1 : 28|1@1+ (1,0) [0|1] "" Vector__XXX
 SG_ PM_a086_exceptionUndefinedInstru m1 : 29|1@1+ (1,0) [0|1] "" Vector__XXX
 SG_ PM_a087_canHardwareBusLIPC m1 : 30|1@1+ (1,0) [0|1] "" Vector__XXX
 SG_ PM_a088_absMonitor m1 : 31|1@1+ (1,0) [0|1] "" Vector__XXX
 SG_ PM_a092_xtalOscillator m1 : 35|1@1+ (1,0) [0|1] "" Vector__XXX
 SG_ PM_a093_accelPedalSupply m1 : 36|1@1+ (1,0) [0|1] "" Vector__XXX
 SG_ PM_a094_torqueSplitMonitor m1 : 37|1@1+ (1,0) [0|1] "" Vector__XXX
 SG_ PM_a095_ITPMSTimeoutGNSSConverge m1 : 38|1@1+ (1,0) [0|1] "" Vector__XXX
 SG_ PM_a096_ITPMSConvergedGNSSAbsRad m1 : 39|1@1+ (1,0) [0|1] "" Vector__XXX
 SG_ PM_a097_ITPMSRelativeCalibratedF m1 : 40|1@1+ (1,0) [0|1] "" Vector__XXX
 SG_ PM_a098_ITPMSTriggerDebug m1 : 41|1@1+ (1,0) [0|1] "" Vector__XXX
 SG_ PM_a099_ITPMSCalibrated m1 : 42|1@1+ (1,0) [0|1] "" Vector__XXX
 SG_ PM_a100_diTraceInfo1 m1 : 43|1@1+ (1,0) [0|1] "" Vector__XXX
 SG_ PM_a110_indirectTPMSPressureLoss m1 : 53|1@1+ (1,0) [0|1] "" Vector__XXX
 SG_ PM_a111_unintendedResetCausedNeu m1 : 54|1@1+ (1,0) [0|1] "" Vector__XXX
 SG_ PM_a112_indirectTPMSPressureLoss m1 : 55|1@1+ (1,0) [0|1] "" Vector__XXX
 SG_ PM_a113_btcMonitor m1 : 56|1@1+ (1,0) [0|1] "" Vector__XXX
 SG_ PM_a114_ramScrubTimedOut m1 : 57|1@1+ (1,0) [0|1] "" Vector__XXX
 SG_ PM_a115_indirectTPMSFaultedGhost m1 : 58|1@1+ (1,0) [0|1] "" Vector__XXX
 SG_ PM_a116_ITPMSBlowoutCalProgress m1 : 59|1@1+ (1,0) [0|1] "" Vector__XXX
 SG_ PM_a117_ITPMSPermeabilityCalibra m1 : 60|1@1+ (1,0) [0|1] "" Vector__XXX
 SG_ PM_a118_vehicleSpeedQFDiagnostic m1 : 61|1@1+ (1,0) [0|1] "" Vector__XXX
 SG_ PM_a120_indirectTPMSFaulted m1 : 63|1@1+ (1,0) [0|1] "" Vector__XXX
 SG_ PM_a121_unintendedReset2 m2 : 4|1@1+ (1,0) [0|1] "" Vector__XXX
 SG_ PM_a125_btcOutputIrrational m2 : 8|1@1+ (1,0) [0|1] "" Vector__XXX

BO_ 2022 PM_info: 8 PM
 SG_ PM_infoIndex M : 0|8@1+ (1,0) [0|255] "" Vector__XXX
 SG_ PM_buildType m10 : 8|8@1+ (1,0) [0|255] "" Vector__XXX
 SG_ PM_buildConfigurationId m10 : 16|16@1+ (1,0) [0|65535] "" Vector__XXX
 SG_ PM_hardwareId m10 : 32|8@1+ (1,0) [0|252] "" Vector__XXX
 SG_ PM_deviceFused m10 : 40|1@1+ (1,0) [0|1] "" Vector__XXX
 SG_ PM_componentId m10 : 48|16@1+ (1,0) [0|65535] "" Vector__XXX
 SG_ PM_pcbaId m11 : 16|8@1+ (1,0) [0|255] "" Vector__XXX
 SG_ PM_assemblyId m11 : 24|8@1+ (1,0) [0|255] "" Vector__XXX
 SG_ PM_usageId m11 : 32|16@1+ (1,0) [0|65535] "" Vector__XXX
 SG_ PM_subUsageId m11 : 48|16@1+ (1,0) [0|65535] "" Vector__XXX
 SG_ PM_applicationCrc m13 : 32|32@1+ (1,0) [0|4294967295] "" Vector__XXX
 SG_ PM_bootGitHash m18 : 8|56@1+ (1,0) [0|7.20575940379e+16] "" Vector__XXX

BO_ 1973 PM_itpmsDisplay: 3 PM
 SG_ PM_itpmsDisplaySelector M : 0|2@1+ (1,0) [0|3] "" Vector__XXX
 SG_ PM_indirectTPMSTellTale m0 : 2|2@1+ (1,0) [0|3] "" Vector__XXX
 SG_ PM_indirectTPMSDisplayState m0 : 4|2@1+ (1,0) [0|3] "" Vector__XXX
 SG_ PM_indirectTPMSDisplayProgress m0 : 8|5@1+ (0.05,0) [0|1] "-" Vector__XXX
 SG_ PM_indirectTPMSDisplayWarningInd m0 : 13|2@1+ (1,0) [0|3] "" Vector__XXX
 SG_ PM_indirectTPMSDisplayWarni_0001 m0 : 16|2@1+ (1,0) [0|3] "" Vector__XXX
 SG_ PM_indirectTPMSDisplayWarni_0002 m0 : 18|2@1+ (1,0) [0|3] "" Vector__XXX
 SG_ PM_indirectTPMSDisplayWarni_0003 m0 : 20|2@1+ (1,0) [0|3] "" Vector__XXX
 SG_ PM_indirectTPMSRecommendedColdPr m1 : 8|8@1+ (0.025,0) [0|6.35] "bar" Vector__XXX
 SG_ PM_indirectTPMSRecommendedC_0001 m1 : 16|8@1+ (0.025,0) [0|6.35] "bar" Vector__XXX
 SG_ PM_fusedPressureEstimateFrL m2 : 2|9@1+ (0.008,0) [0|4] "bar" Vector__XXX
 SG_ PM_fusedPressureEstimateFrR m2 : 11|9@1+ (0.008,0) [0|4] "bar" Vector__XXX
 SG_ PM_fusedPressureEstimateReL m3 : 2|9@1+ (0.008,0) [0|4] "bar" Vector__XXX
 SG_ PM_fusedPressureEstimateReR m3 : 11|9@1+ (0.008,0) [0|4] "bar" Vector__XXX

BO_ 485 PM_locState: 8 PM
 SG_ PM_cruiseFaultRequest : 0|1@1+ (1,0) [0|1] "" Vector__XXX
 SG_ PM_shiftState : 1|3@1+ (1,0) [0|6] "" Vector__XXX
 SG_ PM_cruiseState : 4|3@1+ (1,0) [0|7] "" Vector__XXX
 SG_ PM_vehicleHoldRequest : 7|1@1+ (1,0) [0|1] "" Vector__XXX
 SG_ PM_aebRequest : 8|1@1+ (1,0) [0|1] "" Vector__XXX
 SG_ PM_torqueCmdState : 9|4@1+ (1,0) [1|15] "" Vector__XXX
 SG_ PM_btcCmdState : 13|1@1+ (1,0) [0|1] "" Vector__XXX
 SG_ PM_unparkAllowed : 14|1@1+ (1,0) [0|1] "" Vector__XXX
 SG_ PM_stationaryMode : 15|1@1+ (1,0) [0|1] "" Vector__XXX
 SG_ PM_onePedalFaultRequest : 16|1@1+ (1,0) [0|1] "" Vector__XXX
 SG_ PM_backfillDisableRequest : 17|1@1+ (1,0) [0|1] "" Vector__XXX
 SG_ PM_autoparkState : 18|4@1+ (1,0) [0|14] "" Vector__XXX
 SG_ PM_regenBlendCmdQF : 22|1@1+ (1,0) [0|1] "" Vector__XXX
 SG_ PM_brakePedalCmdQF : 23|1@1+ (1,0) [0|1] "" Vector__XXX
 SG_ PM_latentFaultCheckIntResponse : 32|16@1+ (1,0) [0|65535] "" Vector__XXX
 SG_ PM_hvilSystemStatus : 48|2@1+ (1,0) [0|2] "" Vector__XXX
 SG_ PM_locStateCounter : 53|2@1+ (1,0) [0|3] "" Vector__XXX
 SG_ PM_locStateChecksum : 56|8@1+ (1,0) [0|255] "" Vector__XXX

BO_TX_BU_ 1317 : PMF;
BO_TX_BU_ 772 : PMF;
BO_TX_BU_ 790 : PMF;
BO_TX_BU_ 1316 : PMF;
BO_TX_BU_ 1620 : PMF;
BO_TX_BU_ 1446 : PMR;
BO_TX_BU_ 902 : PMR;
BO_TX_BU_ 1748 : PMR;
BO_TX_BU_ 2023 : PMR;
BO_TX_BU_ 1556 : PMR;
BO_TX_BU_ 1444 : PM;
BO_TX_BU_ 900 : PM;
BO_TX_BU_ 2022 : PM;
BO_TX_BU_ 1973 : PM;
BO_TX_BU_ 485 : PM;
CM_ BO_ 1317 "PMF ECU message: alert log";
CM_ SG_ 1317 PMF_alertID "PMF ECU: alert ID";
CM_ SG_ 1317 PMF_alertState "PMF ECU: alert state";
CM_ SG_ 1317 PMF_a001_w0 "PMF ECU: a001 w0";
CM_ SG_ 1317 PMF_a001_w1 "PMF ECU: a001 w1";
CM_ SG_ 1317 PMF_a001_w2 "PMF ECU: a001 w2";
CM_ SG_ 1317 PMF_a002_torqueAverage "PMF ECU: a002 torque average";
CM_ SG_ 1317 PMF_a002_torqueWindow "PMF ECU: a002 torque window";
CM_ SG_ 1317 PMF_a002_torqueMeasured "PMF ECU: a002 torque measured; raw 4096 = signal not available (SNA)";
CM_ SG_ 1317 PMF_a002_torqueAccelAverage "PMF ECU: a002 torque accel average; raw 4096 = signal not available (SNA)";
CM_ SG_ 1317 PMF_a002_torqueAccelWindow "PMF ECU: a002 torque accel window; raw 4096 = signal not available (SNA)";
CM_ SG_ 1317 PMF_a003_reverseGear "PMF ECU: a003 reverse gear";
CM_ SG_ 1317 PMF_a003_pedalPos "PMF ECU: a003 pedal pos";
CM_ SG_ 1317 PMF_a003_zeroPointPedal "PMF ECU: a003 zero point pedal";
CM_ SG_ 1317 PMF_a004_torqueAverage "PMF ECU: a004 torque average";
CM_ SG_ 1317 PMF_a004_torqueWindow "PMF ECU: a004 torque window";
CM_ SG_ 1317 PMF_a004_torqueMeasured "PMF ECU: a004 torque measured; raw 4096 = signal not available (SNA)";
CM_ SG_ 1317 PMF_a004_torqueDecelAverage "PMF ECU: a004 torque decel average; raw 4096 = signal not available (SNA)";
CM_ SG_ 1317 PMF_a004_torqueDecelWindow "PMF ECU: a004 torque decel window; raw 4096 = signal not available (SNA)";
CM_ SG_ 1317 PMF_a005_torqueReason "PMF ECU: a005 torque reason";
CM_ SG_ 1317 PMF_a005_torqueMeasured "PMF ECU: a005 torque measured; raw 4096 = signal not available (SNA)";
CM_ SG_ 1317 PMF_a005_iDQmagnitude "PMF ECU: a005 i d qmagnitude";
CM_ SG_ 1317 PMF_a006_torqueActual "PMF ECU: a006 torque actual; raw 4096 = signal not available (SNA)";
CM_ SG_ 1317 PMF_a006_motorRPM "PMF ECU: a006 motor RPM";
CM_ SG_ 1317 PMF_a006_torqueMeasured "PMF ECU: a006 torque measured; raw 4096 = signal not available (SNA)";
CM_ SG_ 1317 PMF_a010_messageId "PMF ECU: a010 message id";
CM_ SG_ 1317 PMF_a010_DI_status "PMF ECU: a010 DI status";
CM_ SG_ 1317 PMF_a010_DI_torque "PMF ECU: a010 DI torque";
CM_ SG_ 1317 PMF_a010_DI_slaveCommand "PMF ECU: a010 DI slave command";
CM_ SG_ 1317 PMF_a010_DI_locStatus "PMF ECU: a010 DI loc status";
CM_ SG_ 1317 PMF_a010_DI_speed "PMF ECU: a010 DI speed";
CM_ SG_ 1317 PMF_a010_DI_systemStatus "PMF ECU: a010 DI system status";
CM_ SG_ 1317 PMF_a010_DI_chassisControl "PMF ECU: a010 DI chassis control";
CM_ SG_ 1317 PMF_a010_DI_chassisControl2 "PMF ECU: a010 DI chassis control2";
CM_ SG_ 1317 PMF_a010_vdcLeft "PMF ECU: a010 vdc left";
CM_ SG_ 1317 PMF_a010_vdcRight "PMF ECU: a010 vdc right";
CM_ SG_ 1317 PMF_a010_DI_vehicleEstimates "PMF ECU: a010 DI vehicle estimates";
CM_ SG_ 1317 PMF_a010_DI_brakeCommand "PMF ECU: a010 DI brake command";
CM_ SG_ 1317 PMF_a010_DI_autonomyHealth "PMF ECU: a010 DI autonomy health";
CM_ SG_ 1317 PMF_a010_DI_difCommand "PMF ECU: a010 DI dif command";
CM_ SG_ 1317 PMF_a010_DI_dirCommand "PMF ECU: a010 DI dir command";
CM_ SG_ 1317 PMF_a010_DI_dirVehicle "PMF ECU: a010 DI dir vehicle";
CM_ SG_ 1317 PMF_a010_DI_locStatus2 "PMF ECU: a010 DI loc status2";
CM_ SG_ 1317 PMF_a011_Ia "PMF ECU: a011 ia";
CM_ SG_ 1317 PMF_a011_IaDelta "PMF ECU: a011 ia delta";
CM_ SG_ 1317 PMF_a011_Ib "PMF ECU: a011 ib";
CM_ SG_ 1317 PMF_a011_IbDelta "PMF ECU: a011 ib delta";
CM_ SG_ 1317 PMF_a011_currentVref "PMF ECU: a011 current vref";
CM_ SG_ 1317 PMF_a011_badPhaseAsample "PMF ECU: a011 bad phase asample";
CM_ SG_ 1317 PMF_a011_badPhaseBsample "PMF ECU: a011 bad phase bsample";
CM_ SG_ 1317 PMF_a011_sampleFreeze "PMF ECU: a011 sample freeze";
CM_ SG_ 1317 PMF_a011_rateOfChangeIrrational "PMF ECU: a011 rate of change irrational";
CM_ SG_ 1317 PMF_a011_currentReadingIrrationa "PMF ECU: a011 current reading irrational";
CM_ SG_ 1317 PMF_a011_vrefIrrational "PMF ECU: a011 vref irrational";
CM_ SG_ 1317 PMF_a017_EPBL_status "PMF ECU: a017 EPBL status";
CM_ SG_ 1317 PMF_a017_EPBR_status "PMF ECU: a017 EPBR status";
CM_ SG_ 1317 PMF_a017_EPBL_autonomyHealth "PMF ECU: a017 EPBL autonomy health";
CM_ SG_ 1317 PMF_a017_EPBR_autonomyHealth "PMF ECU: a017 EPBR autonomy health";
CM_ SG_ 1317 PMF_a018_w0 "PMF ECU: a018 w0";
CM_ SG_ 1317 PMF_a018_w1 "PMF ECU: a018 w1";
CM_ SG_ 1317 PMF_a018_w2 "PMF ECU: a018 w2";
CM_ SG_ 1317 PMF_a019_statorTemp1 "PMF ECU: a019 stator temp1";
CM_ SG_ 1317 PMF_a019_statorTslope1 "PMF ECU: a019 stator tslope1";
CM_ SG_ 1317 PMF_a025_sccReset "PMF ECU: a025 scc reset";
CM_ SG_ 1317 PMF_a025_hibernate "PMF ECU: a025 hibernate";
CM_ SG_ 1317 PMF_a025_hwBist "PMF ECU: a025 hw bist";
CM_ SG_ 1317 PMF_a025_nmiWatchdog "PMF ECU: a025 nmi watchdog";
CM_ SG_ 1317 PMF_a025_watchdog "PMF ECU: a025 watchdog";
CM_ SG_ 1317 PMF_a025_clockFailNmi "PMF ECU: a025 clock fail nmi";
CM_ SG_ 1317 PMF_a025_ramUncErrorNmi "PMF ECU: a025 ram unc error nmi";
CM_ SG_ 1317 PMF_a025_flashUncErrorNmi "PMF ECU: a025 flash unc error nmi";
CM_ SG_ 1317 PMF_a025_cpu1signMismatchNmi "PMF ECU: a025 cpu1sign mismatch nmi";
CM_ SG_ 1317 PMF_a025_cpu2signMismatchNmi "PMF ECU: a025 cpu2sign mismatch nmi";
CM_ SG_ 1317 PMF_a025_pieVectErrorNmi "PMF ECU: a025 pie vect error nmi";
CM_ SG_ 1317 PMF_a025_sysDbgNmi "PMF ECU: a025 sys dbg nmi";
CM_ SG_ 1317 PMF_a025_rlNmi "PMF ECU: a025 rl nmi";
CM_ SG_ 1317 PMF_a025_ovfNmi "PMF ECU: a025 ovf nmi";
CM_ SG_ 1317 PMF_a025_possibleSafetyICReset "PMF ECU: a025 possible safety IC reset";
CM_ SG_ 1317 PMF_a025_powerOnReset "PMF ECU: a025 power on reset";
CM_ SG_ 1317 PMF_a025_watchdogTimer0 "PMF ECU: a025 watchdog timer0";
CM_ SG_ 1317 PMF_a025_watchdogTimer1 "PMF ECU: a025 watchdog timer1";
CM_ SG_ 1317 PMF_a025_watchdogTimer2 "PMF ECU: a025 watchdog timer2";
CM_ SG_ 1317 PMF_a025_watchdogTimer3 "PMF ECU: a025 watchdog timer3";
CM_ SG_ 1317 PMF_a025_warmResetReq "PMF ECU: a025 warm reset req";
CM_ SG_ 1317 PMF_a025_externalPadReset "PMF ECU: a025 external pad reset";
CM_ SG_ 1317 PMF_a025_hwSecModuleWatchdogTime "PMF ECU: a025 hw sec module watchdog timer";
CM_ SG_ 1317 PMF_a025_debugReset "PMF ECU: a025 debug reset";
CM_ SG_ 1317 PMF_a025_tempSense0 "PMF ECU: a025 temp sense0";
CM_ SG_ 1317 PMF_a025_tempSense1 "PMF ECU: a025 temp sense1";
CM_ SG_ 1317 PMF_a026_reason "PMF ECU: a026 reason";
CM_ SG_ 1317 PMF_a026_isrCount20kHz "PMF ECU: a026 isr count20k hz";
CM_ SG_ 1317 PMF_a026_isrCount1kHz "PMF ECU: a026 isr count1k hz";
CM_ SG_ 1317 PMF_a026_switchingActive "PMF ECU: a026 switching active";
CM_ SG_ 1317 PMF_a026_systemStackOvf "PMF ECU: a026 system stack ovf";
CM_ SG_ 1317 PMF_a026_controlStackOvf "PMF ECU: a026 control stack ovf";
CM_ SG_ 1317 PMF_a026_idleStackOvf "PMF ECU: a026 idle stack ovf";
CM_ SG_ 1317 PMF_a026_eepStackOvf "PMF ECU: a026 eep stack ovf";
CM_ SG_ 1317 PMF_a026_immStackOvf "PMF ECU: a026 imm stack ovf";
CM_ SG_ 1317 PMF_a026_xdcErrorIdMSW "PMF ECU: a026 xdc error id MSW";
CM_ SG_ 1317 PMF_a026_xdcErrorArg1 "PMF ECU: a026 xdc error arg1";
CM_ SG_ 1317 PMF_a032_w0 "PMF ECU: a032 w0";
CM_ SG_ 1317 PMF_a032_w1 "PMF ECU: a032 w1";
CM_ SG_ 1317 PMF_a032_w2 "PMF ECU: a032 w2";
CM_ SG_ 1317 PMF_a033_state "PMF ECU: a033 state";
CM_ SG_ 1317 PMF_a033_failReason "PMF ECU: a033 fail reason";
CM_ SG_ 1317 PMF_a033_DSADC_Ia "PMF ECU: a033 DSADC ia";
CM_ SG_ 1317 PMF_a033_DSADC_Ib "PMF ECU: a033 DSADC ib";
CM_ SG_ 1317 PMF_a036_timeSinceTxHWI "PMF ECU: a036 time since tx HWI";
CM_ SG_ 1317 PMF_a036_timeSinceRxHWI "PMF ECU: a036 time since rx HWI";
CM_ SG_ 1317 PMF_a036_timeSince100HzTxSWI "PMF ECU: a036 time since100 hz tx SWI";
CM_ SG_ 1317 PMF_a036_timeSince1kHzCLK "PMF ECU: a036 time since1k hz CLK";
CM_ SG_ 1317 PMF_a036_timeSince1kHzSWI "PMF ECU: a036 time since1k hz SWI";
CM_ SG_ 1317 PMF_a036_timeSinceIdle "PMF ECU: a036 time since idle";
CM_ SG_ 1317 PMF_a036_ovfStackId "PMF ECU: a036 ovf stack id; raw 15 = signal not available (SNA)";
CM_ SG_ 1317 PMF_a036_inTxISR "PMF ECU: a036 in tx ISR";
CM_ SG_ 1317 PMF_a036_inTxHWI "PMF ECU: a036 in tx HWI";
CM_ SG_ 1317 PMF_a036_inRxHWI "PMF ECU: a036 in rx HWI";
CM_ SG_ 1317 PMF_a036_in1kHzSWI "PMF ECU: a036 in1k hz SWI";
CM_ SG_ 1317 PMF_a036_in1kHzCLK "PMF ECU: a036 in1k hz CLK";
CM_ SG_ 1317 PMF_a036_in100HzCLK "PMF ECU: a036 in100 hz CLK";
CM_ SG_ 1317 PMF_a036_in10HzCLK "PMF ECU: a036 in10 hz CLK";
CM_ SG_ 1317 PMF_a036_in1HzCLK "PMF ECU: a036 in1 hz CLK";
CM_ SG_ 1317 PMF_a037_hvpFaults "PMF ECU: a037 hvp faults";
CM_ SG_ 1317 PMF_a039_DIS_status "PMF ECU: a039 DIS status";
CM_ SG_ 1317 PMF_a039_DIS_torque "PMF ECU: a039 DIS torque";
CM_ SG_ 1317 PMF_a039_messageId "PMF ECU: a039 message id";
CM_ SG_ 1317 PMF_a040_PM_state "PMF ECU: a040 PM state";
CM_ SG_ 1317 PMF_a040_messageId "PMF ECU: a040 message id";
CM_ SG_ 1317 PMF_a040_PM_locState "PMF ECU: a040 PM loc state";
CM_ SG_ 1317 PMF_a042_GTW_carConfig "PMF ECU: a042 GTW car config";
CM_ SG_ 1317 PMF_a042_GTW_time "PMF ECU: a042 GTW time";
CM_ SG_ 1317 PMF_a042_GTW_drivetrainType "PMF ECU: a042 GTW drivetrain type";
CM_ SG_ 1317 PMF_a042_expectedPerformanceCfg "PMF ECU: a042 expected performance cfg";
CM_ SG_ 1317 PMF_a042_gearControl "PMF ECU: a042 gear control";
CM_ SG_ 1317 PMF_a053_LVPowerState "PMF ECU: a053 LV power state";
CM_ SG_ 1317 PMF_a053_coolant "PMF ECU: a053 coolant";
CM_ SG_ 1317 PMF_a053_vcleftSwitchStatus "PMF ECU: a053 vcleft switch status";
CM_ SG_ 1317 PMF_a053_restraintStatus "PMF ECU: a053 restraint status";
CM_ SG_ 1317 PMF_a053_sensors "PMF ECU: a053 sensors";
CM_ SG_ 1317 PMF_a054_uiPowertrainControl "PMF ECU: a054 ui powertrain control";
CM_ SG_ 1317 PMF_a054_uiChassisControl "PMF ECU: a054 ui chassis control";
CM_ SG_ 1317 PMF_a054_uiCruiseControl "PMF ECU: a054 ui cruise control";
CM_ SG_ 1317 PMF_a054_uiTrackModeSettings "PMF ECU: a054 ui track mode settings";
CM_ SG_ 1317 PMF_a054_uiTPMSRCPSetting "PMF ECU: a054 ui TPMSRCP setting";
CM_ SG_ 1317 PMF_a055_motorRPM "PMF ECU: a055 motor RPM";
CM_ SG_ 1317 PMF_a055_phaseAngle "PMF ECU: a055 phase angle";
CM_ SG_ 1317 PMF_a055_commonGain "PMF ECU: a055 common gain";
CM_ SG_ 1317 PMF_a055_notReady "PMF ECU: a055 not ready";
CM_ SG_ 1317 PMF_a055_noCarrier "PMF ECU: a055 no carrier";
CM_ SG_ 1317 PMF_a055_phaseOutOfSpec "PMF ECU: a055 phase out of spec";
CM_ SG_ 1317 PMF_a055_diElecAngleMismatch "PMF ECU: a055 di elec angle mismatch";
CM_ SG_ 1317 PMF_a055_diSpeedMismatch "PMF ECU: a055 di speed mismatch";
CM_ SG_ 1317 PMF_a055_claMIA "PMF ECU: a055 cla MIA";
CM_ SG_ 1317 PMF_a055_diMIA "PMF ECU: a055 di MIA";
CM_ SG_ 1317 PMF_a055_diElecAngleMismatchWarn "PMF ECU: a055 di elec angle mismatch warn";
CM_ SG_ 1317 PMF_a058_hvilCurrent "PMF ECU: a058 hvil current";
CM_ SG_ 1317 PMF_a061_diIpcVersion "PMF ECU: a061 di ipc version";
CM_ SG_ 1317 PMF_a061_pmIpcVersion "PMF ECU: a061 pm ipc version";
CM_ SG_ 1317 PMF_a062_address "PMF ECU: a062 address";
CM_ SG_ 1317 PMF_a062_errorType "PMF ECU: a062 error type";
CM_ SG_ 1317 PMF_a062_detectedByRamScrub "PMF ECU: a062 detected by ram scrub";
CM_ SG_ 1317 PMF_a064_interventionType "PMF ECU: a064 intervention type";
CM_ SG_ 1317 PMF_a064_torqueCmdState "PMF ECU: a064 torque cmd state; raw 0 = signal not available (SNA)";
CM_ SG_ 1317 PMF_a064_shortDetectedByDI "PMF ECU: a064 short detected by DI";
CM_ SG_ 1317 PMF_a064_UI_stoppingMode "PMF ECU: a064 UI stopping mode";
CM_ SG_ 1317 PMF_a064_diCrsState "PMF ECU: a064 di crs state";
CM_ SG_ 1317 PMF_a064_pmCrsState "PMF ECU: a064 pm crs state";
CM_ SG_ 1317 PMF_a082_faultAddress "PMF ECU: a082 fault address";
CM_ SG_ 1317 PMF_a082_isWriteNotRead "PMF ECU: a082 is write not read";
CM_ SG_ 1317 PMF_a084_faultAddress "PMF ECU: a084 fault address";
CM_ SG_ 1317 PMF_a084_firewallId "PMF ECU: a084 firewall id";
CM_ SG_ 1317 PMF_a084_privId "PMF ECU: a084 priv id";
CM_ SG_ 1317 PMF_a084_ns "PMF ECU: a084 ns";
CM_ SG_ 1317 PMF_a084_faultType "PMF ECU: a084 fault type";
CM_ SG_ 1317 PMF_a092_pllClockSource "PMF ECU: a092 pll clock source";
CM_ SG_ 1317 PMF_a095_wwdErrIntFlag "PMF ECU: a095 wwd err int flag";
CM_ SG_ 1317 PMF_a095_fwdErrIntFlag "PMF ECU: a095 fwd err int flag";
CM_ SG_ 1317 PMF_a095_errMissStsFlag "PMF ECU: a095 err miss sts flag";
CM_ SG_ 1317 PMF_a095_preRegulatorOT "PMF ECU: a095 pre regulator OT";
CM_ SG_ 1317 PMF_a095_ucLdoOT "PMF ECU: a095 uc ldo OT";
CM_ SG_ 1317 PMF_a095_monitoringOT "PMF ECU: a095 monitoring OT";
CM_ SG_ 1317 PMF_a095_preRegulatorVoltShort "PMF ECU: a095 pre regulator volt short";
CM_ SG_ 1317 PMF_a095_ucLdoShort "PMF ECU: a095 uc ldo short";
CM_ SG_ 1317 PMF_a095_standbyLdoShort "PMF ECU: a095 standby ldo short";
CM_ SG_ 1317 PMF_a095_coreVoltShort "PMF ECU: a095 core volt short";
CM_ SG_ 1317 PMF_a095_preRegulatorOV "PMF ECU: a095 pre regulator OV";
CM_ SG_ 1317 PMF_a095_ucLdoOV "PMF ECU: a095 uc ldo OV";
CM_ SG_ 1317 PMF_a095_standbyLdoOV "PMF ECU: a095 standby ldo OV";
CM_ SG_ 1317 PMF_a095_coreOV "PMF ECU: a095 core OV";
CM_ SG_ 1317 PMF_a095_voltRefOV "PMF ECU: a095 volt ref OV";
CM_ SG_ 1317 PMF_a095_ucLdoUV "PMF ECU: a095 uc ldo UV";
CM_ SG_ 1317 PMF_a095_standbyLdoUV "PMF ECU: a095 standby ldo UV";
CM_ SG_ 1317 PMF_a095_coreUV "PMF ECU: a095 core UV";
CM_ SG_ 1317 PMF_a095_supplyVoltOV "PMF ECU: a095 supply volt OV";
CM_ SG_ 1317 PMF_a095_bandgapComparatorUV "PMF ECU: a095 bandgap comparator UV";
CM_ SG_ 1317 PMF_a095_bandgapComparatorOV "PMF ECU: a095 bandgap comparator OV";
CM_ SG_ 1317 PMF_a095_biasCurrentTooLow "PMF ECU: a095 bias current too low";
CM_ SG_ 1317 PMF_a095_biasCurrentTooHigh "PMF ECU: a095 bias current too high";
CM_ SG_ 1317 PMF_a095_safetyICstate "PMF ECU: a095 safety i cstate";
CM_ SG_ 1317 PMF_a095_motorRPM "PMF ECU: a095 motor RPM";
CM_ SG_ 1317 PMF_a095_wwdErrCounter "PMF ECU: a095 wwd err counter";
CM_ SG_ 1317 PMF_a095_fwdErrCounter "PMF ECU: a095 fwd err counter";
CM_ SG_ 1317 PMF_a100_index1kHzPeriodic "PMF ECU: a100 index1k hz periodic";
CM_ SG_ 1317 PMF_a100_index100HzPeriodic "PMF ECU: a100 index100 hz periodic";
CM_ SG_ 1317 PMF_a100_index10HzPeriodic "PMF ECU: a100 index10 hz periodic";
CM_ SG_ 1317 PMF_a100_indexSWI "PMF ECU: a100 index SWI";
CM_ SG_ 1317 PMF_a100_eepEvent "PMF ECU: a100 eep event";
CM_ SG_ 1317 PMF_a100_module500HzActive "PMF ECU: a100 module500 hz active";
CM_ SG_ 1317 PMF_a100_module50HzActive "PMF ECU: a100 module50 hz active";
CM_ SG_ 1317 PMF_a100_module1HzActive "PMF ECU: a100 module1 hz active";
CM_ SG_ 1317 PMF_a100_task10HzActive "PMF ECU: a100 task10 hz active";
CM_ SG_ 1317 PMF_a100_taskUdsActive "PMF ECU: a100 task uds active";
CM_ BO_ 772 "PMF ECU message: alert matrix";
CM_ SG_ 772 PMF_matrixIndex "PMF ECU: matrix index";
CM_ SG_ 772 PMF_a001_absoluteTorque "PMF ECU: a001 absolute torque";
CM_ SG_ 772 PMF_a002_excessiveAccelTorque "PMF ECU: a002 excessive accel torque";
CM_ SG_ 772 PMF_a003_excessiveReversalTorque "PMF ECU: a003 excessive reversal torque";
CM_ SG_ 772 PMF_a004_excessiveDecelTorque "PMF ECU: a004 excessive decel torque";
CM_ SG_ 772 PMF_a005_torqueInNeutralOrPark "PMF ECU: a005 torque in neutral or park";
CM_ SG_ 772 PMF_a006_underTorqueCheck "PMF ECU: a006 under torque check";
CM_ SG_ 772 PMF_a008_memoryError "PMF ECU: a008 memory error";
CM_ SG_ 772 PMF_a010_diMIA "PMF ECU: a010 di MIA";
CM_ SG_ 772 PMF_a011_phaseCurrentIrrational "PMF ECU: a011 phase current irrational";
CM_ SG_ 772 PMF_a012_canDataBusA "PMF ECU: a012 can data bus a";
CM_ SG_ 772 PMF_a013_canHardwareBusA "PMF ECU: a013 can hardware bus a";
CM_ SG_ 772 PMF_a017_brakeMIA "PMF ECU: a017 brake MIA";
CM_ SG_ 772 PMF_a018_encoderIrrational "PMF ECU: a018 encoder irrational";
CM_ SG_ 772 PMF_a019_statorTempIrrational "PMF ECU: a019 stator temp irrational";
CM_ SG_ 772 PMF_a025_unintendedReset "PMF ECU: a025 unintended reset";
CM_ SG_ 772 PMF_a026_diHeartBeatMIA "PMF ECU: a026 di heart beat MIA";
CM_ SG_ 772 PMF_a027_torqueEstimationOutOfBo "PMF ECU: a027 torque estimation out of bounds";
CM_ SG_ 772 PMF_a028_torqueCmdError "PMF ECU: a028 torque cmd error";
CM_ SG_ 772 PMF_a031_highStackUsage "PMF ECU: a031 high stack usage";
CM_ SG_ 772 PMF_a032_registerConfigError "PMF ECU: a032 register config error";
CM_ SG_ 772 PMF_a033_selfTest "PMF ECU: a033 self test";
CM_ SG_ 772 PMF_a034_trqCrossCheck "PMF ECU: a034 trq cross check";
CM_ SG_ 772 PMF_a035_udsTransactionInitiated "PMF ECU: a035 uds transaction initiated";
CM_ SG_ 772 PMF_a036_preWatchdog "PMF ECU: a036 pre watchdog";
CM_ SG_ 772 PMF_a037_hvpMIA "PMF ECU: a037 hvp MIA";
CM_ SG_ 772 PMF_a039_disMIA "PMF ECU: a039 dis MIA";
CM_ SG_ 772 PMF_a040_pmMIA "PMF ECU: a040 pm MIA";
CM_ SG_ 772 PMF_a042_gtwMIA "PMF ECU: a042 gtw MIA";
CM_ SG_ 772 PMF_a045_motorMovementDetected "PMF ECU: a045 motor movement detected";
CM_ SG_ 772 PMF_a053_vcfrontMIA "PMF ECU: a053 vcfront MIA";
CM_ SG_ 772 PMF_a054_uiMIA "PMF ECU: a054 ui MIA";
CM_ SG_ 772 PMF_a055_resolver "PMF ECU: a055 resolver";
CM_ SG_ 772 PMF_a056_canHardwareBusB "PMF ECU: a056 can hardware bus b";
CM_ SG_ 772 PMF_a057_canDataBusB "PMF ECU: a057 can data bus b";
CM_ SG_ 772 PMF_a058_measuredHvilCurrentFroz "PMF ECU: a058 measured hvil current frozen";
CM_ SG_ 772 PMF_a061_DIPMVersionMismatch "PMF ECU: a061 DIPM version mismatch";
CM_ SG_ 772 PMF_a062_eccError "PMF ECU: a062 ecc error";
CM_ SG_ 772 PMF_a064_torqueIntervention "PMF ECU: a064 torque intervention";
CM_ SG_ 772 PMF_a080_exceptionPrefetchAbort "PMF ECU: a080 exception prefetch abort";
CM_ SG_ 772 PMF_a081_exceptionDataAbort "PMF ECU: a081 exception data abort";
CM_ SG_ 772 PMF_a082_exceptionDataAbort2 "PMF ECU: a082 exception data abort2";
CM_ SG_ 772 PMF_a083_ahbWriteError "PMF ECU: a083 ahb write error";
CM_ SG_ 772 PMF_a084_exceptionMpuFirewall "PMF ECU: a084 exception mpu firewall";
CM_ SG_ 772 PMF_a086_exceptionUndefinedInstr "PMF ECU: a086 exception undefined instruction";
CM_ SG_ 772 PMF_a092_xtalOscillator "PMF ECU: a092 xtal oscillator";
CM_ SG_ 772 PMF_a094_safetyICWarn "PMF ECU: a094 safety IC warn";
CM_ SG_ 772 PMF_a095_safetyICFault "PMF ECU: a095 safety IC fault";
CM_ SG_ 772 PMF_a096_safetyICDebug "PMF ECU: a096 safety IC debug";
CM_ SG_ 772 PMF_a097_lowFlowAlmostTripped "PMF ECU: a097 low flow almost tripped";
CM_ SG_ 772 PMF_a100_diTraceInfo1 "PMF ECU: a100 di trace info1";
CM_ SG_ 772 PMF_a114_ramScrubTimedOut "PMF ECU: a114 ram scrub timed out";
CM_ SG_ 772 PMF_a121_unintendedReset2 "PMF ECU: a121 unintended reset2";
CM_ BO_ 790 "PMF ECU message: info";
CM_ SG_ 790 PMF_infoIndex "PMF ECU: info index";
CM_ SG_ 790 PMF_buildType "PMF ECU: build type";
CM_ SG_ 790 PMF_buildConfigurationId "PMF ECU: build configuration id";
CM_ SG_ 790 PMF_hardwareId "PMF ECU: hardware id";
CM_ SG_ 790 PMF_deviceFused "PMF ECU: device fused";
CM_ SG_ 790 PMF_componentId "PMF ECU: component id";
CM_ SG_ 790 PMF_pcbaId "PMF ECU: pcba id";
CM_ SG_ 790 PMF_assemblyId "PMF ECU: assembly id";
CM_ SG_ 790 PMF_usageId "PMF ECU: usage id";
CM_ SG_ 790 PMF_subUsageId "PMF ECU: sub usage id";
CM_ SG_ 790 PMF_applicationCrc "PMF ECU: application crc";
CM_ SG_ 790 PMF_appGitHash "PMF ECU: app git hash";
CM_ SG_ 790 PMF_bootGitHash "PMF ECU: boot git hash";
CM_ SG_ 790 PMF_platformTyp "PMF ECU: platform typ";
CM_ SG_ 790 PMF_udsProtocolVersion "PMF ECU: uds protocol version";
CM_ SG_ 790 PMF_bootloaderCrc "PMF ECU: bootloader crc";
CM_ BO_ 1316 "PMF ECU message: mfg data";
CM_ SG_ 1316 PMF_processorDieIdLot "PMF ECU: processor die id lot";
CM_ SG_ 1316 PMF_processorDieIdWafer "PMF ECU: processor die id wafer";
CM_ SG_ 1316 PMF_processorDieIdX "PMF ECU: processor die id x";
CM_ SG_ 1316 PMF_processorDieIdY "PMF ECU: processor die id y";
CM_ BO_ 1620 "PMF ECU message: uds response";
CM_ SG_ 1620 PMF_udsResponseData "PMF ECU: uds response data";
CM_ BO_ 1446 "PMR ECU message: alert log";
CM_ SG_ 1446 PMR_alertID "PMR ECU: alert ID";
CM_ SG_ 1446 PMR_alertState "PMR ECU: alert state";
CM_ SG_ 1446 PMR_a001_w0 "PMR ECU: a001 w0";
CM_ SG_ 1446 PMR_a001_w1 "PMR ECU: a001 w1";
CM_ SG_ 1446 PMR_a001_w2 "PMR ECU: a001 w2";
CM_ SG_ 1446 PMR_a002_torqueAverage "PMR ECU: a002 torque average";
CM_ SG_ 1446 PMR_a002_torqueWindow "PMR ECU: a002 torque window";
CM_ SG_ 1446 PMR_a002_torqueMeasured "PMR ECU: a002 torque measured; raw 4096 = signal not available (SNA)";
CM_ SG_ 1446 PMR_a002_torqueAccelAverage "PMR ECU: a002 torque accel average; raw 4096 = signal not available (SNA)";
CM_ SG_ 1446 PMR_a002_torqueAccelWindow "PMR ECU: a002 torque accel window; raw 4096 = signal not available (SNA)";
CM_ SG_ 1446 PMR_a003_reverseGear "PMR ECU: a003 reverse gear";
CM_ SG_ 1446 PMR_a003_pedalPos "PMR ECU: a003 pedal pos";
CM_ SG_ 1446 PMR_a003_zeroPointPedal "PMR ECU: a003 zero point pedal";
CM_ SG_ 1446 PMR_a004_torqueAverage "PMR ECU: a004 torque average";
CM_ SG_ 1446 PMR_a004_torqueWindow "PMR ECU: a004 torque window";
CM_ SG_ 1446 PMR_a004_torqueMeasured "PMR ECU: a004 torque measured; raw 4096 = signal not available (SNA)";
CM_ SG_ 1446 PMR_a004_torqueDecelAverage "PMR ECU: a004 torque decel average; raw 4096 = signal not available (SNA)";
CM_ SG_ 1446 PMR_a004_torqueDecelWindow "PMR ECU: a004 torque decel window; raw 4096 = signal not available (SNA)";
CM_ SG_ 1446 PMR_a005_torqueReason "PMR ECU: a005 torque reason";
CM_ SG_ 1446 PMR_a005_torqueMeasured "PMR ECU: a005 torque measured; raw 4096 = signal not available (SNA)";
CM_ SG_ 1446 PMR_a005_iDQmagnitude "PMR ECU: a005 i d qmagnitude";
CM_ SG_ 1446 PMR_a006_torqueActual "PMR ECU: a006 torque actual; raw 4096 = signal not available (SNA)";
CM_ SG_ 1446 PMR_a006_motorRPM "PMR ECU: a006 motor RPM";
CM_ SG_ 1446 PMR_a006_torqueMeasured "PMR ECU: a006 torque measured; raw 4096 = signal not available (SNA)";
CM_ SG_ 1446 PMR_a010_messageId "PMR ECU: a010 message id";
CM_ SG_ 1446 PMR_a010_DI_status "PMR ECU: a010 DI status";
CM_ SG_ 1446 PMR_a010_DI_torque "PMR ECU: a010 DI torque";
CM_ SG_ 1446 PMR_a010_DI_slaveCommand "PMR ECU: a010 DI slave command";
CM_ SG_ 1446 PMR_a010_DI_locStatus "PMR ECU: a010 DI loc status";
CM_ SG_ 1446 PMR_a010_DI_speed "PMR ECU: a010 DI speed";
CM_ SG_ 1446 PMR_a010_DI_systemStatus "PMR ECU: a010 DI system status";
CM_ SG_ 1446 PMR_a010_DI_chassisControl "PMR ECU: a010 DI chassis control";
CM_ SG_ 1446 PMR_a010_DI_chassisControl2 "PMR ECU: a010 DI chassis control2";
CM_ SG_ 1446 PMR_a010_vdcLeft "PMR ECU: a010 vdc left";
CM_ SG_ 1446 PMR_a010_vdcRight "PMR ECU: a010 vdc right";
CM_ SG_ 1446 PMR_a010_DI_vehicleEstimates "PMR ECU: a010 DI vehicle estimates";
CM_ SG_ 1446 PMR_a010_DI_brakeCommand "PMR ECU: a010 DI brake command";
CM_ SG_ 1446 PMR_a010_DI_autonomyHealth "PMR ECU: a010 DI autonomy health";
CM_ SG_ 1446 PMR_a010_DI_difCommand "PMR ECU: a010 DI dif command";
CM_ SG_ 1446 PMR_a010_DI_dirCommand "PMR ECU: a010 DI dir command";
CM_ SG_ 1446 PMR_a010_DI_dirVehicle "PMR ECU: a010 DI dir vehicle";
CM_ SG_ 1446 PMR_a010_DI_locStatus2 "PMR ECU: a010 DI loc status2";
CM_ SG_ 1446 PMR_a011_Ia "PMR ECU: a011 ia";
CM_ SG_ 1446 PMR_a011_IaDelta "PMR ECU: a011 ia delta";
CM_ SG_ 1446 PMR_a011_Ib "PMR ECU: a011 ib";
CM_ SG_ 1446 PMR_a011_IbDelta "PMR ECU: a011 ib delta";
CM_ SG_ 1446 PMR_a011_currentVref "PMR ECU: a011 current vref";
CM_ SG_ 1446 PMR_a011_badPhaseAsample "PMR ECU: a011 bad phase asample";
CM_ SG_ 1446 PMR_a011_badPhaseBsample "PMR ECU: a011 bad phase bsample";
CM_ SG_ 1446 PMR_a011_sampleFreeze "PMR ECU: a011 sample freeze";
CM_ SG_ 1446 PMR_a011_rateOfChangeIrrational "PMR ECU: a011 rate of change irrational";
CM_ SG_ 1446 PMR_a011_currentReadingIrrationa "PMR ECU: a011 current reading irrational";
CM_ SG_ 1446 PMR_a011_vrefIrrational "PMR ECU: a011 vref irrational";
CM_ SG_ 1446 PMR_a017_EPBL_status "PMR ECU: a017 EPBL status";
CM_ SG_ 1446 PMR_a017_EPBR_status "PMR ECU: a017 EPBR status";
CM_ SG_ 1446 PMR_a017_EPBL_autonomyHealth "PMR ECU: a017 EPBL autonomy health";
CM_ SG_ 1446 PMR_a017_EPBR_autonomyHealth "PMR ECU: a017 EPBR autonomy health";
CM_ SG_ 1446 PMR_a018_w0 "PMR ECU: a018 w0";
CM_ SG_ 1446 PMR_a018_w1 "PMR ECU: a018 w1";
CM_ SG_ 1446 PMR_a018_w2 "PMR ECU: a018 w2";
CM_ SG_ 1446 PMR_a019_statorTemp1 "PMR ECU: a019 stator temp1";
CM_ SG_ 1446 PMR_a019_statorTslope1 "PMR ECU: a019 stator tslope1";
CM_ SG_ 1446 PMR_a025_sccReset "PMR ECU: a025 scc reset";
CM_ SG_ 1446 PMR_a025_hibernate "PMR ECU: a025 hibernate";
CM_ SG_ 1446 PMR_a025_hwBist "PMR ECU: a025 hw bist";
CM_ SG_ 1446 PMR_a025_nmiWatchdog "PMR ECU: a025 nmi watchdog";
CM_ SG_ 1446 PMR_a025_watchdog "PMR ECU: a025 watchdog";
CM_ SG_ 1446 PMR_a025_clockFailNmi "PMR ECU: a025 clock fail nmi";
CM_ SG_ 1446 PMR_a025_ramUncErrorNmi "PMR ECU: a025 ram unc error nmi";
CM_ SG_ 1446 PMR_a025_flashUncErrorNmi "PMR ECU: a025 flash unc error nmi";
CM_ SG_ 1446 PMR_a025_cpu1signMismatchNmi "PMR ECU: a025 cpu1sign mismatch nmi";
CM_ SG_ 1446 PMR_a025_cpu2signMismatchNmi "PMR ECU: a025 cpu2sign mismatch nmi";
CM_ SG_ 1446 PMR_a025_pieVectErrorNmi "PMR ECU: a025 pie vect error nmi";
CM_ SG_ 1446 PMR_a025_sysDbgNmi "PMR ECU: a025 sys dbg nmi";
CM_ SG_ 1446 PMR_a025_rlNmi "PMR ECU: a025 rl nmi";
CM_ SG_ 1446 PMR_a025_ovfNmi "PMR ECU: a025 ovf nmi";
CM_ SG_ 1446 PMR_a025_possibleSafetyICReset "PMR ECU: a025 possible safety IC reset";
CM_ SG_ 1446 PMR_a025_powerOnReset "PMR ECU: a025 power on reset";
CM_ SG_ 1446 PMR_a025_watchdogTimer0 "PMR ECU: a025 watchdog timer0";
CM_ SG_ 1446 PMR_a025_watchdogTimer1 "PMR ECU: a025 watchdog timer1";
CM_ SG_ 1446 PMR_a025_watchdogTimer2 "PMR ECU: a025 watchdog timer2";
CM_ SG_ 1446 PMR_a025_watchdogTimer3 "PMR ECU: a025 watchdog timer3";
CM_ SG_ 1446 PMR_a025_warmResetReq "PMR ECU: a025 warm reset req";
CM_ SG_ 1446 PMR_a025_externalPadReset "PMR ECU: a025 external pad reset";
CM_ SG_ 1446 PMR_a025_hwSecModuleWatchdogTime "PMR ECU: a025 hw sec module watchdog timer";
CM_ SG_ 1446 PMR_a025_debugReset "PMR ECU: a025 debug reset";
CM_ SG_ 1446 PMR_a025_tempSense0 "PMR ECU: a025 temp sense0";
CM_ SG_ 1446 PMR_a025_tempSense1 "PMR ECU: a025 temp sense1";
CM_ SG_ 1446 PMR_a026_reason "PMR ECU: a026 reason";
CM_ SG_ 1446 PMR_a026_isrCount20kHz "PMR ECU: a026 isr count20k hz";
CM_ SG_ 1446 PMR_a026_isrCount1kHz "PMR ECU: a026 isr count1k hz";
CM_ SG_ 1446 PMR_a026_switchingActive "PMR ECU: a026 switching active";
CM_ SG_ 1446 PMR_a026_systemStackOvf "PMR ECU: a026 system stack ovf";
CM_ SG_ 1446 PMR_a026_controlStackOvf "PMR ECU: a026 control stack ovf";
CM_ SG_ 1446 PMR_a026_idleStackOvf "PMR ECU: a026 idle stack ovf";
CM_ SG_ 1446 PMR_a026_eepStackOvf "PMR ECU: a026 eep stack ovf";
CM_ SG_ 1446 PMR_a026_immStackOvf "PMR ECU: a026 imm stack ovf";
CM_ SG_ 1446 PMR_a026_xdcErrorIdMSW "PMR ECU: a026 xdc error id MSW";
CM_ SG_ 1446 PMR_a026_xdcErrorArg1 "PMR ECU: a026 xdc error arg1";
CM_ SG_ 1446 PMR_a032_w0 "PMR ECU: a032 w0";
CM_ SG_ 1446 PMR_a032_w1 "PMR ECU: a032 w1";
CM_ SG_ 1446 PMR_a032_w2 "PMR ECU: a032 w2";
CM_ SG_ 1446 PMR_a033_state "PMR ECU: a033 state";
CM_ SG_ 1446 PMR_a033_failReason "PMR ECU: a033 fail reason";
CM_ SG_ 1446 PMR_a033_DSADC_Ia "PMR ECU: a033 DSADC ia";
CM_ SG_ 1446 PMR_a033_DSADC_Ib "PMR ECU: a033 DSADC ib";
CM_ SG_ 1446 PMR_a036_timeSinceTxHWI "PMR ECU: a036 time since tx HWI";
CM_ SG_ 1446 PMR_a036_timeSinceRxHWI "PMR ECU: a036 time since rx HWI";
CM_ SG_ 1446 PMR_a036_timeSince100HzTxSWI "PMR ECU: a036 time since100 hz tx SWI";
CM_ SG_ 1446 PMR_a036_timeSince1kHzCLK "PMR ECU: a036 time since1k hz CLK";
CM_ SG_ 1446 PMR_a036_timeSince1kHzSWI "PMR ECU: a036 time since1k hz SWI";
CM_ SG_ 1446 PMR_a036_timeSinceIdle "PMR ECU: a036 time since idle";
CM_ SG_ 1446 PMR_a036_ovfStackId "PMR ECU: a036 ovf stack id; raw 15 = signal not available (SNA)";
CM_ SG_ 1446 PMR_a036_inTxISR "PMR ECU: a036 in tx ISR";
CM_ SG_ 1446 PMR_a036_inTxHWI "PMR ECU: a036 in tx HWI";
CM_ SG_ 1446 PMR_a036_inRxHWI "PMR ECU: a036 in rx HWI";
CM_ SG_ 1446 PMR_a036_in1kHzSWI "PMR ECU: a036 in1k hz SWI";
CM_ SG_ 1446 PMR_a036_in1kHzCLK "PMR ECU: a036 in1k hz CLK";
CM_ SG_ 1446 PMR_a036_in100HzCLK "PMR ECU: a036 in100 hz CLK";
CM_ SG_ 1446 PMR_a036_in10HzCLK "PMR ECU: a036 in10 hz CLK";
CM_ SG_ 1446 PMR_a036_in1HzCLK "PMR ECU: a036 in1 hz CLK";
CM_ SG_ 1446 PMR_a037_hvpFaults "PMR ECU: a037 hvp faults";
CM_ SG_ 1446 PMR_a039_DIS_status "PMR ECU: a039 DIS status";
CM_ SG_ 1446 PMR_a039_DIS_torque "PMR ECU: a039 DIS torque";
CM_ SG_ 1446 PMR_a039_messageId "PMR ECU: a039 message id";
CM_ SG_ 1446 PMR_a040_PM_state "PMR ECU: a040 PM state";
CM_ SG_ 1446 PMR_a040_messageId "PMR ECU: a040 message id";
CM_ SG_ 1446 PMR_a040_PM_locState "PMR ECU: a040 PM loc state";
CM_ SG_ 1446 PMR_a042_GTW_carConfig "PMR ECU: a042 GTW car config";
CM_ SG_ 1446 PMR_a042_GTW_time "PMR ECU: a042 GTW time";
CM_ SG_ 1446 PMR_a042_GTW_drivetrainType "PMR ECU: a042 GTW drivetrain type";
CM_ SG_ 1446 PMR_a042_expectedPerformanceCfg "PMR ECU: a042 expected performance cfg";
CM_ SG_ 1446 PMR_a042_gearControl "PMR ECU: a042 gear control";
CM_ SG_ 1446 PMR_a053_LVPowerState "PMR ECU: a053 LV power state";
CM_ SG_ 1446 PMR_a053_coolant "PMR ECU: a053 coolant";
CM_ SG_ 1446 PMR_a053_vcleftSwitchStatus "PMR ECU: a053 vcleft switch status";
CM_ SG_ 1446 PMR_a053_restraintStatus "PMR ECU: a053 restraint status";
CM_ SG_ 1446 PMR_a053_sensors "PMR ECU: a053 sensors";
CM_ SG_ 1446 PMR_a054_uiPowertrainControl "PMR ECU: a054 ui powertrain control";
CM_ SG_ 1446 PMR_a054_uiChassisControl "PMR ECU: a054 ui chassis control";
CM_ SG_ 1446 PMR_a054_uiCruiseControl "PMR ECU: a054 ui cruise control";
CM_ SG_ 1446 PMR_a054_uiTrackModeSettings "PMR ECU: a054 ui track mode settings";
CM_ SG_ 1446 PMR_a054_uiTPMSRCPSetting "PMR ECU: a054 ui TPMSRCP setting";
CM_ SG_ 1446 PMR_a055_motorRPM "PMR ECU: a055 motor RPM";
CM_ SG_ 1446 PMR_a055_phaseAngle "PMR ECU: a055 phase angle";
CM_ SG_ 1446 PMR_a055_commonGain "PMR ECU: a055 common gain";
CM_ SG_ 1446 PMR_a055_notReady "PMR ECU: a055 not ready";
CM_ SG_ 1446 PMR_a055_noCarrier "PMR ECU: a055 no carrier";
CM_ SG_ 1446 PMR_a055_phaseOutOfSpec "PMR ECU: a055 phase out of spec";
CM_ SG_ 1446 PMR_a055_diElecAngleMismatch "PMR ECU: a055 di elec angle mismatch";
CM_ SG_ 1446 PMR_a055_diSpeedMismatch "PMR ECU: a055 di speed mismatch";
CM_ SG_ 1446 PMR_a055_claMIA "PMR ECU: a055 cla MIA";
CM_ SG_ 1446 PMR_a055_diMIA "PMR ECU: a055 di MIA";
CM_ SG_ 1446 PMR_a055_diElecAngleMismatchWarn "PMR ECU: a055 di elec angle mismatch warn";
CM_ SG_ 1446 PMR_a058_hvilCurrent "PMR ECU: a058 hvil current";
CM_ SG_ 1446 PMR_a061_diIpcVersion "PMR ECU: a061 di ipc version";
CM_ SG_ 1446 PMR_a061_pmIpcVersion "PMR ECU: a061 pm ipc version";
CM_ SG_ 1446 PMR_a062_address "PMR ECU: a062 address";
CM_ SG_ 1446 PMR_a062_errorType "PMR ECU: a062 error type";
CM_ SG_ 1446 PMR_a062_detectedByRamScrub "PMR ECU: a062 detected by ram scrub";
CM_ SG_ 1446 PMR_a064_interventionType "PMR ECU: a064 intervention type";
CM_ SG_ 1446 PMR_a064_torqueCmdState "PMR ECU: a064 torque cmd state; raw 0 = signal not available (SNA)";
CM_ SG_ 1446 PMR_a064_shortDetectedByDI "PMR ECU: a064 short detected by DI";
CM_ SG_ 1446 PMR_a064_UI_stoppingMode "PMR ECU: a064 UI stopping mode";
CM_ SG_ 1446 PMR_a064_diCrsState "PMR ECU: a064 di crs state";
CM_ SG_ 1446 PMR_a064_pmCrsState "PMR ECU: a064 pm crs state";
CM_ SG_ 1446 PMR_a082_faultAddress "PMR ECU: a082 fault address";
CM_ SG_ 1446 PMR_a082_isWriteNotRead "PMR ECU: a082 is write not read";
CM_ SG_ 1446 PMR_a084_faultAddress "PMR ECU: a084 fault address";
CM_ SG_ 1446 PMR_a084_firewallId "PMR ECU: a084 firewall id";
CM_ SG_ 1446 PMR_a084_privId "PMR ECU: a084 priv id";
CM_ SG_ 1446 PMR_a084_ns "PMR ECU: a084 ns";
CM_ SG_ 1446 PMR_a084_faultType "PMR ECU: a084 fault type";
CM_ SG_ 1446 PMR_a092_pllClockSource "PMR ECU: a092 pll clock source";
CM_ SG_ 1446 PMR_a095_wwdErrIntFlag "PMR ECU: a095 wwd err int flag";
CM_ SG_ 1446 PMR_a095_fwdErrIntFlag "PMR ECU: a095 fwd err int flag";
CM_ SG_ 1446 PMR_a095_errMissStsFlag "PMR ECU: a095 err miss sts flag";
CM_ SG_ 1446 PMR_a095_preRegulatorOT "PMR ECU: a095 pre regulator OT";
CM_ SG_ 1446 PMR_a095_ucLdoOT "PMR ECU: a095 uc ldo OT";
CM_ SG_ 1446 PMR_a095_monitoringOT "PMR ECU: a095 monitoring OT";
CM_ SG_ 1446 PMR_a095_preRegulatorVoltShort "PMR ECU: a095 pre regulator volt short";
CM_ SG_ 1446 PMR_a095_ucLdoShort "PMR ECU: a095 uc ldo short";
CM_ SG_ 1446 PMR_a095_standbyLdoShort "PMR ECU: a095 standby ldo short";
CM_ SG_ 1446 PMR_a095_coreVoltShort "PMR ECU: a095 core volt short";
CM_ SG_ 1446 PMR_a095_preRegulatorOV "PMR ECU: a095 pre regulator OV";
CM_ SG_ 1446 PMR_a095_ucLdoOV "PMR ECU: a095 uc ldo OV";
CM_ SG_ 1446 PMR_a095_standbyLdoOV "PMR ECU: a095 standby ldo OV";
CM_ SG_ 1446 PMR_a095_coreOV "PMR ECU: a095 core OV";
CM_ SG_ 1446 PMR_a095_voltRefOV "PMR ECU: a095 volt ref OV";
CM_ SG_ 1446 PMR_a095_ucLdoUV "PMR ECU: a095 uc ldo UV";
CM_ SG_ 1446 PMR_a095_standbyLdoUV "PMR ECU: a095 standby ldo UV";
CM_ SG_ 1446 PMR_a095_coreUV "PMR ECU: a095 core UV";
CM_ SG_ 1446 PMR_a095_supplyVoltOV "PMR ECU: a095 supply volt OV";
CM_ SG_ 1446 PMR_a095_bandgapComparatorUV "PMR ECU: a095 bandgap comparator UV";
CM_ SG_ 1446 PMR_a095_bandgapComparatorOV "PMR ECU: a095 bandgap comparator OV";
CM_ SG_ 1446 PMR_a095_biasCurrentTooLow "PMR ECU: a095 bias current too low";
CM_ SG_ 1446 PMR_a095_biasCurrentTooHigh "PMR ECU: a095 bias current too high";
CM_ SG_ 1446 PMR_a095_safetyICstate "PMR ECU: a095 safety i cstate";
CM_ SG_ 1446 PMR_a095_motorRPM "PMR ECU: a095 motor RPM";
CM_ SG_ 1446 PMR_a095_wwdErrCounter "PMR ECU: a095 wwd err counter";
CM_ SG_ 1446 PMR_a095_fwdErrCounter "PMR ECU: a095 fwd err counter";
CM_ SG_ 1446 PMR_a100_index1kHzPeriodic "PMR ECU: a100 index1k hz periodic";
CM_ SG_ 1446 PMR_a100_index100HzPeriodic "PMR ECU: a100 index100 hz periodic";
CM_ SG_ 1446 PMR_a100_index10HzPeriodic "PMR ECU: a100 index10 hz periodic";
CM_ SG_ 1446 PMR_a100_indexSWI "PMR ECU: a100 index SWI";
CM_ SG_ 1446 PMR_a100_eepEvent "PMR ECU: a100 eep event";
CM_ SG_ 1446 PMR_a100_module500HzActive "PMR ECU: a100 module500 hz active";
CM_ SG_ 1446 PMR_a100_module50HzActive "PMR ECU: a100 module50 hz active";
CM_ SG_ 1446 PMR_a100_module1HzActive "PMR ECU: a100 module1 hz active";
CM_ SG_ 1446 PMR_a100_task10HzActive "PMR ECU: a100 task10 hz active";
CM_ SG_ 1446 PMR_a100_taskUdsActive "PMR ECU: a100 task uds active";
CM_ SG_ 1446 PMR_a101_VDDA18_ref33_uv "PMR ECU: a101 VDDA18 ref33 uv";
CM_ SG_ 1446 PMR_a101_VBGAP09_ov "PMR ECU: a101 VBGAP09 ov";
CM_ SG_ 1446 PMR_a101_VBGAP09_uv "PMR ECU: a101 VBGAP09 uv";
CM_ SG_ 1446 PMR_a101_VDDA18_refBGAP_ov "PMR ECU: a101 VDDA18 ref BGAP ov";
CM_ SG_ 1446 PMR_a101_VDDA18_refBGAP_uv "PMR ECU: a101 VDDA18 ref BGAP uv";
CM_ SG_ 1446 PMR_a101_VDD12_ov "PMR ECU: a101 VDD12 ov";
CM_ SG_ 1446 PMR_a101_VDD12_uv "PMR ECU: a101 VDD12 uv";
CM_ SG_ 1446 PMR_a101_VDDSBIO_ov "PMR ECU: a101 VDDSBIO ov";
CM_ SG_ 1446 PMR_a101_VDDSBIO_uv "PMR ECU: a101 VDDSBIO uv";
CM_ SG_ 1446 PMR_a101_VSYS_MON_uv "PMR ECU: a101 VSYS MON uv";
CM_ SG_ 1446 PMR_a101_VDDA33_uv "PMR ECU: a101 VDDA33 uv";
CM_ SG_ 1446 PMR_a101_ADC0_REF_ov "PMR ECU: a101 ADC0 REF ov";
CM_ SG_ 1446 PMR_a101_ADC0_REF_uv "PMR ECU: a101 ADC0 REF uv";
CM_ SG_ 1446 PMR_a101_ADC12_REF_ov "PMR ECU: a101 ADC12 REF ov";
CM_ SG_ 1446 PMR_a101_ADC12_REF_uv "PMR ECU: a101 ADC12 REF uv";
CM_ SG_ 1446 PMR_a101_ADC34_REF_ov "PMR ECU: a101 ADC34 REF ov";
CM_ SG_ 1446 PMR_a101_ADC34_REF_uv "PMR ECU: a101 ADC34 REF uv";
CM_ SG_ 1446 PMR_a101_ADCR01_REF_ov "PMR ECU: a101 ADCR01 REF ov";
CM_ SG_ 1446 PMR_a101_ADCR01_REF_uv "PMR ECU: a101 ADCR01 REF uv";
CM_ BO_ 902 "PMR ECU message: alert matrix";
CM_ SG_ 902 PMR_matrixIndex "PMR ECU: matrix index";
CM_ SG_ 902 PMR_a001_absoluteTorque "PMR ECU: a001 absolute torque";
CM_ SG_ 902 PMR_a002_excessiveAccelTorque "PMR ECU: a002 excessive accel torque";
CM_ SG_ 902 PMR_a003_excessiveReversalTorque "PMR ECU: a003 excessive reversal torque";
CM_ SG_ 902 PMR_a004_excessiveDecelTorque "PMR ECU: a004 excessive decel torque";
CM_ SG_ 902 PMR_a005_torqueInNeutralOrPark "PMR ECU: a005 torque in neutral or park";
CM_ SG_ 902 PMR_a006_underTorqueCheck "PMR ECU: a006 under torque check";
CM_ SG_ 902 PMR_a008_memoryError "PMR ECU: a008 memory error";
CM_ SG_ 902 PMR_a010_diMIA "PMR ECU: a010 di MIA";
CM_ SG_ 902 PMR_a011_phaseCurrentIrrational "PMR ECU: a011 phase current irrational";
CM_ SG_ 902 PMR_a012_canDataBusA "PMR ECU: a012 can data bus a";
CM_ SG_ 902 PMR_a013_canHardwareBusA "PMR ECU: a013 can hardware bus a";
CM_ SG_ 902 PMR_a017_brakeMIA "PMR ECU: a017 brake MIA";
CM_ SG_ 902 PMR_a018_encoderIrrational "PMR ECU: a018 encoder irrational";
CM_ SG_ 902 PMR_a019_statorTempIrrational "PMR ECU: a019 stator temp irrational";
CM_ SG_ 902 PMR_a025_unintendedReset "PMR ECU: a025 unintended reset";
CM_ SG_ 902 PMR_a026_diHeartBeatMIA "PMR ECU: a026 di heart beat MIA";
CM_ SG_ 902 PMR_a027_torqueEstimationOutOfBo "PMR ECU: a027 torque estimation out of bounds";
CM_ SG_ 902 PMR_a028_torqueCmdError "PMR ECU: a028 torque cmd error";
CM_ SG_ 902 PMR_a031_highStackUsage "PMR ECU: a031 high stack usage";
CM_ SG_ 902 PMR_a032_registerConfigError "PMR ECU: a032 register config error";
CM_ SG_ 902 PMR_a033_selfTest "PMR ECU: a033 self test";
CM_ SG_ 902 PMR_a034_trqCrossCheck "PMR ECU: a034 trq cross check";
CM_ SG_ 902 PMR_a035_udsTransactionInitiated "PMR ECU: a035 uds transaction initiated";
CM_ SG_ 902 PMR_a036_preWatchdog "PMR ECU: a036 pre watchdog";
CM_ SG_ 902 PMR_a037_hvpMIA "PMR ECU: a037 hvp MIA";
CM_ SG_ 902 PMR_a039_disMIA "PMR ECU: a039 dis MIA";
CM_ SG_ 902 PMR_a040_pmMIA "PMR ECU: a040 pm MIA";
CM_ SG_ 902 PMR_a042_gtwMIA "PMR ECU: a042 gtw MIA";
CM_ SG_ 902 PMR_a045_motorMovementDetected "PMR ECU: a045 motor movement detected";
CM_ SG_ 902 PMR_a053_vcfrontMIA "PMR ECU: a053 vcfront MIA";
CM_ SG_ 902 PMR_a054_uiMIA "PMR ECU: a054 ui MIA";
CM_ SG_ 902 PMR_a055_resolver "PMR ECU: a055 resolver";
CM_ SG_ 902 PMR_a056_canHardwareBusB "PMR ECU: a056 can hardware bus b";
CM_ SG_ 902 PMR_a057_canDataBusB "PMR ECU: a057 can data bus b";
CM_ SG_ 902 PMR_a058_measuredHvilCurrentFroz "PMR ECU: a058 measured hvil current frozen";
CM_ SG_ 902 PMR_a061_DIPMVersionMismatch "PMR ECU: a061 DIPM version mismatch";
CM_ SG_ 902 PMR_a062_eccError "PMR ECU: a062 ecc error";
CM_ SG_ 902 PMR_a064_torqueIntervention "PMR ECU: a064 torque intervention";
CM_ SG_ 902 PMR_a080_exceptionPrefetchAbort "PMR ECU: a080 exception prefetch abort";
CM_ SG_ 902 PMR_a081_exceptionDataAbort "PMR ECU: a081 exception data abort";
CM_ SG_ 902 PMR_a082_exceptionDataAbort2 "PMR ECU: a082 exception data abort2";
CM_ SG_ 902 PMR_a083_ahbWriteError "PMR ECU: a083 ahb write error";
CM_ SG_ 902 PMR_a084_exceptionMpuFirewall "PMR ECU: a084 exception mpu firewall";
CM_ SG_ 902 PMR_a086_exceptionUndefinedInstr "PMR ECU: a086 exception undefined instruction";
CM_ SG_ 902 PMR_a092_xtalOscillator "PMR ECU: a092 xtal oscillator";
CM_ SG_ 902 PMR_a094_safetyICWarn "PMR ECU: a094 safety IC warn";
CM_ SG_ 902 PMR_a095_safetyICFault "PMR ECU: a095 safety IC fault";
CM_ SG_ 902 PMR_a096_safetyICDebug "PMR ECU: a096 safety IC debug";
CM_ SG_ 902 PMR_a097_lowFlowAlmostTripped "PMR ECU: a097 low flow almost tripped";
CM_ SG_ 902 PMR_a100_diTraceInfo1 "PMR ECU: a100 di trace info1";
CM_ SG_ 902 PMR_a101_hwVoltageMonitorTrip "PMR ECU: a101 hw voltage monitor trip";
CM_ SG_ 902 PMR_a102_ipcFluidTempHigh "PMR ECU: a102 ipc fluid temp high";
CM_ SG_ 902 PMR_a114_ramScrubTimedOut "PMR ECU: a114 ram scrub timed out";
CM_ SG_ 902 PMR_a121_unintendedReset2 "PMR ECU: a121 unintended reset2";
CM_ BO_ 1748 "PMR ECU message: info";
CM_ SG_ 1748 PMR_infoIndex "PMR ECU: info index";
CM_ SG_ 1748 PMR_buildType "PMR ECU: build type";
CM_ SG_ 1748 PMR_buildConfigurationId "PMR ECU: build configuration id";
CM_ SG_ 1748 PMR_hardwareId "PMR ECU: hardware id";
CM_ SG_ 1748 PMR_deviceFused "PMR ECU: device fused";
CM_ SG_ 1748 PMR_componentId "PMR ECU: component id";
CM_ SG_ 1748 PMR_pcbaId "PMR ECU: pcba id";
CM_ SG_ 1748 PMR_assemblyId "PMR ECU: assembly id";
CM_ SG_ 1748 PMR_usageId "PMR ECU: usage id";
CM_ SG_ 1748 PMR_subUsageId "PMR ECU: sub usage id";
CM_ SG_ 1748 PMR_applicationCrc "PMR ECU: application crc";
CM_ SG_ 1748 PMR_appGitHash "PMR ECU: app git hash";
CM_ SG_ 1748 PMR_bootGitHash "PMR ECU: boot git hash";
CM_ SG_ 1748 PMR_platformTyp "PMR ECU: platform typ";
CM_ SG_ 1748 PMR_udsProtocolVersion "PMR ECU: uds protocol version";
CM_ SG_ 1748 PMR_bootloaderCrc "PMR ECU: bootloader crc";
CM_ BO_ 2023 "PMR ECU message: mfg data";
CM_ SG_ 2023 PMR_processorDieIdLot "PMR ECU: processor die id lot";
CM_ SG_ 2023 PMR_processorDieIdWafer "PMR ECU: processor die id wafer";
CM_ SG_ 2023 PMR_processorDieIdX "PMR ECU: processor die id x";
CM_ SG_ 2023 PMR_processorDieIdY "PMR ECU: processor die id y";
CM_ BO_ 1556 "PMR ECU message: uds response";
CM_ SG_ 1556 PMR_udsResponseData "PMR ECU: uds response data";
CM_ BO_ 1444 "PM ECU message: alert log";
CM_ SG_ 1444 PM_alertID "PM ECU: alert ID";
CM_ SG_ 1444 PM_alertState "PM ECU: alert state";
CM_ SG_ 1444 PM_a001_w0 "PM ECU: a001 w0";
CM_ SG_ 1444 PM_a001_w1 "PM ECU: a001 w1";
CM_ SG_ 1444 PM_a001_w2 "PM ECU: a001 w2";
CM_ SG_ 1444 PM_a002_torqueAverage "PM ECU: a002 torque average";
CM_ SG_ 1444 PM_a002_torqueWindow "PM ECU: a002 torque window";
CM_ SG_ 1444 PM_a002_torqueMeasured "PM ECU: a002 torque measured; raw 4096 = signal not available (SNA)";
CM_ SG_ 1444 PM_a002_torqueAccelAverage "PM ECU: a002 torque accel average; raw 4096 = signal not available (SNA)";
CM_ SG_ 1444 PM_a002_torqueAccelWindow "PM ECU: a002 torque accel window; raw 4096 = signal not available (SNA)";
CM_ SG_ 1444 PM_a003_torqueMeasured "PM ECU: a003 torque measured; raw 4096 = signal not available (SNA)";
CM_ SG_ 1444 PM_a003_torqueCommanded "PM ECU: a003 torque commanded; raw 4096 = signal not available (SNA)";
CM_ SG_ 1444 PM_a003_reverseGear "PM ECU: a003 reverse gear";
CM_ SG_ 1444 PM_a003_pedalPos "PM ECU: a003 pedal pos";
CM_ SG_ 1444 PM_a003_zeroPointPedal "PM ECU: a003 zero point pedal";
CM_ SG_ 1444 PM_a004_torqueAverage "PM ECU: a004 torque average";
CM_ SG_ 1444 PM_a004_torqueWindow "PM ECU: a004 torque window";
CM_ SG_ 1444 PM_a004_torqueMeasured "PM ECU: a004 torque measured; raw 4096 = signal not available (SNA)";
CM_ SG_ 1444 PM_a004_torqueDecelAverage "PM ECU: a004 torque decel average; raw 4096 = signal not available (SNA)";
CM_ SG_ 1444 PM_a004_torqueDecelWindow "PM ECU: a004 torque decel window; raw 4096 = signal not available (SNA)";
CM_ SG_ 1444 PM_a005_torqueReason "PM ECU: a005 torque reason";
CM_ SG_ 1444 PM_a005_torqueMeasured "PM ECU: a005 torque measured; raw 4096 = signal not available (SNA)";
CM_ SG_ 1444 PM_a005_iDQmagnitude "PM ECU: a005 i d qmagnitude";
CM_ SG_ 1444 PM_a006_unknownGearAllowed "PM ECU: a006 unknown gear allowed";
CM_ SG_ 1444 PM_a006_parkGearAllowed "PM ECU: a006 park gear allowed";
CM_ SG_ 1444 PM_a006_reverseGearAllowed "PM ECU: a006 reverse gear allowed";
CM_ SG_ 1444 PM_a006_neutralGearAllowed "PM ECU: a006 neutral gear allowed";
CM_ SG_ 1444 PM_a006_driveGearAllowed "PM ECU: a006 drive gear allowed";
CM_ SG_ 1444 PM_a006_shiftState "PM ECU: a006 shift state; raw 7 = signal not available (SNA)";
CM_ SG_ 1444 PM_a006_brakePedalPress "PM ECU: a006 brake pedal press";
CM_ SG_ 1444 PM_a006_accelPedalBelowLimit "PM ECU: a006 accel pedal below limit";
CM_ SG_ 1444 PM_a006_allowReverseShiftSpeed "PM ECU: a006 allow reverse shift speed";
CM_ SG_ 1444 PM_a006_allowDriveShiftSpeed "PM ECU: a006 allow drive shift speed";
CM_ SG_ 1444 PM_a006_requireAccelPedalCheckSp "PM ECU: a006 require accel pedal check speed";
CM_ SG_ 1444 PM_a006_requireParkSpeed "PM ECU: a006 require park speed";
CM_ SG_ 1444 PM_a006_stalkCommandP "PM ECU: a006 stalk command p";
CM_ SG_ 1444 PM_a006_stalkCommandR "PM ECU: a006 stalk command r";
CM_ SG_ 1444 PM_a006_stalkCommandN "PM ECU: a006 stalk command n";
CM_ SG_ 1444 PM_a006_stalkCommandD "PM ECU: a006 stalk command d";
CM_ SG_ 1444 PM_a006_unsecuredNeutralRequest "PM ECU: a006 unsecured neutral request";
CM_ SG_ 1444 PM_a006_recentGearChange "PM ECU: a006 recent gear change";
CM_ SG_ 1444 PM_a006_smartShiftCommandD "PM ECU: a006 smart shift command d";
CM_ SG_ 1444 PM_a006_smartShiftCommandR "PM ECU: a006 smart shift command r";
CM_ SG_ 1444 PM_a006_driverSeatbeltBuckled "PM ECU: a006 driver seatbelt buckled";
CM_ SG_ 1444 PM_a006_secGearSelRisingEdgeR "PM ECU: a006 sec gear sel rising edge r";
CM_ SG_ 1444 PM_a006_secGearSelRisingEdgeN "PM ECU: a006 sec gear sel rising edge n";
CM_ SG_ 1444 PM_a006_secGearSelRisingEdgeD "PM ECU: a006 sec gear sel rising edge d";
CM_ SG_ 1444 PM_a007_IBST_party1 "PM ECU: a007 IBST party1";
CM_ SG_ 1444 PM_a007_BUS1_IBST_status "PM ECU: a007 BUS1 IBST status";
CM_ SG_ 1444 PM_a007_BUS2_IBST_status "PM ECU: a007 BUS2 IBST status";
CM_ SG_ 1444 PM_a009_ESP_brakeTorque "PM ECU: a009 ESP brake torque";
CM_ SG_ 1444 PM_a009_ESP_motorLimits "PM ECU: a009 ESP motor limits";
CM_ SG_ 1444 PM_a009_ESP_offsets "PM ECU: a009 ESP offsets";
CM_ SG_ 1444 PM_a009_ESP_party3 "PM ECU: a009 ESP party3";
CM_ SG_ 1444 PM_a009_ESP_status "PM ECU: a009 ESP status";
CM_ SG_ 1444 PM_a009_ESP_wheelSpeeds "PM ECU: a009 ESP wheel speeds";
CM_ SG_ 1444 PM_a010_messageId "PM ECU: a010 message id";
CM_ SG_ 1444 PM_a010_DI_status "PM ECU: a010 DI status";
CM_ SG_ 1444 PM_a010_DI_torque "PM ECU: a010 DI torque";
CM_ SG_ 1444 PM_a010_DI_slaveCommand "PM ECU: a010 DI slave command";
CM_ SG_ 1444 PM_a010_DI_locStatus "PM ECU: a010 DI loc status";
CM_ SG_ 1444 PM_a010_DI_speed "PM ECU: a010 DI speed";
CM_ SG_ 1444 PM_a010_DI_systemStatus "PM ECU: a010 DI system status";
CM_ SG_ 1444 PM_a010_DI_chassisControl "PM ECU: a010 DI chassis control";
CM_ SG_ 1444 PM_a010_DI_chassisControl2 "PM ECU: a010 DI chassis control2";
CM_ SG_ 1444 PM_a010_vdcLeft "PM ECU: a010 vdc left";
CM_ SG_ 1444 PM_a010_vdcRight "PM ECU: a010 vdc right";
CM_ SG_ 1444 PM_a010_DI_vehicleEstimates "PM ECU: a010 DI vehicle estimates";
CM_ SG_ 1444 PM_a010_DI_brakeCommand "PM ECU: a010 DI brake command";
CM_ SG_ 1444 PM_a010_DI_autonomyHealth "PM ECU: a010 DI autonomy health";
CM_ SG_ 1444 PM_a010_DI_difCommand "PM ECU: a010 DI dif command";
CM_ SG_ 1444 PM_a010_DI_dirCommand "PM ECU: a010 DI dir command";
CM_ SG_ 1444 PM_a010_DI_dirVehicle "PM ECU: a010 DI dir vehicle";
CM_ SG_ 1444 PM_a010_DI_locStatus2 "PM ECU: a010 DI loc status2";
CM_ SG_ 1444 PM_a010_stalklessInterfaces "PM ECU: a010 stalkless interfaces";
CM_ SG_ 1444 PM_a011_pmfHvilStatus "PM ECU: a011 pmf hvil status; raw 3 = signal not available (SNA)";
CM_ SG_ 1444 PM_a011_pmfStatusValid "PM ECU: a011 pmf status valid";
CM_ SG_ 1444 PM_a011_pmrHvilStatus "PM ECU: a011 pmr hvil status; raw 3 = signal not available (SNA)";
CM_ SG_ 1444 PM_a011_pmrStatusValid "PM ECU: a011 pmr status valid";
CM_ SG_ 1444 PM_a011_vehiclePowerState "PM ECU: a011 vehicle power state";
CM_ SG_ 1444 PM_a011_hvilSystemStatus "PM ECU: a011 hvil system status; raw 3 = signal not available (SNA)";
CM_ SG_ 1444 PM_a014_track1Voltage "PM ECU: a014 track1 voltage";
CM_ SG_ 1444 PM_a014_track2Voltage "PM ECU: a014 track2 voltage";
CM_ SG_ 1444 PM_a014_accelErrorType "PM ECU: a014 accel error type; raw 0 = signal not available (SNA)";
CM_ SG_ 1444 PM_a015_SCCM_rightStalk "PM ECU: a015 SCCM right stalk";
CM_ SG_ 1444 PM_a016_BB_status "PM ECU: a016 BB status";
CM_ SG_ 1444 PM_a016_BB_brakeActuation "PM ECU: a016 BB brake actuation";
CM_ SG_ 1444 PM_a017_EPBL_status "PM ECU: a017 EPBL status";
CM_ SG_ 1444 PM_a017_EPBR_status "PM ECU: a017 EPBR status";
CM_ SG_ 1444 PM_a017_EPBL_autonomyHealth "PM ECU: a017 EPBL autonomy health";
CM_ SG_ 1444 PM_a017_EPBR_autonomyHealth "PM ECU: a017 EPBR autonomy health";
CM_ SG_ 1444 PM_a021_torque "PM ECU: a021 torque";
CM_ SG_ 1444 PM_a021_capability "PM ECU: a021 capability";
CM_ SG_ 1444 PM_a021_status "PM ECU: a021 status";
CM_ SG_ 1444 PM_a021_capability2 "PM ECU: a021 capability2";
CM_ SG_ 1444 PM_a021_power "PM ECU: a021 power";
CM_ SG_ 1444 PM_a022_torque "PM ECU: a022 torque";
CM_ SG_ 1444 PM_a022_capability "PM ECU: a022 capability";
CM_ SG_ 1444 PM_a022_status "PM ECU: a022 status";
CM_ SG_ 1444 PM_a022_capability2 "PM ECU: a022 capability2";
CM_ SG_ 1444 PM_a022_power "PM ECU: a022 power";
CM_ SG_ 1444 PM_a023_diCrsState "PM ECU: a023 di crs state";
CM_ SG_ 1444 PM_a023_pmCrsState "PM ECU: a023 pm crs state";
CM_ SG_ 1444 PM_a023_crsFaultReason "PM ECU: a023 crs fault reason";
CM_ SG_ 1444 PM_a023_crsCancelReason "PM ECU: a023 crs cancel reason";
CM_ SG_ 1444 PM_a023_cruiseTorquePed "PM ECU: a023 cruise torque ped";
CM_ SG_ 1444 PM_a023_wheelSpdEstimateAbs "PM ECU: a023 wheel spd estimate abs";
CM_ SG_ 1444 PM_a023_accelEstimateDis "PM ECU: a023 accel estimate dis";
CM_ SG_ 1444 PM_a025_powerOnReset "PM ECU: a025 power on reset";
CM_ SG_ 1444 PM_a025_watchdogTimer0 "PM ECU: a025 watchdog timer0";
CM_ SG_ 1444 PM_a025_watchdogTimer1 "PM ECU: a025 watchdog timer1";
CM_ SG_ 1444 PM_a025_watchdogTimer2 "PM ECU: a025 watchdog timer2";
CM_ SG_ 1444 PM_a025_watchdogTimer3 "PM ECU: a025 watchdog timer3";
CM_ SG_ 1444 PM_a025_warmResetReq "PM ECU: a025 warm reset req";
CM_ SG_ 1444 PM_a025_externalPadReset "PM ECU: a025 external pad reset";
CM_ SG_ 1444 PM_a025_hwSecModuleWatchdogTimer "PM ECU: a025 hw sec module watchdog timer";
CM_ SG_ 1444 PM_a025_debugReset "PM ECU: a025 debug reset";
CM_ SG_ 1444 PM_a025_tempSense0 "PM ECU: a025 temp sense0";
CM_ SG_ 1444 PM_a025_tempSense1 "PM ECU: a025 temp sense1";
CM_ SG_ 1444 PM_a026_reason "PM ECU: a026 reason";
CM_ SG_ 1444 PM_a026_isrCount20kHz "PM ECU: a026 isr count20k hz";
CM_ SG_ 1444 PM_a026_isrCount1kHz "PM ECU: a026 isr count1k hz";
CM_ SG_ 1444 PM_a026_switchingActive "PM ECU: a026 switching active";
CM_ SG_ 1444 PM_a026_systemStackOvf "PM ECU: a026 system stack ovf";
CM_ SG_ 1444 PM_a026_controlStackOvf "PM ECU: a026 control stack ovf";
CM_ SG_ 1444 PM_a026_idleStackOvf "PM ECU: a026 idle stack ovf";
CM_ SG_ 1444 PM_a026_eepStackOvf "PM ECU: a026 eep stack ovf";
CM_ SG_ 1444 PM_a026_immStackOvf "PM ECU: a026 imm stack ovf";
CM_ SG_ 1444 PM_a026_xdcErrorIdMSW "PM ECU: a026 xdc error id MSW";
CM_ SG_ 1444 PM_a026_xdcErrorArg1 "PM ECU: a026 xdc error arg1";
CM_ SG_ 1444 PM_a030_diAebState "PM ECU: a030 di aeb state; raw 7 = signal not available (SNA)";
CM_ SG_ 1444 PM_a030_pmAebState "PM ECU: a030 pm aeb state; raw 7 = signal not available (SNA)";
CM_ SG_ 1444 PM_a030_dasAebEvent "PM ECU: a030 das aeb event; raw 3 = signal not available (SNA)";
CM_ SG_ 1444 PM_a030_aebFaultReason "PM ECU: a030 aeb fault reason";
CM_ SG_ 1444 PM_a030_aebUnavailableReason "PM ECU: a030 aeb unavailable reason";
CM_ SG_ 1444 PM_a030_aebCancelReason "PM ECU: a030 aeb cancel reason";
CM_ SG_ 1444 PM_a030_diBrakeTorqueCommand "PM ECU: a030 di brake torque command";
CM_ SG_ 1444 PM_a032_w0 "PM ECU: a032 w0";
CM_ SG_ 1444 PM_a032_w1 "PM ECU: a032 w1";
CM_ SG_ 1444 PM_a032_w2 "PM ECU: a032 w2";
CM_ SG_ 1444 PM_a036_timeSinceTxHWI "PM ECU: a036 time since tx HWI";
CM_ SG_ 1444 PM_a036_timeSinceRxHWI "PM ECU: a036 time since rx HWI";
CM_ SG_ 1444 PM_a036_timeSince100HzTxSWI "PM ECU: a036 time since100 hz tx SWI";
CM_ SG_ 1444 PM_a036_timeSince1kHzCLK "PM ECU: a036 time since1k hz CLK";
CM_ SG_ 1444 PM_a036_timeSince1kHzSWI "PM ECU: a036 time since1k hz SWI";
CM_ SG_ 1444 PM_a036_timeSinceIdle "PM ECU: a036 time since idle";
CM_ SG_ 1444 PM_a036_ovfStackId "PM ECU: a036 ovf stack id; raw 15 = signal not available (SNA)";
CM_ SG_ 1444 PM_a036_inTxISR "PM ECU: a036 in tx ISR";
CM_ SG_ 1444 PM_a036_inTxHWI "PM ECU: a036 in tx HWI";
CM_ SG_ 1444 PM_a036_inRxHWI "PM ECU: a036 in rx HWI";
CM_ SG_ 1444 PM_a036_in1kHzSWI "PM ECU: a036 in1k hz SWI";
CM_ SG_ 1444 PM_a036_in1kHzCLK "PM ECU: a036 in1k hz CLK";
CM_ SG_ 1444 PM_a036_in100HzCLK "PM ECU: a036 in100 hz CLK";
CM_ SG_ 1444 PM_a036_in10HzCLK "PM ECU: a036 in10 hz CLK";
CM_ SG_ 1444 PM_a036_in1HzCLK "PM ECU: a036 in1 hz CLK";
CM_ SG_ 1444 PM_a038_masterTorque "PM ECU: a038 master torque";
CM_ SG_ 1444 PM_a038_slaveTorque "PM ECU: a038 slave torque";
CM_ SG_ 1444 PM_a038_pedalPos "PM ECU: a038 pedal pos";
CM_ SG_ 1444 PM_a039_DIS_status "PM ECU: a039 DIS status";
CM_ SG_ 1444 PM_a039_DIS_torque "PM ECU: a039 DIS torque";
CM_ SG_ 1444 PM_a039_messageId "PM ECU: a039 message id";
CM_ SG_ 1444 PM_a041_DAS_control "PM ECU: a041 DAS control";
CM_ SG_ 1444 PM_a041_DAS_longControl "PM ECU: a041 DAS long control";
CM_ SG_ 1444 PM_a041_DAS_longControlTuningPar "PM ECU: a041 DAS long control tuning parameters";
CM_ SG_ 1444 PM_a041_DAS_status "PM ECU: a041 DAS status";
CM_ SG_ 1444 PM_a041_DAS_status2 "PM ECU: a041 DAS status2";
CM_ SG_ 1444 PM_a041_DAS_smartShift "PM ECU: a041 DAS smart shift";
CM_ SG_ 1444 PM_a041_DAS_autonomyControl "PM ECU: a041 DAS autonomy control";
CM_ SG_ 1444 PM_a042_GTW_carConfig "PM ECU: a042 GTW car config";
CM_ SG_ 1444 PM_a042_GTW_time "PM ECU: a042 GTW time";
CM_ SG_ 1444 PM_a042_GTW_drivetrainType "PM ECU: a042 GTW drivetrain type";
CM_ SG_ 1444 PM_a042_expectedPerformanceCfg "PM ECU: a042 expected performance cfg";
CM_ SG_ 1444 PM_a042_gearControl "PM ECU: a042 gear control";
CM_ SG_ 1444 PM_a043_configInconsistent "PM ECU: a043 config inconsistent";
CM_ SG_ 1444 PM_a043_GTW_autopilot "PM ECU: a043 GTW autopilot";
CM_ SG_ 1444 PM_a043_expectedAutopilot "PM ECU: a043 expected autopilot";
CM_ SG_ 1444 PM_a043_GTW_drivetrainType "PM ECU: a043 GTW drivetrain type";
CM_ SG_ 1444 PM_a043_expectedDrivetrainType "PM ECU: a043 expected drivetrain type";
CM_ SG_ 1444 PM_a043_GTW_chassisType "PM ECU: a043 GTW chassis type";
CM_ SG_ 1444 PM_a043_expectedChassisType "PM ECU: a043 expected chassis type";
CM_ SG_ 1444 PM_a043_packEnergy "PM ECU: a043 pack energy";
CM_ SG_ 1444 PM_a043_packPerformanceDeviation "PM ECU: a043 pack performance deviation";
CM_ SG_ 1444 PM_a043_performancePackage "PM ECU: a043 performance package";
CM_ SG_ 1444 PM_a043_GTW_vdcType "PM ECU: a043 GTW vdc type";
CM_ SG_ 1444 PM_a043_expectedVdcType "PM ECU: a043 expected vdc type";
CM_ SG_ 1444 PM_a043_brakeHWType "PM ECU: a043 brake HW type";
CM_ SG_ 1444 PM_a043_cabinPTCHeaterType "PM ECU: a043 cabin PTC heater type";
CM_ SG_ 1444 PM_a043_softPerformanceLimit "PM ECU: a043 soft performance limit";
CM_ SG_ 1444 PM_a043_GTW_dasHw "PM ECU: a043 GTW das hw";
CM_ SG_ 1444 PM_a044_pmCruiseState "PM ECU: a044 pm cruise state";
CM_ SG_ 1444 PM_a044_diCruiseState "PM ECU: a044 di cruise state";
CM_ SG_ 1444 PM_a044_pmAebState "PM ECU: a044 pm aeb state; raw 7 = signal not available (SNA)";
CM_ SG_ 1444 PM_a044_diAebState "PM ECU: a044 di aeb state; raw 7 = signal not available (SNA)";
CM_ SG_ 1444 PM_a044_diBrakeTorqueCommand "PM ECU: a044 di brake torque command";
CM_ SG_ 1444 PM_a044_pmBfillTorqueAllowed "PM ECU: a044 pm bfill torque allowed";
CM_ SG_ 1444 PM_a044_pmVehicleHoldState "PM ECU: a044 pm vehicle hold state";
CM_ SG_ 1444 PM_a044_diVehicleHoldState "PM ECU: a044 di vehicle hold state";
CM_ SG_ 1444 PM_a044_regenBackfillPmState "PM ECU: a044 regen backfill pm state";
CM_ SG_ 1444 PM_a045_regenBackfillPmState "PM ECU: a045 regen backfill pm state";
CM_ SG_ 1444 PM_a045_regenBackfillDiState "PM ECU: a045 regen backfill di state";
CM_ SG_ 1444 PM_a045_unavailableReason "PM ECU: a045 unavailable reason";
CM_ SG_ 1444 PM_a045_diBrakeTorqueCommand "PM ECU: a045 di brake torque command";
CM_ SG_ 1444 PM_a045_pmBrakeTorqueAllowed "PM ECU: a045 pm brake torque allowed";
CM_ SG_ 1444 PM_a046_diVhldState "PM ECU: a046 di vhld state";
CM_ SG_ 1444 PM_a046_pmVhldState "PM ECU: a046 pm vhld state";
CM_ SG_ 1444 PM_a046_vhldFaultReason "PM ECU: a046 vhld fault reason";
CM_ SG_ 1444 PM_a046_vhldUnavailableReason "PM ECU: a046 vhld unavailable reason";
CM_ SG_ 1444 PM_a046_diBrakeTorqueCommand "PM ECU: a046 di brake torque command";
CM_ SG_ 1444 PM_a046_diBrakeCommandType "PM ECU: a046 di brake command type";
CM_ SG_ 1444 PM_a047_pmAutoparkState "PM ECU: a047 pm autopark state; raw 15 = signal not available (SNA)";
CM_ SG_ 1444 PM_a047_diAutoparkState "PM ECU: a047 di autopark state; raw 15 = signal not available (SNA)";
CM_ SG_ 1444 PM_a047_autoparkCancelReason "PM ECU: a047 autopark cancel reason";
CM_ SG_ 1444 PM_a048_vdcFaultReason "PM ECU: a048 vdc fault reason";
CM_ SG_ 1444 PM_a053_LVPowerState "PM ECU: a053 LV power state";
CM_ SG_ 1444 PM_a053_coolant "PM ECU: a053 coolant";
CM_ SG_ 1444 PM_a053_vcleftSwitchStatus "PM ECU: a053 vcleft switch status";
CM_ SG_ 1444 PM_a053_restraintStatus "PM ECU: a053 restraint status";
CM_ SG_ 1444 PM_a053_sensors "PM ECU: a053 sensors";
CM_ SG_ 1444 PM_a054_uiPowertrainControl "PM ECU: a054 ui powertrain control";
CM_ SG_ 1444 PM_a054_uiChassisControl "PM ECU: a054 ui chassis control";
CM_ SG_ 1444 PM_a054_uiCruiseControl "PM ECU: a054 ui cruise control";
CM_ SG_ 1444 PM_a054_uiTrackModeSettings "PM ECU: a054 ui track mode settings";
CM_ SG_ 1444 PM_a054_uiTPMSRCPSetting "PM ECU: a054 ui TPMSRCP setting";
CM_ SG_ 1444 PM_a058_CMP_HVStatus "PM ECU: a058 CMP HV status";
CM_ SG_ 1444 PM_a058_CMPD_state "PM ECU: a058 CMPD state";
CM_ SG_ 1444 PM_a059_PTC_feedbackStatus "PM ECU: a059 PTC feedback status";
CM_ SG_ 1444 PM_a060_TorqueAccelWindow "PM ECU: a060 torque accel window";
CM_ SG_ 1444 PM_a060_TorqueDecelWindow "PM ECU: a060 torque decel window";
CM_ SG_ 1444 PM_a060_TorqueReversalWindow "PM ECU: a060 torque reversal window";
CM_ SG_ 1444 PM_a061_diIpcVersion "PM ECU: a061 di ipc version";
CM_ SG_ 1444 PM_a061_pmIpcVersion "PM ECU: a061 pm ipc version";
CM_ SG_ 1444 PM_a062_address "PM ECU: a062 address";
CM_ SG_ 1444 PM_a062_errorType "PM ECU: a062 error type";
CM_ SG_ 1444 PM_a062_detectedByRamScrub "PM ECU: a062 detected by ram scrub";
CM_ SG_ 1444 PM_a063_totalSystemTorqueCommand "PM ECU: a063 total system torque command";
CM_ SG_ 1444 PM_a063_totalSystemTorqueMeasure "PM ECU: a063 total system torque measured";
CM_ SG_ 1444 PM_a064_interventionType "PM ECU: a064 intervention type";
CM_ SG_ 1444 PM_a064_torqueCmdState "PM ECU: a064 torque cmd state; raw 0 = signal not available (SNA)";
CM_ SG_ 1444 PM_a064_shortDetectedByDI "PM ECU: a064 short detected by DI";
CM_ SG_ 1444 PM_a064_UI_stoppingMode "PM ECU: a064 UI stopping mode";
CM_ SG_ 1444 PM_a064_diCrsState "PM ECU: a064 di crs state";
CM_ SG_ 1444 PM_a064_pmCrsState "PM ECU: a064 pm crs state";
CM_ SG_ 1444 PM_a066_state4 "PM ECU: a066 state4";
CM_ SG_ 1444 PM_a067_state4 "PM ECU: a067 state4";
CM_ SG_ 1444 PM_a070_unitTorqueActualMonitor "PM ECU: a070 unit torque actual monitor";
CM_ SG_ 1444 PM_a070_unitTorqueCommandedMonit "PM ECU: a070 unit torque commanded monitor";
CM_ SG_ 1444 PM_a070_diTorqueCommandedMonitor "PM ECU: a070 di torque commanded monitor";
CM_ SG_ 1444 PM_a070_rearAxleMotorTorqueLimit "PM ECU: a070 rear axle motor torque limit exceeded";
CM_ SG_ 1444 PM_a070_areAllInputsValid "PM ECU: a070 are all inputs valid";
CM_ SG_ 1444 PM_a070_isBrakeBlendingAvailable "PM ECU: a070 is brake blending available";
CM_ SG_ 1444 PM_a070_faultReason "PM ECU: a070 fault reason";
CM_ SG_ 1444 PM_a079_VEH_RCU_actuation "PM ECU: a079 VEH RCU actuation";
CM_ SG_ 1444 PM_a079_PARTY_RCU_actuation "PM ECU: a079 PARTY RCU actuation";
CM_ SG_ 1444 PM_a082_faultAddress "PM ECU: a082 fault address";
CM_ SG_ 1444 PM_a082_isWriteNotRead "PM ECU: a082 is write not read";
CM_ SG_ 1444 PM_a084_faultAddress "PM ECU: a084 fault address";
CM_ SG_ 1444 PM_a084_firewallId "PM ECU: a084 firewall id";
CM_ SG_ 1444 PM_a084_privId "PM ECU: a084 priv id";
CM_ SG_ 1444 PM_a084_ns "PM ECU: a084 ns";
CM_ SG_ 1444 PM_a084_faultType "PM ECU: a084 fault type";
CM_ SG_ 1444 PM_a085_DPB_actuator3 "PM ECU: a085 DPB actuator3";
CM_ SG_ 1444 PM_a087_mailboxID "PM ECU: a087 mailbox ID";
CM_ SG_ 1444 PM_a087_canID "PM ECU: a087 can ID";
CM_ SG_ 1444 PM_a087_errorType "PM ECU: a087 error type";
CM_ SG_ 1444 PM_a092_pllClockSource "PM ECU: a092 pll clock source";
CM_ SG_ 1444 PM_a100_index1kHzPeriodic "PM ECU: a100 index1k hz periodic";
CM_ SG_ 1444 PM_a100_index100HzPeriodic "PM ECU: a100 index100 hz periodic";
CM_ SG_ 1444 PM_a100_index10HzPeriodic "PM ECU: a100 index10 hz periodic";
CM_ SG_ 1444 PM_a100_indexSWI "PM ECU: a100 index SWI";
CM_ SG_ 1444 PM_a100_eepEvent "PM ECU: a100 eep event";
CM_ SG_ 1444 PM_a100_module500HzActive "PM ECU: a100 module500 hz active";
CM_ SG_ 1444 PM_a100_module50HzActive "PM ECU: a100 module50 hz active";
CM_ SG_ 1444 PM_a100_module1HzActive "PM ECU: a100 module1 hz active";
CM_ SG_ 1444 PM_a100_task10HzActive "PM ECU: a100 task10 hz active";
CM_ SG_ 1444 PM_a100_taskUdsActive "PM ECU: a100 task uds active";
CM_ SG_ 1444 PM_a110_itpmsWarningFrL "PM ECU: a110 itpms warning fr l";
CM_ SG_ 1444 PM_a110_itpmsWarningFrR "PM ECU: a110 itpms warning fr r";
CM_ SG_ 1444 PM_a110_itpmsWarningReL "PM ECU: a110 itpms warning re l";
CM_ SG_ 1444 PM_a110_itpmsWarningReR "PM ECU: a110 itpms warning re r";
CM_ SG_ 1444 PM_a111_prevGearUnit0 "PM ECU: a111 prev gear unit0; raw 7 = signal not available (SNA)";
CM_ SG_ 1444 PM_a111_prevGearUnit1 "PM ECU: a111 prev gear unit1; raw 7 = signal not available (SNA)";
CM_ SG_ 1444 PM_a111_prevGearUnit2 "PM ECU: a111 prev gear unit2; raw 7 = signal not available (SNA)";
CM_ SG_ 1444 PM_a111_vehicleSpeed "PM ECU: a111 vehicle speed";
CM_ SG_ 1444 PM_a111_recoveryTargetGear "PM ECU: a111 recovery target gear; raw 7 = signal not available (SNA)";
CM_ SG_ 1444 PM_a111_unitsConsensus "PM ECU: a111 units consensus";
CM_ SG_ 1444 PM_a111_speedPolarityMatch "PM ECU: a111 speed polarity match";
CM_ SG_ 1444 PM_a111_failureReason "PM ECU: a111 failure reason";
CM_ SG_ 1444 PM_a112_itpmsWarningFrL "PM ECU: a112 itpms warning fr l";
CM_ SG_ 1444 PM_a112_itpmsWarningFrR "PM ECU: a112 itpms warning fr r";
CM_ SG_ 1444 PM_a112_itpmsWarningReL "PM ECU: a112 itpms warning re l";
CM_ SG_ 1444 PM_a112_itpmsWarningReR "PM ECU: a112 itpms warning re r";
CM_ SG_ 1444 PM_a120_diMIA "PM ECU: a120 di MIA";
CM_ SG_ 1444 PM_a120_diUnitsMIA "PM ECU: a120 di units MIA";
CM_ SG_ 1444 PM_a120_rcmMIA "PM ECU: a120 rcm MIA";
CM_ SG_ 1444 PM_a120_wssMIA "PM ECU: a120 wss MIA";
CM_ SG_ 1444 PM_a120_gtwMIA "PM ECU: a120 gtw MIA";
CM_ SG_ 1444 PM_a120_vcMIA "PM ECU: a120 vc MIA";
CM_ SG_ 1444 PM_a120_steeringMIA "PM ECU: a120 steering MIA";
CM_ SG_ 1444 PM_a120_gnssEpochMIA "PM ECU: a120 gnss epoch MIA";
CM_ BO_ 900 "PM ECU message: alert matrix";
CM_ SG_ 900 PM_matrixIndex "PM ECU: matrix index";
CM_ SG_ 900 PM_a001_absoluteTorque "PM ECU: a001 absolute torque";
CM_ SG_ 900 PM_a002_excessiveAccelTorque "PM ECU: a002 excessive accel torque";
CM_ SG_ 900 PM_a003_excessiveReversalTorque "PM ECU: a003 excessive reversal torque";
CM_ SG_ 900 PM_a004_excessiveDecelTorque "PM ECU: a004 excessive decel torque";
CM_ SG_ 900 PM_a005_torqueInNeutralOrPark "PM ECU: a005 torque in neutral or park";
CM_ SG_ 900 PM_a006_inconsistentDIGear "PM ECU: a006 inconsistent DI gear";
CM_ SG_ 900 PM_a007_ibstMIA "PM ECU: a007 ibst MIA";
CM_ SG_ 900 PM_a008_memoryError "PM ECU: a008 memory error";
CM_ SG_ 900 PM_a009_espMIA "PM ECU: a009 esp MIA";
CM_ SG_ 900 PM_a010_diMIA "PM ECU: a010 di MIA";
CM_ SG_ 900 PM_a011_systemHvilNotClosed "PM ECU: a011 system hvil not closed";
CM_ SG_ 900 PM_a012_canDataBusA "PM ECU: a012 can data bus a";
CM_ SG_ 900 PM_a013_canHardwareBusA "PM ECU: a013 can hardware bus a";
CM_ SG_ 900 PM_a014_accelPedalError "PM ECU: a014 accel pedal error";
CM_ SG_ 900 PM_a015_shifterMIA "PM ECU: a015 shifter MIA";
CM_ SG_ 900 PM_a016_bbMIA "PM ECU: a016 bb MIA";
CM_ SG_ 900 PM_a017_brakeMIA "PM ECU: a017 brake MIA";
CM_ SG_ 900 PM_a021_difMIA "PM ECU: a021 dif MIA";
CM_ SG_ 900 PM_a022_dirMIA "PM ECU: a022 dir MIA";
CM_ SG_ 900 PM_a023_cruiseInhibit "PM ECU: a023 cruise inhibit";
CM_ SG_ 900 PM_a024_brakeIrrational "PM ECU: a024 brake irrational";
CM_ SG_ 900 PM_a025_unintendedReset "PM ECU: a025 unintended reset";
CM_ SG_ 900 PM_a026_diHeartBeatMIA "PM ECU: a026 di heart beat MIA";
CM_ SG_ 900 PM_a028_torqueCmdError "PM ECU: a028 torque cmd error";
CM_ SG_ 900 PM_a029_cruiseRollback "PM ECU: a029 cruise rollback";
CM_ SG_ 900 PM_a030_inconsistentAebState "PM ECU: a030 inconsistent aeb state";
CM_ SG_ 900 PM_a031_highStackUsage "PM ECU: a031 high stack usage";
CM_ SG_ 900 PM_a032_registerConfigError "PM ECU: a032 register config error";
CM_ SG_ 900 PM_a033_appMIA "PM ECU: a033 app MIA";
CM_ SG_ 900 PM_a034_trqCrossCheck "PM ECU: a034 trq cross check";
CM_ SG_ 900 PM_a035_udsTransactionInitiated "PM ECU: a035 uds transaction initiated";
CM_ SG_ 900 PM_a036_preWatchdog "PM ECU: a036 pre watchdog";
CM_ SG_ 900 PM_a038_inconsistentTorqueSign "PM ECU: a038 inconsistent torque sign";
CM_ SG_ 900 PM_a039_disMIA "PM ECU: a039 dis MIA";
CM_ SG_ 900 PM_a040_alignmentDriftDetected "PM ECU: a040 alignment drift detected";
CM_ SG_ 900 PM_a041_dasMIA "PM ECU: a041 das MIA";
CM_ SG_ 900 PM_a042_gtwMIA "PM ECU: a042 gtw MIA";
CM_ SG_ 900 PM_a043_inconsistentConfig "PM ECU: a043 inconsistent config";
CM_ SG_ 900 PM_a044_ebrIntervention "PM ECU: a044 ebr intervention";
CM_ SG_ 900 PM_a045_regenBackfillInterventio "PM ECU: a045 regen backfill intervention";
CM_ SG_ 900 PM_a046_inconsVehicleHoldState "PM ECU: a046 incons vehicle hold state";
CM_ SG_ 900 PM_a047_inconsAutoparkState "PM ECU: a047 incons autopark state";
CM_ SG_ 900 PM_a048_stabilityControlInhibit "PM ECU: a048 stability control inhibit";
CM_ SG_ 900 PM_a049_stbCtrlInWrongDir "PM ECU: a049 stb ctrl in wrong dir";
CM_ SG_ 900 PM_a050_excessiveStbCtrlTrq "PM ECU: a050 excessive stb ctrl trq";
CM_ SG_ 900 PM_a051_unintDecelStbCtrl "PM ECU: a051 unint decel stb ctrl";
CM_ SG_ 900 PM_a052_stbCtrlDrvrDecelCflct "PM ECU: a052 stb ctrl drvr decel cflct";
CM_ SG_ 900 PM_a053_vcfrontMIA "PM ECU: a053 vcfront MIA";
CM_ SG_ 900 PM_a054_uiMIA "PM ECU: a054 ui MIA";
CM_ SG_ 900 PM_a055_accelPedalSyncWarn "PM ECU: a055 accel pedal sync warn";
CM_ SG_ 900 PM_a056_canHardwareBusB "PM ECU: a056 can hardware bus b";
CM_ SG_ 900 PM_a057_canDataBusB "PM ECU: a057 can data bus b";
CM_ SG_ 900 PM_a058_cmpMIA "PM ECU: a058 cmp MIA";
CM_ SG_ 900 PM_a059_ptcMIA "PM ECU: a059 ptc MIA";
CM_ SG_ 900 PM_a060_onePedalDrivingInhibit "PM ECU: a060 one pedal driving inhibit";
CM_ SG_ 900 PM_a061_DIPMVersionMismatch "PM ECU: a061 DIPM version mismatch";
CM_ SG_ 900 PM_a062_eccError "PM ECU: a062 ecc error";
CM_ SG_ 900 PM_a063_torqueCommandInhibit "PM ECU: a063 torque command inhibit";
CM_ SG_ 900 PM_a064_torqueIntervention "PM ECU: a064 torque intervention";
CM_ SG_ 900 PM_a066_pmfMIA "PM ECU: a066 pmf MIA";
CM_ SG_ 900 PM_a067_pmrMIA "PM ECU: a067 pmr MIA";
CM_ SG_ 900 PM_a068_brakePedalMonitor "PM ECU: a068 brake pedal monitor";
CM_ SG_ 900 PM_a069_brakeMonitorsUnhealthy "PM ECU: a069 brake monitors unhealthy";
CM_ SG_ 900 PM_a070_brakeTorqueSplitMonitorT "PM ECU: a070 brake torque split monitor trip";
CM_ SG_ 900 PM_a071_baseBrakingMonitor "PM ECU: a071 base braking monitor";
CM_ SG_ 900 PM_a072_brakeTorqueCommandInterf "PM ECU: a072 brake torque command interface";
CM_ SG_ 900 PM_a073_canDataBusC "PM ECU: a073 can data bus c";
CM_ SG_ 900 PM_a074_canHardwareBusC "PM ECU: a074 can hardware bus c";
CM_ SG_ 900 PM_a075_canDataBusD "PM ECU: a075 can data bus d";
CM_ SG_ 900 PM_a076_canHardwareBusD "PM ECU: a076 can hardware bus d";
CM_ SG_ 900 PM_a077_canDataBusE "PM ECU: a077 can data bus e";
CM_ SG_ 900 PM_a078_canHardwareBusE "PM ECU: a078 can hardware bus e";
CM_ SG_ 900 PM_a079_rcuMIA "PM ECU: a079 rcu MIA";
CM_ SG_ 900 PM_a080_exceptionPrefetchAbort "PM ECU: a080 exception prefetch abort";
CM_ SG_ 900 PM_a081_exceptionDataAbort "PM ECU: a081 exception data abort";
CM_ SG_ 900 PM_a082_exceptionDataAbort2 "PM ECU: a082 exception data abort2";
CM_ SG_ 900 PM_a083_ahbWriteError "PM ECU: a083 ahb write error";
CM_ SG_ 900 PM_a084_exceptionMpuFirewall "PM ECU: a084 exception mpu firewall";
CM_ SG_ 900 PM_a085_dpbMIA "PM ECU: a085 dpb MIA";
CM_ SG_ 900 PM_a086_exceptionUndefinedInstru "PM ECU: a086 exception undefined instruction";
CM_ SG_ 900 PM_a087_canHardwareBusLIPC "PM ECU: a087 can hardware bus LIPC";
CM_ SG_ 900 PM_a088_absMonitor "PM ECU: a088 abs monitor";
CM_ SG_ 900 PM_a092_xtalOscillator "PM ECU: a092 xtal oscillator";
CM_ SG_ 900 PM_a093_accelPedalSupply "PM ECU: a093 accel pedal supply";
CM_ SG_ 900 PM_a094_torqueSplitMonitor "PM ECU: a094 torque split monitor";
CM_ SG_ 900 PM_a095_ITPMSTimeoutGNSSConverge "PM ECU: a095 ITPMS timeout GNSS convergence";
CM_ SG_ 900 PM_a096_ITPMSConvergedGNSSAbsRad "PM ECU: a096 ITPMS converged GNSS abs radius times";
CM_ SG_ 900 PM_a097_ITPMSRelativeCalibratedF "PM ECU: a097 ITPMS relative calibrated factors";
CM_ SG_ 900 PM_a098_ITPMSTriggerDebug "PM ECU: a098 ITPMS trigger debug";
CM_ SG_ 900 PM_a099_ITPMSCalibrated "PM ECU: a099 ITPMS calibrated";
CM_ SG_ 900 PM_a100_diTraceInfo1 "PM ECU: a100 di trace info1";
CM_ SG_ 900 PM_a110_indirectTPMSPressureLoss "PM ECU: a110 indirect TPMS pressure loss warning";
CM_ SG_ 900 PM_a111_unintendedResetCausedNeu "PM ECU: a111 unintended reset caused neutral";
CM_ SG_ 900 PM_a112_indirectTPMSPressureLoss "PM ECU: a112 indirect TPMS pressure loss warning hard";
CM_ SG_ 900 PM_a113_btcMonitor "PM ECU: a113 btc monitor";
CM_ SG_ 900 PM_a114_ramScrubTimedOut "PM ECU: a114 ram scrub timed out";
CM_ SG_ 900 PM_a115_indirectTPMSFaultedGhost "PM ECU: a115 indirect TPMS faulted ghosted";
CM_ SG_ 900 PM_a116_ITPMSBlowoutCalProgress "PM ECU: a116 ITPMS blowout cal progress";
CM_ SG_ 900 PM_a117_ITPMSPermeabilityCalibra "PM ECU: a117 ITPMS permeability calibrated";
CM_ SG_ 900 PM_a118_vehicleSpeedQFDiagnostic "PM ECU: a118 vehicle speed QF diagnostic";
CM_ SG_ 900 PM_a120_indirectTPMSFaulted "PM ECU: a120 indirect TPMS faulted";
CM_ SG_ 900 PM_a121_unintendedReset2 "PM ECU: a121 unintended reset2";
CM_ SG_ 900 PM_a125_btcOutputIrrational "PM ECU: a125 btc output irrational";
CM_ BO_ 2022 "PM ECU message: info";
CM_ SG_ 2022 PM_infoIndex "PM ECU: info index";
CM_ SG_ 2022 PM_buildType "PM ECU: build type";
CM_ SG_ 2022 PM_buildConfigurationId "PM ECU: build configuration id";
CM_ SG_ 2022 PM_hardwareId "PM ECU: hardware id";
CM_ SG_ 2022 PM_deviceFused "PM ECU: device fused";
CM_ SG_ 2022 PM_componentId "PM ECU: component id";
CM_ SG_ 2022 PM_pcbaId "PM ECU: pcba id";
CM_ SG_ 2022 PM_assemblyId "PM ECU: assembly id";
CM_ SG_ 2022 PM_usageId "PM ECU: usage id";
CM_ SG_ 2022 PM_subUsageId "PM ECU: sub usage id";
CM_ SG_ 2022 PM_applicationCrc "PM ECU: application crc";
CM_ SG_ 2022 PM_bootGitHash "PM ECU: boot git hash";
CM_ BO_ 1973 "PM ECU message: itpms display";
CM_ SG_ 1973 PM_itpmsDisplaySelector "PM ECU: itpms display selector";
CM_ SG_ 1973 PM_indirectTPMSTellTale "Indirect TPMS UI telltale status to indicate system availability";
CM_ SG_ 1973 PM_indirectTPMSDisplayState "Indirect TPMS UI calibration state";
CM_ SG_ 1973 PM_indirectTPMSDisplayProgress "PM ECU: indirect TPMS display progress";
CM_ SG_ 1973 PM_indirectTPMSDisplayWarningInd "Pressure loss warning indicator per wheel determined by indirect TPMS";
CM_ SG_ 1973 PM_indirectTPMSDisplayWarni_0001 "Pressure loss warning indicator per wheel determined by indirect TPMS";
CM_ SG_ 1973 PM_indirectTPMSDisplayWarni_0002 "Pressure loss warning indicator per wheel determined by indirect TPMS";
CM_ SG_ 1973 PM_indirectTPMSDisplayWarni_0003 "Pressure loss warning indicator per wheel determined by indirect TPMS";
CM_ SG_ 1973 PM_indirectTPMSRecommendedColdPr "Reports the recommended cold pressure for the front or rear tires as provided by the Indirect Tire Pressure Monitoring System (ITPMS); raw 255 = signal not available (SNA)";
CM_ SG_ 1973 PM_indirectTPMSRecommendedC_0001 "Reports the recommended cold pressure for the front or rear tires as provided by the Indirect Tire Pressure Monitoring System (ITPMS); raw 255 = signal not available (SNA)";
CM_ SG_ 1973 PM_fusedPressureEstimateFrL "Reports the estimated tire pressure at each wheel based on Indirect Tire Pressure Monitoring System (ITPMS) relative wheel speed and Global Navigation Satellite System (GNSS) absolute radius data.";
CM_ SG_ 1973 PM_fusedPressureEstimateFrR "Reports the estimated tire pressure at each wheel based on Indirect Tire Pressure Monitoring System (ITPMS) relative wheel speed and Global Navigation Satellite System (GNSS) absolute radius data.";
CM_ SG_ 1973 PM_fusedPressureEstimateReL "Reports the estimated tire pressure at each wheel based on Indirect Tire Pressure Monitoring System (ITPMS) relative wheel speed and Global Navigation Satellite System (GNSS) absolute radius data.";
CM_ SG_ 1973 PM_fusedPressureEstimateReR "Reports the estimated tire pressure at each wheel based on Indirect Tire Pressure Monitoring System (ITPMS) relative wheel speed and Global Navigation Satellite System (GNSS) absolute radius data.";
CM_ BO_ 485 "PM ECU message: loc state";
CM_ SG_ 485 PM_cruiseFaultRequest "PM ECU: cruise fault request";
CM_ SG_ 485 PM_shiftState "PM ECU: shift state; raw 7 = signal not available (SNA)";
CM_ SG_ 485 PM_cruiseState "PM ECU: cruise state";
CM_ SG_ 485 PM_vehicleHoldRequest "PM ECU: vehicle hold request";
CM_ SG_ 485 PM_aebRequest "PM ECU: aeb request";
CM_ SG_ 485 PM_torqueCmdState "PM ECU: torque cmd state; raw 0 = signal not available (SNA)";
CM_ SG_ 485 PM_btcCmdState "PM ECU: btc cmd state";
CM_ SG_ 485 PM_unparkAllowed "PM ECU: unpark allowed";
CM_ SG_ 485 PM_stationaryMode "PM ECU: stationary mode";
CM_ SG_ 485 PM_onePedalFaultRequest "PM ECU: one pedal fault request";
CM_ SG_ 485 PM_backfillDisableRequest "PM ECU: backfill disable request";
CM_ SG_ 485 PM_autoparkState "PM ECU: autopark state; raw 15 = signal not available (SNA)";
CM_ SG_ 485 PM_regenBlendCmdQF "PM ECU: regen blend cmd QF";
CM_ SG_ 485 PM_brakePedalCmdQF "PM ECU: brake pedal cmd QF";
CM_ SG_ 485 PM_latentFaultCheckIntResponse "PM ECU: latent fault check int response";
CM_ SG_ 485 PM_hvilSystemStatus "HVIL system status; raw 3 = signal not available (SNA)";
CM_ SG_ 485 PM_locStateCounter "PM ECU: loc state counter";
CM_ SG_ 485 PM_locStateChecksum "PM ECU: loc state checksum";
BA_DEF_ BO_ "GenMsgCycleTime" INT 0 3600000;
BA_DEF_ BO_ "GenMsgSendType" ENUM "Cyclic","NotUsed","NotUsed","NotUsed","NotUsed","NotUsed","NotUsed","IfActive","NoMsgSendType","NotUsed";
BA_DEF_ BO_ "VFrameFormat" ENUM "StandardCAN","ExtendedCAN","reserved","J1939PG","reserved","reserved","reserved","reserved","reserved","reserved","reserved","reserved","reserved","reserved","StandardCAN_FD","ExtendedCAN_FD";
BA_DEF_ BO_ "CANFD_BRS" ENUM "0","1";
BA_DEF_ SG_ "GenSigSNA" STRING;
BA_DEF_ SG_ "SystemSignalLongSymbol" STRING;
BA_DEF_ SG_ "Confidence" ENUM "validated","plausible","layout-only","contradicted";
BA_DEF_DEF_ "GenMsgCycleTime" 0;
BA_DEF_DEF_ "GenMsgSendType" "NoMsgSendType";
BA_DEF_DEF_ "VFrameFormat" "StandardCAN";
BA_DEF_DEF_ "CANFD_BRS" "1";
BA_DEF_DEF_ "GenSigSNA" "";
BA_DEF_DEF_ "SystemSignalLongSymbol" "";
BA_DEF_DEF_ "Confidence" "layout-only";
BA_ "GenMsgCycleTime" BO_ 772 1000;
BA_ "GenMsgSendType" BO_ 772 0;
BA_ "GenMsgCycleTime" BO_ 790 1000;
BA_ "GenMsgSendType" BO_ 790 0;
BA_ "GenMsgCycleTime" BO_ 1316 1000;
BA_ "GenMsgSendType" BO_ 1316 0;
BA_ "GenMsgCycleTime" BO_ 902 1000;
BA_ "GenMsgSendType" BO_ 902 0;
BA_ "GenMsgCycleTime" BO_ 1748 1000;
BA_ "GenMsgSendType" BO_ 1748 0;
BA_ "GenMsgCycleTime" BO_ 2023 1000;
BA_ "GenMsgSendType" BO_ 2023 0;
BA_ "GenMsgCycleTime" BO_ 900 1000;
BA_ "GenMsgSendType" BO_ 900 0;
BA_ "GenMsgCycleTime" BO_ 2022 1000;
BA_ "GenMsgSendType" BO_ 2022 0;
BA_ "GenMsgCycleTime" BO_ 1973 1000;
BA_ "GenMsgSendType" BO_ 1973 0;
BA_ "GenMsgCycleTime" BO_ 485 10;
BA_ "GenMsgSendType" BO_ 485 0;
BA_ "Confidence" SG_ 1317 PMF_alertID 1;
BA_ "Confidence" SG_ 1317 PMF_alertState 1;
BA_ "Confidence" SG_ 1317 PMF_a002_torqueMeasured 1;
BA_ "GenSigSNA" SG_ 1317 PMF_a002_torqueMeasured "4096";
BA_ "Confidence" SG_ 1317 PMF_a002_torqueAccelAverage 1;
BA_ "GenSigSNA" SG_ 1317 PMF_a002_torqueAccelAverage "4096";
BA_ "Confidence" SG_ 1317 PMF_a002_torqueAccelWindow 1;
BA_ "GenSigSNA" SG_ 1317 PMF_a002_torqueAccelWindow "4096";
BA_ "Confidence" SG_ 1317 PMF_a003_pedalPos 1;
BA_ "Confidence" SG_ 1317 PMF_a003_zeroPointPedal 1;
BA_ "Confidence" SG_ 1317 PMF_a004_torqueMeasured 1;
BA_ "GenSigSNA" SG_ 1317 PMF_a004_torqueMeasured "4096";
BA_ "Confidence" SG_ 1317 PMF_a004_torqueDecelAverage 1;
BA_ "GenSigSNA" SG_ 1317 PMF_a004_torqueDecelAverage "4096";
BA_ "Confidence" SG_ 1317 PMF_a004_torqueDecelWindow 1;
BA_ "GenSigSNA" SG_ 1317 PMF_a004_torqueDecelWindow "4096";
BA_ "Confidence" SG_ 1317 PMF_a005_torqueReason 1;
BA_ "Confidence" SG_ 1317 PMF_a005_torqueMeasured 1;
BA_ "GenSigSNA" SG_ 1317 PMF_a005_torqueMeasured "4096";
BA_ "Confidence" SG_ 1317 PMF_a005_iDQmagnitude 1;
BA_ "Confidence" SG_ 1317 PMF_a006_torqueActual 1;
BA_ "GenSigSNA" SG_ 1317 PMF_a006_torqueActual "4096";
BA_ "Confidence" SG_ 1317 PMF_a006_motorRPM 1;
BA_ "Confidence" SG_ 1317 PMF_a006_torqueMeasured 1;
BA_ "GenSigSNA" SG_ 1317 PMF_a006_torqueMeasured "4096";
BA_ "Confidence" SG_ 1317 PMF_a011_Ia 1;
BA_ "Confidence" SG_ 1317 PMF_a011_IaDelta 1;
BA_ "Confidence" SG_ 1317 PMF_a011_Ib 1;
BA_ "Confidence" SG_ 1317 PMF_a011_IbDelta 1;
BA_ "Confidence" SG_ 1317 PMF_a011_currentVref 1;
BA_ "SystemSignalLongSymbol" SG_ 1317 PMF_a011_currentReadingIrrationa "PMF_a011_currentReadingIrrational";
BA_ "Confidence" SG_ 1317 PMF_a019_statorTemp1 1;
BA_ "Confidence" SG_ 1317 PMF_a019_statorTslope1 1;
BA_ "SystemSignalLongSymbol" SG_ 1317 PMF_a025_hwSecModuleWatchdogTime "PMF_a025_hwSecModuleWatchdogTimer";
BA_ "Confidence" SG_ 1317 PMF_a026_reason 1;
BA_ "Confidence" SG_ 1317 PMF_a033_state 1;
BA_ "Confidence" SG_ 1317 PMF_a033_failReason 1;
BA_ "Confidence" SG_ 1317 PMF_a033_DSADC_Ia 1;
BA_ "Confidence" SG_ 1317 PMF_a033_DSADC_Ib 1;
BA_ "Confidence" SG_ 1317 PMF_a036_timeSinceTxHWI 1;
BA_ "Confidence" SG_ 1317 PMF_a036_timeSinceRxHWI 1;
BA_ "Confidence" SG_ 1317 PMF_a036_timeSince100HzTxSWI 1;
BA_ "Confidence" SG_ 1317 PMF_a036_timeSince1kHzCLK 1;
BA_ "Confidence" SG_ 1317 PMF_a036_timeSince1kHzSWI 1;
BA_ "Confidence" SG_ 1317 PMF_a036_timeSinceIdle 1;
BA_ "Confidence" SG_ 1317 PMF_a036_ovfStackId 1;
BA_ "GenSigSNA" SG_ 1317 PMF_a036_ovfStackId "15";
BA_ "Confidence" SG_ 1317 PMF_a042_GTW_drivetrainType 1;
BA_ "Confidence" SG_ 1317 PMF_a042_expectedPerformanceCfg 1;
BA_ "Confidence" SG_ 1317 PMF_a055_motorRPM 1;
BA_ "Confidence" SG_ 1317 PMF_a055_phaseAngle 1;
BA_ "Confidence" SG_ 1317 PMF_a055_commonGain 1;
BA_ "Confidence" SG_ 1317 PMF_a058_hvilCurrent 1;
BA_ "Confidence" SG_ 1317 PMF_a062_errorType 1;
BA_ "Confidence" SG_ 1317 PMF_a064_interventionType 1;
BA_ "Confidence" SG_ 1317 PMF_a064_torqueCmdState 1;
BA_ "GenSigSNA" SG_ 1317 PMF_a064_torqueCmdState "0";
BA_ "Confidence" SG_ 1317 PMF_a064_UI_stoppingMode 1;
BA_ "Confidence" SG_ 1317 PMF_a064_diCrsState 1;
BA_ "Confidence" SG_ 1317 PMF_a064_pmCrsState 1;
BA_ "Confidence" SG_ 1317 PMF_a084_firewallId 1;
BA_ "Confidence" SG_ 1317 PMF_a084_privId 1;
BA_ "Confidence" SG_ 1317 PMF_a084_faultType 1;
BA_ "Confidence" SG_ 1317 PMF_a092_pllClockSource 1;
BA_ "Confidence" SG_ 1317 PMF_a095_safetyICstate 1;
BA_ "Confidence" SG_ 1317 PMF_a095_motorRPM 1;
BA_ "Confidence" SG_ 772 PMF_matrixIndex 1;
BA_ "SystemSignalLongSymbol" SG_ 772 PMF_a027_torqueEstimationOutOfBo "PMF_a027_torqueEstimationOutOfBounds";
BA_ "SystemSignalLongSymbol" SG_ 772 PMF_a058_measuredHvilCurrentFroz "PMF_a058_measuredHvilCurrentFrozen";
BA_ "SystemSignalLongSymbol" SG_ 772 PMF_a086_exceptionUndefinedInstr "PMF_a086_exceptionUndefinedInstruction";
BA_ "Confidence" SG_ 790 PMF_infoIndex 1;
BA_ "Confidence" SG_ 790 PMF_buildType 0;
BA_ "Confidence" SG_ 790 PMF_buildConfigurationId 0;
BA_ "Confidence" SG_ 790 PMF_hardwareId 0;
BA_ "Confidence" SG_ 790 PMF_deviceFused 0;
BA_ "Confidence" SG_ 790 PMF_componentId 0;
BA_ "Confidence" SG_ 790 PMF_pcbaId 0;
BA_ "Confidence" SG_ 790 PMF_assemblyId 0;
BA_ "Confidence" SG_ 790 PMF_usageId 0;
BA_ "Confidence" SG_ 790 PMF_subUsageId 0;
BA_ "Confidence" SG_ 790 PMF_applicationCrc 0;
BA_ "Confidence" SG_ 790 PMF_appGitHash 0;
BA_ "Confidence" SG_ 790 PMF_bootGitHash 0;
BA_ "Confidence" SG_ 790 PMF_platformTyp 0;
BA_ "Confidence" SG_ 790 PMF_udsProtocolVersion 0;
BA_ "Confidence" SG_ 790 PMF_bootloaderCrc 0;
BA_ "Confidence" SG_ 1316 PMF_processorDieIdLot 0;
BA_ "Confidence" SG_ 1316 PMF_processorDieIdWafer 0;
BA_ "Confidence" SG_ 1316 PMF_processorDieIdX 0;
BA_ "Confidence" SG_ 1316 PMF_processorDieIdY 0;
BA_ "Confidence" SG_ 1620 PMF_udsResponseData 1;
BA_ "Confidence" SG_ 1446 PMR_alertID 1;
BA_ "Confidence" SG_ 1446 PMR_alertState 1;
BA_ "Confidence" SG_ 1446 PMR_a002_torqueMeasured 1;
BA_ "GenSigSNA" SG_ 1446 PMR_a002_torqueMeasured "4096";
BA_ "Confidence" SG_ 1446 PMR_a002_torqueAccelAverage 1;
BA_ "GenSigSNA" SG_ 1446 PMR_a002_torqueAccelAverage "4096";
BA_ "Confidence" SG_ 1446 PMR_a002_torqueAccelWindow 1;
BA_ "GenSigSNA" SG_ 1446 PMR_a002_torqueAccelWindow "4096";
BA_ "Confidence" SG_ 1446 PMR_a003_pedalPos 1;
BA_ "Confidence" SG_ 1446 PMR_a003_zeroPointPedal 1;
BA_ "Confidence" SG_ 1446 PMR_a004_torqueMeasured 1;
BA_ "GenSigSNA" SG_ 1446 PMR_a004_torqueMeasured "4096";
BA_ "Confidence" SG_ 1446 PMR_a004_torqueDecelAverage 1;
BA_ "GenSigSNA" SG_ 1446 PMR_a004_torqueDecelAverage "4096";
BA_ "Confidence" SG_ 1446 PMR_a004_torqueDecelWindow 1;
BA_ "GenSigSNA" SG_ 1446 PMR_a004_torqueDecelWindow "4096";
BA_ "Confidence" SG_ 1446 PMR_a005_torqueReason 1;
BA_ "Confidence" SG_ 1446 PMR_a005_torqueMeasured 1;
BA_ "GenSigSNA" SG_ 1446 PMR_a005_torqueMeasured "4096";
BA_ "Confidence" SG_ 1446 PMR_a005_iDQmagnitude 1;
BA_ "Confidence" SG_ 1446 PMR_a006_torqueActual 1;
BA_ "GenSigSNA" SG_ 1446 PMR_a006_torqueActual "4096";
BA_ "Confidence" SG_ 1446 PMR_a006_motorRPM 1;
BA_ "Confidence" SG_ 1446 PMR_a006_torqueMeasured 1;
BA_ "GenSigSNA" SG_ 1446 PMR_a006_torqueMeasured "4096";
BA_ "Confidence" SG_ 1446 PMR_a011_Ia 1;
BA_ "Confidence" SG_ 1446 PMR_a011_IaDelta 1;
BA_ "Confidence" SG_ 1446 PMR_a011_Ib 1;
BA_ "Confidence" SG_ 1446 PMR_a011_IbDelta 1;
BA_ "Confidence" SG_ 1446 PMR_a011_currentVref 1;
BA_ "SystemSignalLongSymbol" SG_ 1446 PMR_a011_currentReadingIrrationa "PMR_a011_currentReadingIrrational";
BA_ "Confidence" SG_ 1446 PMR_a019_statorTemp1 1;
BA_ "Confidence" SG_ 1446 PMR_a019_statorTslope1 1;
BA_ "SystemSignalLongSymbol" SG_ 1446 PMR_a025_hwSecModuleWatchdogTime "PMR_a025_hwSecModuleWatchdogTimer";
BA_ "Confidence" SG_ 1446 PMR_a026_reason 1;
BA_ "Confidence" SG_ 1446 PMR_a033_state 1;
BA_ "Confidence" SG_ 1446 PMR_a033_failReason 1;
BA_ "Confidence" SG_ 1446 PMR_a033_DSADC_Ia 1;
BA_ "Confidence" SG_ 1446 PMR_a033_DSADC_Ib 1;
BA_ "Confidence" SG_ 1446 PMR_a036_timeSinceTxHWI 1;
BA_ "Confidence" SG_ 1446 PMR_a036_timeSinceRxHWI 1;
BA_ "Confidence" SG_ 1446 PMR_a036_timeSince100HzTxSWI 1;
BA_ "Confidence" SG_ 1446 PMR_a036_timeSince1kHzCLK 1;
BA_ "Confidence" SG_ 1446 PMR_a036_timeSince1kHzSWI 1;
BA_ "Confidence" SG_ 1446 PMR_a036_timeSinceIdle 1;
BA_ "Confidence" SG_ 1446 PMR_a036_ovfStackId 1;
BA_ "GenSigSNA" SG_ 1446 PMR_a036_ovfStackId "15";
BA_ "Confidence" SG_ 1446 PMR_a042_GTW_drivetrainType 1;
BA_ "Confidence" SG_ 1446 PMR_a042_expectedPerformanceCfg 1;
BA_ "Confidence" SG_ 1446 PMR_a055_motorRPM 1;
BA_ "Confidence" SG_ 1446 PMR_a055_phaseAngle 1;
BA_ "Confidence" SG_ 1446 PMR_a055_commonGain 1;
BA_ "Confidence" SG_ 1446 PMR_a058_hvilCurrent 1;
BA_ "Confidence" SG_ 1446 PMR_a062_errorType 1;
BA_ "Confidence" SG_ 1446 PMR_a064_interventionType 1;
BA_ "Confidence" SG_ 1446 PMR_a064_torqueCmdState 1;
BA_ "GenSigSNA" SG_ 1446 PMR_a064_torqueCmdState "0";
BA_ "Confidence" SG_ 1446 PMR_a064_UI_stoppingMode 1;
BA_ "Confidence" SG_ 1446 PMR_a064_diCrsState 1;
BA_ "Confidence" SG_ 1446 PMR_a064_pmCrsState 1;
BA_ "Confidence" SG_ 1446 PMR_a084_firewallId 1;
BA_ "Confidence" SG_ 1446 PMR_a084_privId 1;
BA_ "Confidence" SG_ 1446 PMR_a084_faultType 1;
BA_ "Confidence" SG_ 1446 PMR_a092_pllClockSource 1;
BA_ "Confidence" SG_ 1446 PMR_a095_safetyICstate 1;
BA_ "Confidence" SG_ 1446 PMR_a095_motorRPM 1;
BA_ "Confidence" SG_ 902 PMR_matrixIndex 1;
BA_ "SystemSignalLongSymbol" SG_ 902 PMR_a027_torqueEstimationOutOfBo "PMR_a027_torqueEstimationOutOfBounds";
BA_ "SystemSignalLongSymbol" SG_ 902 PMR_a058_measuredHvilCurrentFroz "PMR_a058_measuredHvilCurrentFrozen";
BA_ "SystemSignalLongSymbol" SG_ 902 PMR_a086_exceptionUndefinedInstr "PMR_a086_exceptionUndefinedInstruction";
BA_ "Confidence" SG_ 1748 PMR_infoIndex 1;
BA_ "Confidence" SG_ 1748 PMR_buildType 0;
BA_ "Confidence" SG_ 1748 PMR_buildConfigurationId 0;
BA_ "Confidence" SG_ 1748 PMR_hardwareId 0;
BA_ "Confidence" SG_ 1748 PMR_deviceFused 0;
BA_ "Confidence" SG_ 1748 PMR_componentId 0;
BA_ "Confidence" SG_ 1748 PMR_pcbaId 0;
BA_ "Confidence" SG_ 1748 PMR_assemblyId 0;
BA_ "Confidence" SG_ 1748 PMR_usageId 0;
BA_ "Confidence" SG_ 1748 PMR_subUsageId 0;
BA_ "Confidence" SG_ 1748 PMR_applicationCrc 0;
BA_ "Confidence" SG_ 1748 PMR_appGitHash 0;
BA_ "Confidence" SG_ 1748 PMR_bootGitHash 0;
BA_ "Confidence" SG_ 1748 PMR_platformTyp 0;
BA_ "Confidence" SG_ 1748 PMR_udsProtocolVersion 0;
BA_ "Confidence" SG_ 1748 PMR_bootloaderCrc 0;
BA_ "Confidence" SG_ 2023 PMR_processorDieIdLot 0;
BA_ "Confidence" SG_ 2023 PMR_processorDieIdWafer 0;
BA_ "Confidence" SG_ 2023 PMR_processorDieIdX 0;
BA_ "Confidence" SG_ 2023 PMR_processorDieIdY 0;
BA_ "Confidence" SG_ 1556 PMR_udsResponseData 1;
BA_ "Confidence" SG_ 1444 PM_alertID 1;
BA_ "Confidence" SG_ 1444 PM_alertState 1;
BA_ "Confidence" SG_ 1444 PM_a002_torqueMeasured 1;
BA_ "GenSigSNA" SG_ 1444 PM_a002_torqueMeasured "4096";
BA_ "Confidence" SG_ 1444 PM_a002_torqueAccelAverage 1;
BA_ "GenSigSNA" SG_ 1444 PM_a002_torqueAccelAverage "4096";
BA_ "Confidence" SG_ 1444 PM_a002_torqueAccelWindow 1;
BA_ "GenSigSNA" SG_ 1444 PM_a002_torqueAccelWindow "4096";
BA_ "Confidence" SG_ 1444 PM_a003_torqueMeasured 1;
BA_ "GenSigSNA" SG_ 1444 PM_a003_torqueMeasured "4096";
BA_ "Confidence" SG_ 1444 PM_a003_torqueCommanded 1;
BA_ "GenSigSNA" SG_ 1444 PM_a003_torqueCommanded "4096";
BA_ "Confidence" SG_ 1444 PM_a003_pedalPos 1;
BA_ "Confidence" SG_ 1444 PM_a003_zeroPointPedal 1;
BA_ "Confidence" SG_ 1444 PM_a004_torqueMeasured 1;
BA_ "GenSigSNA" SG_ 1444 PM_a004_torqueMeasured "4096";
BA_ "Confidence" SG_ 1444 PM_a004_torqueDecelAverage 1;
BA_ "GenSigSNA" SG_ 1444 PM_a004_torqueDecelAverage "4096";
BA_ "Confidence" SG_ 1444 PM_a004_torqueDecelWindow 1;
BA_ "GenSigSNA" SG_ 1444 PM_a004_torqueDecelWindow "4096";
BA_ "Confidence" SG_ 1444 PM_a005_torqueReason 1;
BA_ "Confidence" SG_ 1444 PM_a005_torqueMeasured 1;
BA_ "GenSigSNA" SG_ 1444 PM_a005_torqueMeasured "4096";
BA_ "Confidence" SG_ 1444 PM_a005_iDQmagnitude 1;
BA_ "Confidence" SG_ 1444 PM_a006_shiftState 1;
BA_ "GenSigSNA" SG_ 1444 PM_a006_shiftState "7";
BA_ "SystemSignalLongSymbol" SG_ 1444 PM_a006_requireAccelPedalCheckSp "PM_a006_requireAccelPedalCheckSpeed";
BA_ "Confidence" SG_ 1444 PM_a011_pmfHvilStatus 1;
BA_ "GenSigSNA" SG_ 1444 PM_a011_pmfHvilStatus "3";
BA_ "Confidence" SG_ 1444 PM_a011_pmrHvilStatus 1;
BA_ "GenSigSNA" SG_ 1444 PM_a011_pmrHvilStatus "3";
BA_ "Confidence" SG_ 1444 PM_a011_vehiclePowerState 1;
BA_ "Confidence" SG_ 1444 PM_a011_hvilSystemStatus 1;
BA_ "GenSigSNA" SG_ 1444 PM_a011_hvilSystemStatus "3";
BA_ "Confidence" SG_ 1444 PM_a014_track1Voltage 1;
BA_ "Confidence" SG_ 1444 PM_a014_track2Voltage 1;
BA_ "Confidence" SG_ 1444 PM_a014_accelErrorType 1;
BA_ "GenSigSNA" SG_ 1444 PM_a014_accelErrorType "0";
BA_ "Confidence" SG_ 1444 PM_a023_diCrsState 1;
BA_ "Confidence" SG_ 1444 PM_a023_pmCrsState 1;
BA_ "Confidence" SG_ 1444 PM_a023_crsFaultReason 1;
BA_ "Confidence" SG_ 1444 PM_a023_crsCancelReason 1;
BA_ "Confidence" SG_ 1444 PM_a023_cruiseTorquePed 1;
BA_ "Confidence" SG_ 1444 PM_a023_wheelSpdEstimateAbs 1;
BA_ "Confidence" SG_ 1444 PM_a023_accelEstimateDis 1;
BA_ "Confidence" SG_ 1444 PM_a026_reason 1;
BA_ "Confidence" SG_ 1444 PM_a030_diAebState 1;
BA_ "GenSigSNA" SG_ 1444 PM_a030_diAebState "7";
BA_ "Confidence" SG_ 1444 PM_a030_pmAebState 1;
BA_ "GenSigSNA" SG_ 1444 PM_a030_pmAebState "7";
BA_ "Confidence" SG_ 1444 PM_a030_dasAebEvent 1;
BA_ "GenSigSNA" SG_ 1444 PM_a030_dasAebEvent "3";
BA_ "Confidence" SG_ 1444 PM_a030_aebFaultReason 1;
BA_ "Confidence" SG_ 1444 PM_a030_aebUnavailableReason 1;
BA_ "Confidence" SG_ 1444 PM_a030_aebCancelReason 1;
BA_ "Confidence" SG_ 1444 PM_a030_diBrakeTorqueCommand 1;
BA_ "Confidence" SG_ 1444 PM_a036_timeSinceTxHWI 1;
BA_ "Confidence" SG_ 1444 PM_a036_timeSinceRxHWI 1;
BA_ "Confidence" SG_ 1444 PM_a036_timeSince100HzTxSWI 1;
BA_ "Confidence" SG_ 1444 PM_a036_timeSince1kHzCLK 1;
BA_ "Confidence" SG_ 1444 PM_a036_timeSince1kHzSWI 1;
BA_ "Confidence" SG_ 1444 PM_a036_timeSinceIdle 1;
BA_ "Confidence" SG_ 1444 PM_a036_ovfStackId 1;
BA_ "GenSigSNA" SG_ 1444 PM_a036_ovfStackId "15";
BA_ "Confidence" SG_ 1444 PM_a038_masterTorque 1;
BA_ "Confidence" SG_ 1444 PM_a038_slaveTorque 1;
BA_ "Confidence" SG_ 1444 PM_a038_pedalPos 1;
BA_ "SystemSignalLongSymbol" SG_ 1444 PM_a041_DAS_longControlTuningPar "PM_a041_DAS_longControlTuningParameters";
BA_ "Confidence" SG_ 1444 PM_a042_GTW_drivetrainType 1;
BA_ "Confidence" SG_ 1444 PM_a042_expectedPerformanceCfg 1;
BA_ "Confidence" SG_ 1444 PM_a044_pmCruiseState 1;
BA_ "Confidence" SG_ 1444 PM_a044_diCruiseState 1;
BA_ "Confidence" SG_ 1444 PM_a044_pmAebState 1;
BA_ "GenSigSNA" SG_ 1444 PM_a044_pmAebState "7";
BA_ "Confidence" SG_ 1444 PM_a044_diAebState 1;
BA_ "GenSigSNA" SG_ 1444 PM_a044_diAebState "7";
BA_ "Confidence" SG_ 1444 PM_a044_diBrakeTorqueCommand 1;
BA_ "Confidence" SG_ 1444 PM_a044_pmBfillTorqueAllowed 1;
BA_ "Confidence" SG_ 1444 PM_a044_pmVehicleHoldState 1;
BA_ "Confidence" SG_ 1444 PM_a044_diVehicleHoldState 1;
BA_ "Confidence" SG_ 1444 PM_a044_regenBackfillPmState 1;
BA_ "Confidence" SG_ 1444 PM_a045_regenBackfillPmState 1;
BA_ "Confidence" SG_ 1444 PM_a045_regenBackfillDiState 1;
BA_ "Confidence" SG_ 1444 PM_a045_unavailableReason 1;
BA_ "Confidence" SG_ 1444 PM_a045_diBrakeTorqueCommand 1;
BA_ "Confidence" SG_ 1444 PM_a045_pmBrakeTorqueAllowed 1;
BA_ "Confidence" SG_ 1444 PM_a046_diVhldState 1;
BA_ "Confidence" SG_ 1444 PM_a046_pmVhldState 1;
BA_ "Confidence" SG_ 1444 PM_a046_vhldFaultReason 1;
BA_ "Confidence" SG_ 1444 PM_a046_vhldUnavailableReason 1;
BA_ "Confidence" SG_ 1444 PM_a046_diBrakeTorqueCommand 1;
BA_ "Confidence" SG_ 1444 PM_a047_pmAutoparkState 1;
BA_ "GenSigSNA" SG_ 1444 PM_a047_pmAutoparkState "15";
BA_ "Confidence" SG_ 1444 PM_a047_diAutoparkState 1;
BA_ "GenSigSNA" SG_ 1444 PM_a047_diAutoparkState "15";
BA_ "Confidence" SG_ 1444 PM_a047_autoparkCancelReason 1;
BA_ "Confidence" SG_ 1444 PM_a048_vdcFaultReason 1;
BA_ "Confidence" SG_ 1444 PM_a060_TorqueAccelWindow 1;
BA_ "Confidence" SG_ 1444 PM_a060_TorqueDecelWindow 1;
BA_ "Confidence" SG_ 1444 PM_a060_TorqueReversalWindow 1;
BA_ "Confidence" SG_ 1444 PM_a062_errorType 1;
BA_ "Confidence" SG_ 1444 PM_a063_totalSystemTorqueCommand 1;
BA_ "Confidence" SG_ 1444 PM_a063_totalSystemTorqueMeasure 1;
BA_ "SystemSignalLongSymbol" SG_ 1444 PM_a063_totalSystemTorqueMeasure "PM_a063_totalSystemTorqueMeasured";
BA_ "Confidence" SG_ 1444 PM_a064_interventionType 1;
BA_ "Confidence" SG_ 1444 PM_a064_torqueCmdState 1;
BA_ "GenSigSNA" SG_ 1444 PM_a064_torqueCmdState "0";
BA_ "Confidence" SG_ 1444 PM_a064_UI_stoppingMode 1;
BA_ "Confidence" SG_ 1444 PM_a064_diCrsState 1;
BA_ "Confidence" SG_ 1444 PM_a064_pmCrsState 1;
BA_ "Confidence" SG_ 1444 PM_a070_unitTorqueActualMonitor 1;
BA_ "Confidence" SG_ 1444 PM_a070_unitTorqueCommandedMonit 1;
BA_ "SystemSignalLongSymbol" SG_ 1444 PM_a070_unitTorqueCommandedMonit "PM_a070_unitTorqueCommandedMonitor";
BA_ "Confidence" SG_ 1444 PM_a070_diTorqueCommandedMonitor 1;
BA_ "SystemSignalLongSymbol" SG_ 1444 PM_a070_rearAxleMotorTorqueLimit "PM_a070_rearAxleMotorTorqueLimitExceeded";
BA_ "Confidence" SG_ 1444 PM_a070_faultReason 1;
BA_ "Confidence" SG_ 1444 PM_a084_firewallId 1;
BA_ "Confidence" SG_ 1444 PM_a084_privId 1;
BA_ "Confidence" SG_ 1444 PM_a084_faultType 1;
BA_ "Confidence" SG_ 1444 PM_a087_errorType 1;
BA_ "Confidence" SG_ 1444 PM_a092_pllClockSource 1;
BA_ "Confidence" SG_ 1444 PM_a110_itpmsWarningFrL 1;
BA_ "Confidence" SG_ 1444 PM_a110_itpmsWarningFrR 1;
BA_ "Confidence" SG_ 1444 PM_a110_itpmsWarningReL 1;
BA_ "Confidence" SG_ 1444 PM_a110_itpmsWarningReR 1;
BA_ "Confidence" SG_ 1444 PM_a111_prevGearUnit0 1;
BA_ "GenSigSNA" SG_ 1444 PM_a111_prevGearUnit0 "7";
BA_ "Confidence" SG_ 1444 PM_a111_prevGearUnit1 1;
BA_ "GenSigSNA" SG_ 1444 PM_a111_prevGearUnit1 "7";
BA_ "Confidence" SG_ 1444 PM_a111_prevGearUnit2 1;
BA_ "GenSigSNA" SG_ 1444 PM_a111_prevGearUnit2 "7";
BA_ "Confidence" SG_ 1444 PM_a111_vehicleSpeed 1;
BA_ "Confidence" SG_ 1444 PM_a111_recoveryTargetGear 1;
BA_ "GenSigSNA" SG_ 1444 PM_a111_recoveryTargetGear "7";
BA_ "Confidence" SG_ 1444 PM_a111_failureReason 1;
BA_ "Confidence" SG_ 1444 PM_a112_itpmsWarningFrL 1;
BA_ "Confidence" SG_ 1444 PM_a112_itpmsWarningFrR 1;
BA_ "Confidence" SG_ 1444 PM_a112_itpmsWarningReL 1;
BA_ "Confidence" SG_ 1444 PM_a112_itpmsWarningReR 1;
BA_ "Confidence" SG_ 900 PM_matrixIndex 1;
BA_ "SystemSignalLongSymbol" SG_ 900 PM_a045_regenBackfillInterventio "PM_a045_regenBackfillIntervention";
BA_ "SystemSignalLongSymbol" SG_ 900 PM_a070_brakeTorqueSplitMonitorT "PM_a070_brakeTorqueSplitMonitorTrip";
BA_ "SystemSignalLongSymbol" SG_ 900 PM_a072_brakeTorqueCommandInterf "PM_a072_brakeTorqueCommandInterface";
BA_ "SystemSignalLongSymbol" SG_ 900 PM_a086_exceptionUndefinedInstru "PM_a086_exceptionUndefinedInstruction";
BA_ "SystemSignalLongSymbol" SG_ 900 PM_a095_ITPMSTimeoutGNSSConverge "PM_a095_ITPMSTimeoutGNSSConvergence";
BA_ "SystemSignalLongSymbol" SG_ 900 PM_a096_ITPMSConvergedGNSSAbsRad "PM_a096_ITPMSConvergedGNSSAbsRadiusTimes";
BA_ "SystemSignalLongSymbol" SG_ 900 PM_a097_ITPMSRelativeCalibratedF "PM_a097_ITPMSRelativeCalibratedFactors";
BA_ "SystemSignalLongSymbol" SG_ 900 PM_a110_indirectTPMSPressureLoss "PM_a110_indirectTPMSPressureLossWarning";
BA_ "SystemSignalLongSymbol" SG_ 900 PM_a111_unintendedResetCausedNeu "PM_a111_unintendedResetCausedNeutral";
BA_ "SystemSignalLongSymbol" SG_ 900 PM_a112_indirectTPMSPressureLoss "PM_a112_indirectTPMSPressureLossWarningHard";
BA_ "SystemSignalLongSymbol" SG_ 900 PM_a115_indirectTPMSFaultedGhost "PM_a115_indirectTPMSFaultedGhosted";
BA_ "SystemSignalLongSymbol" SG_ 900 PM_a117_ITPMSPermeabilityCalibra "PM_a117_ITPMSPermeabilityCalibrated";
BA_ "Confidence" SG_ 2022 PM_infoIndex 1;
BA_ "Confidence" SG_ 2022 PM_buildType 0;
BA_ "Confidence" SG_ 2022 PM_buildConfigurationId 0;
BA_ "Confidence" SG_ 2022 PM_hardwareId 0;
BA_ "Confidence" SG_ 2022 PM_deviceFused 0;
BA_ "Confidence" SG_ 2022 PM_componentId 0;
BA_ "Confidence" SG_ 2022 PM_pcbaId 0;
BA_ "Confidence" SG_ 2022 PM_assemblyId 0;
BA_ "Confidence" SG_ 2022 PM_usageId 0;
BA_ "Confidence" SG_ 2022 PM_subUsageId 0;
BA_ "Confidence" SG_ 2022 PM_applicationCrc 0;
BA_ "Confidence" SG_ 2022 PM_bootGitHash 0;
BA_ "Confidence" SG_ 1973 PM_itpmsDisplaySelector 1;
BA_ "Confidence" SG_ 1973 PM_indirectTPMSTellTale 0;
BA_ "Confidence" SG_ 1973 PM_indirectTPMSDisplayState 0;
BA_ "Confidence" SG_ 1973 PM_indirectTPMSDisplayProgress 0;
BA_ "Confidence" SG_ 1973 PM_indirectTPMSDisplayWarningInd 0;
BA_ "SystemSignalLongSymbol" SG_ 1973 PM_indirectTPMSDisplayWarningInd "PM_indirectTPMSDisplayWarningIndicatorFL";
BA_ "Confidence" SG_ 1973 PM_indirectTPMSDisplayWarni_0001 0;
BA_ "SystemSignalLongSymbol" SG_ 1973 PM_indirectTPMSDisplayWarni_0001 "PM_indirectTPMSDisplayWarningIndicatorFR";
BA_ "Confidence" SG_ 1973 PM_indirectTPMSDisplayWarni_0002 0;
BA_ "SystemSignalLongSymbol" SG_ 1973 PM_indirectTPMSDisplayWarni_0002 "PM_indirectTPMSDisplayWarningIndicatorRL";
BA_ "Confidence" SG_ 1973 PM_indirectTPMSDisplayWarni_0003 0;
BA_ "SystemSignalLongSymbol" SG_ 1973 PM_indirectTPMSDisplayWarni_0003 "PM_indirectTPMSDisplayWarningIndicatorRR";
BA_ "Confidence" SG_ 1973 PM_indirectTPMSRecommendedColdPr 0;
BA_ "GenSigSNA" SG_ 1973 PM_indirectTPMSRecommendedColdPr "255";
BA_ "SystemSignalLongSymbol" SG_ 1973 PM_indirectTPMSRecommendedColdPr "PM_indirectTPMSRecommendedColdPressureFront";
BA_ "Confidence" SG_ 1973 PM_indirectTPMSRecommendedC_0001 0;
BA_ "GenSigSNA" SG_ 1973 PM_indirectTPMSRecommendedC_0001 "255";
BA_ "SystemSignalLongSymbol" SG_ 1973 PM_indirectTPMSRecommendedC_0001 "PM_indirectTPMSRecommendedColdPressureRear";
BA_ "Confidence" SG_ 1973 PM_fusedPressureEstimateFrL 0;
BA_ "Confidence" SG_ 1973 PM_fusedPressureEstimateFrR 0;
BA_ "Confidence" SG_ 1973 PM_fusedPressureEstimateReL 0;
BA_ "Confidence" SG_ 1973 PM_fusedPressureEstimateReR 0;
BA_ "Confidence" SG_ 485 PM_cruiseFaultRequest 0;
BA_ "Confidence" SG_ 485 PM_shiftState 0;
BA_ "GenSigSNA" SG_ 485 PM_shiftState "7";
BA_ "Confidence" SG_ 485 PM_cruiseState 0;
BA_ "Confidence" SG_ 485 PM_vehicleHoldRequest 0;
BA_ "Confidence" SG_ 485 PM_aebRequest 0;
BA_ "Confidence" SG_ 485 PM_torqueCmdState 0;
BA_ "GenSigSNA" SG_ 485 PM_torqueCmdState "0";
BA_ "Confidence" SG_ 485 PM_btcCmdState 0;
BA_ "Confidence" SG_ 485 PM_unparkAllowed 0;
BA_ "Confidence" SG_ 485 PM_stationaryMode 0;
BA_ "Confidence" SG_ 485 PM_onePedalFaultRequest 0;
BA_ "Confidence" SG_ 485 PM_backfillDisableRequest 0;
BA_ "Confidence" SG_ 485 PM_autoparkState 0;
BA_ "GenSigSNA" SG_ 485 PM_autoparkState "15";
BA_ "Confidence" SG_ 485 PM_regenBlendCmdQF 0;
BA_ "Confidence" SG_ 485 PM_brakePedalCmdQF 0;
BA_ "Confidence" SG_ 485 PM_latentFaultCheckIntResponse 0;
BA_ "Confidence" SG_ 485 PM_hvilSystemStatus 0;
BA_ "GenSigSNA" SG_ 485 PM_hvilSystemStatus "3";
BA_ "Confidence" SG_ 485 PM_locStateCounter 0;
BA_ "Confidence" SG_ 485 PM_locStateChecksum 0;
VAL_ 1317 PMF_alertID 121 "a121_unintendedReset2" 114 "a114_ramScrubTimedOut" 100 "a100_diTraceInfo1" 97 "a097_lowFlowAlmostTripped" 96 "a096_safetyICDebug" 95 "a095_safetyICFault" 94 "a094_safetyICWarn" 92 "a092_xtalOscillator" 86 "a086_exceptionUndefinedInstruction" 84 "a084_exceptionMpuFirewall" 83 "a083_ahbWriteError" 82 "a082_exceptionDataAbort2" 81 "a081_exceptionDataAbort" 80 "a080_exceptionPrefetchAbort" 64 "a064_torqueIntervention" 62 "a062_eccError" 61 "a061_DIPMVersionMismatch" 58 "a058_measuredHvilCurrentFrozen" 57 "a057_canDataBusB" 56 "a056_canHardwareBusB" 55 "a055_resolver" 54 "a054_uiMIA" 53 "a053_vcfrontMIA" 45 "a045_motorMovementDetected" 42 "a042_gtwMIA" 40 "a040_pmMIA" 39 "a039_disMIA" 37 "a037_hvpMIA" 36 "a036_preWatchdog" 35 "a035_udsTransactionInitiated" 34 "a034_trqCrossCheck" 33 "a033_selfTest" 32 "a032_registerConfigError" 31 "a031_highStackUsage" 28 "a028_torqueCmdError" 27 "a027_torqueEstimationOutOfBounds" 26 "a026_diHeartBeatMIA" 25 "a025_unintendedReset" 19 "a019_statorTempIrrational" 18 "a018_encoderIrrational" 17 "a017_brakeMIA" 13 "a013_canHardwareBusA" 12 "a012_canDataBusA" 11 "a011_phaseCurrentIrrational" 10 "a010_diMIA" 8 "a008_memoryError" 6 "a006_underTorqueCheck" 5 "a005_torqueInNeutralOrPark" 4 "a004_excessiveDecelTorque" 3 "a003_excessiveReversalTorque" 2 "a002_excessiveAccelTorque" 1 "a001_absoluteTorque" 0 "ALERT_DO_NOT_USE_ZERO" ;
VAL_ 1317 PMF_alertState 1 "SET" 0 "CLEARED" ;
VAL_ 1317 PMF_a002_torqueMeasured -4096 "SNA" ;
VAL_ 1317 PMF_a002_torqueAccelAverage -4096 "SNA" ;
VAL_ 1317 PMF_a002_torqueAccelWindow -4096 "SNA" ;
VAL_ 1317 PMF_a004_torqueMeasured -4096 "SNA" ;
VAL_ 1317 PMF_a004_torqueDecelAverage -4096 "SNA" ;
VAL_ 1317 PMF_a004_torqueDecelWindow -4096 "SNA" ;
VAL_ 1317 PMF_a005_torqueReason 2 "SLAVE_ENABLE_IN_NEUTRAL" 1 "CURRENT_IN_NEUTRAL" 0 "TORQUE_IN_NEUTRAL" ;
VAL_ 1317 PMF_a005_torqueMeasured -4096 "SNA" ;
VAL_ 1317 PMF_a006_torqueActual -4096 "SNA" ;
VAL_ 1317 PMF_a006_torqueMeasured -4096 "SNA" ;
VAL_ 1317 PMF_a026_reason 1 "TooFast" 0 "TooSlow" ;
VAL_ 1317 PMF_a033_state 13 "DISABLED" 12 "TEST_RESTART" 11 "TEST_FAILED" 10 "TEST_SKIPPED" 9 "TEST_PASSED" 8 "TEST_PRE_PASSED" 7 "CURRENT_TEST_NEG" 6 "CURRENT_TEST_POS" 5 "PWM_ENABLE" 4 "ASC_TEST_PASSED" 3 "ASC_TEST" 2 "PSTG_BRING_UP_AT_SPEED" 1 "PSTG_BRING_UP" 0 "INIT" ;
VAL_ 1317 PMF_a033_failReason 7 "ASC_TEST" 6 "FAULT_PRESENT" 5 "SWITCH_SHORT_DISABLE_CONDITIONS_MET" 4 "TIMEDOUT" 3 "DISAGREE" 2 "NEG_CURRENT" 1 "POS_CURRENT" 0 "CACHED" ;
VAL_ 1317 PMF_a036_ovfStackId 15 "SNA" ;
VAL_ 1317 PMF_a042_GTW_drivetrainType 1 "AWD" 0 "RWD" ;
VAL_ 1317 PMF_a042_expectedPerformanceCfg 1 "AWD" 0 "RWD" ;
VAL_ 1317 PMF_a062_errorType 12 "RAM_CORRECTABLE_DMA" 11 "RAM_CORRECTABLE_CLA" 10 "RAM_CORRECTABLE_CPU" 9 "RAM_UNCORRECTABLE_DMA" 8 "RAM_UNCORRECTABLE_CLA" 7 "RAM_UNCORRECTABLE_CPU" 6 "FLASH_FAIL1_HIGH" 5 "FLASH_FAIL1_LOW" 4 "FLASH_FAIL0_HIGH" 3 "FLASH_FAIL0_LOW" 2 "FLASH_UNCORRECTABLE_HIGH" 1 "FLASH_UNCORRECTABLE_LOW" 0 "UNKNOWN" ;
VAL_ 1317 PMF_a064_interventionType 15 "excessiveMotorMz" 14 "inconsistentAxleTorque" 13 "diHeartbeat" 12 "currentAfterIntervention" 11 "switchingAfterIntervention" 10 "switchOffPathTestFail" 9 "inconsistentTorqueSign" 8 "torqueInNeutral" 7 "excessiveRegenTorque" 6 "torqueReversal" 5 "accumulatedTorque" 4 "motorMovementDetected" 3 "cruiseFault" 2 "torqueCmdInvalid" 1 "resolver" 0 "masterTorqueMonitorShutoff" ;
VAL_ 1317 PMF_a064_torqueCmdState 8 "Invalid" 6 "Valid" 0 "SNA" ;
VAL_ 1317 PMF_a064_UI_stoppingMode 2 "HOLD" 1 "CREEP" 0 "STANDARD" ;
VAL_ 1317 PMF_a064_diCrsState 7 "PRE_CANCEL" 6 "PRE_FAULT" 5 "FAULT" 4 "OVERRIDE" 3 "STANDSTILL" 2 "ENABLED" 1 "STANDBY" 0 "UNAVAILABLE" ;
VAL_ 1317 PMF_a064_pmCrsState 7 "PRE_CANCEL" 6 "PRE_FAULT" 5 "FAULT" 4 "OVERRIDE" 3 "STANDSTILL" 2 "ENABLED" 1 "STANDBY" 0 "UNAVAILABLE" ;
VAL_ 1317 PMF_a084_firewallId 17 "HSM_SLV" 16 "R5SS1_CORE1_AHB_MST" 15 "R5SS1_CORE0_AHB_MST" 14 "R5SS0_CORE1_AHB_MST" 13 "R5SS0_CORE0_AHB_MST" 12 "SCRM2SCRP1_SLV" 11 "SCRM2SCRP0_SLV" 10 "QSPI0_SLV" 9 "MBOX_RAM_SLV" 8 "DTHE_SLV" 7 "R5SS1_CORE1_AXIS_SLV" 6 "R5SS1_CORE0_AXIS_SLV" 5 "R5SS0_CORE1_AXIS_SLV" 4 "R5SS0_CORE0_AXIS_SLV" 3 "L2OCRAM_BANK3_SLV" 2 "L2OCRAM_BANK2_SLV" 1 "L2OCRAM_BANK1_SLV" 0 "L2OCRAM_BANK0_SLV" ;
VAL_ 1317 PMF_a084_privId 10 "CPSW" 9 "ICSSM" 7 "R5FSS1_1" 6 "R5FSS1_0" 5 "R5FSS0_1" 4 "R5FSS0_0" 1 "M4FSS0_0" ;
VAL_ 1317 PMF_a084_faultType 6 "SUPER_READ" 5 "SUPER_WRITE" 4 "SUPER_EXE" 3 "USER_READ" 2 "USER_WRITE" 1 "USER_EXE" 0 "NO_FAULT" ;
VAL_ 1317 PMF_a092_pllClockSource 2 "INTOSC1" 1 "XTAL" 0 "INTOSC2" ;
VAL_ 1317 PMF_a095_safetyICstate 5 "WAKE" 4 "STANDBY" 3 "SLEEP" 2 "NORMAL" 1 "INIT" 0 "NONE" ;
VAL_ 772 PMF_matrixIndex 2 "AlertMatrix2" 1 "AlertMatrix1" 0 "AlertMatrix0" ;
VAL_ 790 PMF_infoIndex 255 "END" 21 "DI_BUILD_DATA" 20 "UDS_PROTOCOL_BOOTCRC" 19 "VERSION_DEPRECATED" 18 "BOOTLOADER_GITHASH" 17 "APP_GITHASH" 16 "SUBCOMPONENT" 15 "BOOTLOADER_CRC" 14 "BOOTLOADER_SVN" 13 "APP_CRC" 11 "PCBAID_ASSYID_USAGEID" 10 "BUILD_HWID_COMPONENTID" 9 "DEPRECATED_9" 8 "DEPRECATED_8" 7 "DEPRECATED_7" 6 "DEPRECATED_6" 5 "DEPRECATED_5" 4 "DEPRECATED_4" 3 "DEPRECATED_3" 2 "DEPRECATED_2" 1 "DEPRECATED_1" 0 "DEPRECATED_0" ;
VAL_ 790 PMF_buildType 4 "INFO_MFG_BUILD" 3 "INFO_TRACEABLE_CI_BUILD" 2 "INFO_LOCAL_BUILD" 1 "INFO_PLATFORM_BUILD" 0 "INFO_UNKNOWN_BUILD" ;
VAL_ 790 PMF_hardwareId 252 "CONFIGURABLE_HWID_PLACEHOLDER" ;
VAL_ 1446 PMR_alertID 121 "a121_unintendedReset2" 114 "a114_ramScrubTimedOut" 102 "a102_ipcFluidTempHigh" 101 "a101_hwVoltageMonitorTrip" 100 "a100_diTraceInfo1" 97 "a097_lowFlowAlmostTripped" 96 "a096_safetyICDebug" 95 "a095_safetyICFault" 94 "a094_safetyICWarn" 92 "a092_xtalOscillator" 86 "a086_exceptionUndefinedInstruction" 84 "a084_exceptionMpuFirewall" 83 "a083_ahbWriteError" 82 "a082_exceptionDataAbort2" 81 "a081_exceptionDataAbort" 80 "a080_exceptionPrefetchAbort" 64 "a064_torqueIntervention" 62 "a062_eccError" 61 "a061_DIPMVersionMismatch" 58 "a058_measuredHvilCurrentFrozen" 57 "a057_canDataBusB" 56 "a056_canHardwareBusB" 55 "a055_resolver" 54 "a054_uiMIA" 53 "a053_vcfrontMIA" 45 "a045_motorMovementDetected" 42 "a042_gtwMIA" 40 "a040_pmMIA" 39 "a039_disMIA" 37 "a037_hvpMIA" 36 "a036_preWatchdog" 35 "a035_udsTransactionInitiated" 34 "a034_trqCrossCheck" 33 "a033_selfTest" 32 "a032_registerConfigError" 31 "a031_highStackUsage" 28 "a028_torqueCmdError" 27 "a027_torqueEstimationOutOfBounds" 26 "a026_diHeartBeatMIA" 25 "a025_unintendedReset" 19 "a019_statorTempIrrational" 18 "a018_encoderIrrational" 17 "a017_brakeMIA" 13 "a013_canHardwareBusA" 12 "a012_canDataBusA" 11 "a011_phaseCurrentIrrational" 10 "a010_diMIA" 8 "a008_memoryError" 6 "a006_underTorqueCheck" 5 "a005_torqueInNeutralOrPark" 4 "a004_excessiveDecelTorque" 3 "a003_excessiveReversalTorque" 2 "a002_excessiveAccelTorque" 1 "a001_absoluteTorque" 0 "ALERT_DO_NOT_USE_ZERO" ;
VAL_ 1446 PMR_alertState 1 "SET" 0 "CLEARED" ;
VAL_ 1446 PMR_a002_torqueMeasured -4096 "SNA" ;
VAL_ 1446 PMR_a002_torqueAccelAverage -4096 "SNA" ;
VAL_ 1446 PMR_a002_torqueAccelWindow -4096 "SNA" ;
VAL_ 1446 PMR_a004_torqueMeasured -4096 "SNA" ;
VAL_ 1446 PMR_a004_torqueDecelAverage -4096 "SNA" ;
VAL_ 1446 PMR_a004_torqueDecelWindow -4096 "SNA" ;
VAL_ 1446 PMR_a005_torqueReason 2 "SLAVE_ENABLE_IN_NEUTRAL" 1 "CURRENT_IN_NEUTRAL" 0 "TORQUE_IN_NEUTRAL" ;
VAL_ 1446 PMR_a005_torqueMeasured -4096 "SNA" ;
VAL_ 1446 PMR_a006_torqueActual -4096 "SNA" ;
VAL_ 1446 PMR_a006_torqueMeasured -4096 "SNA" ;
VAL_ 1446 PMR_a026_reason 1 "TooFast" 0 "TooSlow" ;
VAL_ 1446 PMR_a033_state 13 "DISABLED" 12 "TEST_RESTART" 11 "TEST_FAILED" 10 "TEST_SKIPPED" 9 "TEST_PASSED" 8 "TEST_PRE_PASSED" 7 "CURRENT_TEST_NEG" 6 "CURRENT_TEST_POS" 5 "PWM_ENABLE" 4 "ASC_TEST_PASSED" 3 "ASC_TEST" 2 "PSTG_BRING_UP_AT_SPEED" 1 "PSTG_BRING_UP" 0 "INIT" ;
VAL_ 1446 PMR_a033_failReason 7 "ASC_TEST" 6 "FAULT_PRESENT" 5 "SWITCH_SHORT_DISABLE_CONDITIONS_MET" 4 "TIMEDOUT" 3 "DISAGREE" 2 "NEG_CURRENT" 1 "POS_CURRENT" 0 "CACHED" ;
VAL_ 1446 PMR_a036_ovfStackId 15 "SNA" ;
VAL_ 1446 PMR_a042_GTW_drivetrainType 1 "AWD" 0 "RWD" ;
VAL_ 1446 PMR_a042_expectedPerformanceCfg 1 "AWD" 0 "RWD" ;
VAL_ 1446 PMR_a062_errorType 12 "RAM_CORRECTABLE_DMA" 11 "RAM_CORRECTABLE_CLA" 10 "RAM_CORRECTABLE_CPU" 9 "RAM_UNCORRECTABLE_DMA" 8 "RAM_UNCORRECTABLE_CLA" 7 "RAM_UNCORRECTABLE_CPU" 6 "FLASH_FAIL1_HIGH" 5 "FLASH_FAIL1_LOW" 4 "FLASH_FAIL0_HIGH" 3 "FLASH_FAIL0_LOW" 2 "FLASH_UNCORRECTABLE_HIGH" 1 "FLASH_UNCORRECTABLE_LOW" 0 "UNKNOWN" ;
VAL_ 1446 PMR_a064_interventionType 15 "excessiveMotorMz" 14 "inconsistentAxleTorque" 13 "diHeartbeat" 12 "currentAfterIntervention" 11 "switchingAfterIntervention" 10 "switchOffPathTestFail" 9 "inconsistentTorqueSign" 8 "torqueInNeutral" 7 "excessiveRegenTorque" 6 "torqueReversal" 5 "accumulatedTorque" 4 "motorMovementDetected" 3 "cruiseFault" 2 "torqueCmdInvalid" 1 "resolver" 0 "masterTorqueMonitorShutoff" ;
VAL_ 1446 PMR_a064_torqueCmdState 8 "Invalid" 6 "Valid" 0 "SNA" ;
VAL_ 1446 PMR_a064_UI_stoppingMode 2 "HOLD" 1 "CREEP" 0 "STANDARD" ;
VAL_ 1446 PMR_a064_diCrsState 7 "PRE_CANCEL" 6 "PRE_FAULT" 5 "FAULT" 4 "OVERRIDE" 3 "STANDSTILL" 2 "ENABLED" 1 "STANDBY" 0 "UNAVAILABLE" ;
VAL_ 1446 PMR_a064_pmCrsState 7 "PRE_CANCEL" 6 "PRE_FAULT" 5 "FAULT" 4 "OVERRIDE" 3 "STANDSTILL" 2 "ENABLED" 1 "STANDBY" 0 "UNAVAILABLE" ;
VAL_ 1446 PMR_a084_firewallId 17 "HSM_SLV" 16 "R5SS1_CORE1_AHB_MST" 15 "R5SS1_CORE0_AHB_MST" 14 "R5SS0_CORE1_AHB_MST" 13 "R5SS0_CORE0_AHB_MST" 12 "SCRM2SCRP1_SLV" 11 "SCRM2SCRP0_SLV" 10 "QSPI0_SLV" 9 "MBOX_RAM_SLV" 8 "DTHE_SLV" 7 "R5SS1_CORE1_AXIS_SLV" 6 "R5SS1_CORE0_AXIS_SLV" 5 "R5SS0_CORE1_AXIS_SLV" 4 "R5SS0_CORE0_AXIS_SLV" 3 "L2OCRAM_BANK3_SLV" 2 "L2OCRAM_BANK2_SLV" 1 "L2OCRAM_BANK1_SLV" 0 "L2OCRAM_BANK0_SLV" ;
VAL_ 1446 PMR_a084_privId 10 "CPSW" 9 "ICSSM" 7 "R5FSS1_1" 6 "R5FSS1_0" 5 "R5FSS0_1" 4 "R5FSS0_0" 1 "M4FSS0_0" ;
VAL_ 1446 PMR_a084_faultType 6 "SUPER_READ" 5 "SUPER_WRITE" 4 "SUPER_EXE" 3 "USER_READ" 2 "USER_WRITE" 1 "USER_EXE" 0 "NO_FAULT" ;
VAL_ 1446 PMR_a092_pllClockSource 2 "INTOSC1" 1 "XTAL" 0 "INTOSC2" ;
VAL_ 1446 PMR_a095_safetyICstate 5 "WAKE" 4 "STANDBY" 3 "SLEEP" 2 "NORMAL" 1 "INIT" 0 "NONE" ;
VAL_ 902 PMR_matrixIndex 2 "AlertMatrix2" 1 "AlertMatrix1" 0 "AlertMatrix0" ;
VAL_ 1748 PMR_infoIndex 255 "END" 21 "DI_BUILD_DATA" 20 "UDS_PROTOCOL_BOOTCRC" 19 "VERSION_DEPRECATED" 18 "BOOTLOADER_GITHASH" 17 "APP_GITHASH" 16 "SUBCOMPONENT" 15 "BOOTLOADER_CRC" 14 "BOOTLOADER_SVN" 13 "APP_CRC" 11 "PCBAID_ASSYID_USAGEID" 10 "BUILD_HWID_COMPONENTID" 9 "DEPRECATED_9" 8 "DEPRECATED_8" 7 "DEPRECATED_7" 6 "DEPRECATED_6" 5 "DEPRECATED_5" 4 "DEPRECATED_4" 3 "DEPRECATED_3" 2 "DEPRECATED_2" 1 "DEPRECATED_1" 0 "DEPRECATED_0" ;
VAL_ 1748 PMR_buildType 4 "INFO_MFG_BUILD" 3 "INFO_TRACEABLE_CI_BUILD" 2 "INFO_LOCAL_BUILD" 1 "INFO_PLATFORM_BUILD" 0 "INFO_UNKNOWN_BUILD" ;
VAL_ 1748 PMR_hardwareId 252 "CONFIGURABLE_HWID_PLACEHOLDER" ;
VAL_ 1444 PM_alertID 125 "a125_btcOutputIrrational" 121 "a121_unintendedReset2" 120 "a120_indirectTPMSFaulted" 118 "a118_vehicleSpeedQFDiagnostic" 117 "a117_ITPMSPermeabilityCalibrated" 116 "a116_ITPMSBlowoutCalProgress" 115 "a115_indirectTPMSFaultedGhosted" 114 "a114_ramScrubTimedOut" 113 "a113_btcMonitor" 112 "a112_indirectTPMSPressureLossWarningHard" 111 "a111_unintendedResetCausedNeutral" 110 "a110_indirectTPMSPressureLossWarning" 100 "a100_diTraceInfo1" 99 "a099_ITPMSCalibrated" 98 "a098_ITPMSTriggerDebug" 97 "a097_ITPMSRelativeCalibratedFactors" 96 "a096_ITPMSConvergedGNSSAbsRadiusTimes" 95 "a095_ITPMSTimeoutGNSSConvergence" 94 "a094_torqueSplitMonitor" 93 "a093_accelPedalSupply" 92 "a092_xtalOscillator" 88 "a088_absMonitor" 87 "a087_canHardwareBusLIPC" 86 "a086_exceptionUndefinedInstruction" 85 "a085_dpbMIA" 84 "a084_exceptionMpuFirewall" 83 "a083_ahbWriteError" 82 "a082_exceptionDataAbort2" 81 "a081_exceptionDataAbort" 80 "a080_exceptionPrefetchAbort" 79 "a079_rcuMIA" 78 "a078_canHardwareBusE" 77 "a077_canDataBusE" 76 "a076_canHardwareBusD" 75 "a075_canDataBusD" 74 "a074_canHardwareBusC" 73 "a073_canDataBusC" 72 "a072_brakeTorqueCommandInterface" 71 "a071_baseBrakingMonitor" 70 "a070_brakeTorqueSplitMonitorTrip" 69 "a069_brakeMonitorsUnhealthy" 68 "a068_brakePedalMonitor" 67 "a067_pmrMIA" 66 "a066_pmfMIA" 64 "a064_torqueIntervention" 63 "a063_torqueCommandInhibit" 62 "a062_eccError" 61 "a061_DIPMVersionMismatch" 60 "a060_onePedalDrivingInhibit" 59 "a059_ptcMIA" 58 "a058_cmpMIA" 57 "a057_canDataBusB" 56 "a056_canHardwareBusB" 55 "a055_accelPedalSyncWarn" 54 "a054_uiMIA" 53 "a053_vcfrontMIA" 52 "a052_stbCtrlDrvrDecelCflct" 51 "a051_unintDecelStbCtrl" 50 "a050_excessiveStbCtrlTrq" 49 "a049_stbCtrlInWrongDir" 48 "a048_stabilityControlInhibit" 47 "a047_inconsAutoparkState" 46 "a046_inconsVehicleHoldState" 45 "a045_regenBackfillIntervention" 44 "a044_ebrIntervention" 43 "a043_inconsistentConfig" 42 "a042_gtwMIA" 41 "a041_dasMIA" 40 "a040_alignmentDriftDetected" 39 "a039_disMIA" 38 "a038_inconsistentTorqueSign" 36 "a036_preWatchdog" 35 "a035_udsTransactionInitiated" 34 "a034_trqCrossCheck" 33 "a033_appMIA" 32 "a032_registerConfigError" 31 "a031_highStackUsage" 30 "a030_inconsistentAebState" 29 "a029_cruiseRollback" 28 "a028_torqueCmdError" 26 "a026_diHeartBeatMIA" 25 "a025_unintendedReset" 24 "a024_brakeIrrational" 23 "a023_cruiseInhibit" 22 "a022_dirMIA" 21 "a021_difMIA" 17 "a017_brakeMIA" 16 "a016_bbMIA" 15 "a015_shifterMIA" 14 "a014_accelPedalError" 13 "a013_canHardwareBusA" 12 "a012_canDataBusA" 11 "a011_systemHvilNotClosed" 10 "a010_diMIA" 9 "a009_espMIA" 8 "a008_memoryError" 7 "a007_ibstMIA" 6 "a006_inconsistentDIGear" 5 "a005_torqueInNeutralOrPark" 4 "a004_excessiveDecelTorque" 3 "a003_excessiveReversalTorque" 2 "a002_excessiveAccelTorque" 1 "a001_absoluteTorque" 0 "ALERT_DO_NOT_USE_ZERO" ;
VAL_ 1444 PM_alertState 1 "SET" 0 "CLEARED" ;
VAL_ 1444 PM_a002_torqueMeasured -4096 "SNA" ;
VAL_ 1444 PM_a002_torqueAccelAverage -4096 "SNA" ;
VAL_ 1444 PM_a002_torqueAccelWindow -4096 "SNA" ;
VAL_ 1444 PM_a003_torqueMeasured -4096 "SNA" ;
VAL_ 1444 PM_a003_torqueCommanded -4096 "SNA" ;
VAL_ 1444 PM_a004_torqueMeasured -4096 "SNA" ;
VAL_ 1444 PM_a004_torqueDecelAverage -4096 "SNA" ;
VAL_ 1444 PM_a004_torqueDecelWindow -4096 "SNA" ;
VAL_ 1444 PM_a005_torqueReason 2 "SLAVE_ENABLE_IN_NEUTRAL" 1 "CURRENT_IN_NEUTRAL" 0 "TORQUE_IN_NEUTRAL" ;
VAL_ 1444 PM_a005_torqueMeasured -4096 "SNA" ;
VAL_ 1444 PM_a006_shiftState 7 "SNA" 4 "D" 3 "N" 2 "R" 1 "P" 0 "INVALID" ;
VAL_ 1444 PM_a011_pmfHvilStatus 3 "SNA" 2 "CLOSED" 1 "OPEN" 0 "DISABLED" ;
VAL_ 1444 PM_a011_pmrHvilStatus 3 "SNA" 2 "CLOSED" 1 "OPEN" 0 "DISABLED" ;
VAL_ 1444 PM_a011_vehiclePowerState 3 "DRIVE" 2 "ACCESSORY" 1 "CONDITIONING" 0 "OFF" ;
VAL_ 1444 PM_a011_hvilSystemStatus 3 "SNA" 2 "CLOSED" 1 "OPEN" 0 "DISABLED" ;
VAL_ 1444 PM_a014_accelErrorType 3 "AccelTracksOutOfSync" 2 "Accel2RangeError" 1 "Accel1RangeError" 0 "SNA" ;
VAL_ 1444 PM_a023_diCrsState 7 "PRE_CANCEL" 6 "PRE_FAULT" 5 "FAULT" 4 "OVERRIDE" 3 "STANDSTILL" 2 "ENABLED" 1 "STANDBY" 0 "UNAVAILABLE" ;
VAL_ 1444 PM_a023_pmCrsState 7 "PRE_CANCEL" 6 "PRE_FAULT" 5 "FAULT" 4 "OVERRIDE" 3 "STANDSTILL" 2 "ENABLED" 1 "STANDBY" 0 "UNAVAILABLE" ;
VAL_ 1444 PM_a023_crsFaultReason 19 "GEAR" 18 "VDC_FAULT" 17 "APC_FAULT" 16 "DECEL" 15 "ACCEL" 14 "TORQUE" 13 "DI_MIA" 12 "JERK_RQ" 11 "ACCEL_RQ" 10 "TC_FAULT" 9 "EPB_FAULT" 7 "CONFIG" 6 "WHEEL_SPDS_INVAL" 5 "EPB_MIA" 4 "SCCM_MIA" 3 "ESP_MIA" 2 "ESP_FAULT" 1 "EBR_FAULT" 0 "NONE" ;
VAL_ 1444 PM_a023_crsCancelReason 10 "SKID" 9 "STALK_CMD" 8 "BRAKE" 7 "EPB" 6 "DAS" 5 "TC" 4 "ESP" 3 "GEAR" 2 "AEB_ACTIVE" 1 "OFF_BTN" 0 "NONE" ;
VAL_ 1444 PM_a026_reason 1 "TooFast" 0 "TooSlow" ;
VAL_ 1444 PM_a030_diAebState 7 "SNA" 5 "UNAVAILABLE_ALERT" 4 "FAULT" 3 "STANDSTILL" 2 "ENABLED" 1 "STANDBY" 0 "UNAVAILABLE" ;
VAL_ 1444 PM_a030_pmAebState 7 "SNA" 5 "UNAVAILABLE_ALERT" 4 "FAULT" 3 "STANDSTILL" 2 "ENABLED" 1 "STANDBY" 0 "UNAVAILABLE" ;
VAL_ 1444 PM_a030_dasAebEvent 3 "SNA" 2 "FAULT" 1 "ACTIVE" 0 "NOT_ACTIVE" ;
VAL_ 1444 PM_a030_aebFaultReason 6 "SPEED_DELTA" 5 "ESP_FAULT" 4 "EBR_FAULT" 3 "WHEEL_SPEEDS_INVALID" 2 "ESP_MIA" 0 "NONE" ;
VAL_ 1444 PM_a030_aebUnavailableReason 11 "UNAVAILABLE_ABS_FAULT" 10 "UNAVAILABLE_WHEEL_SPEEDS_INVALID" 9 "UNAVAILABLE_DAS_CONTROL_MIA" 8 "UNAVAILABLE_REVERSE_SPEED" 7 "UNAVAILABLE_EBR" 6 "UNAVAILABLE_NEGATIVE_SPEED" 5 "UNAVAILABLE_GEAR" 4 "UNAVAILABLE_SKID" 3 "UNAVAILABLE_ESP_UNAVAILABLE" 2 "UNAVAILABLE_DI_STATE" 1 "UNAVAILBLE_EPB_PARK" 0 "UNAVAILABLE_NONE" ;
VAL_ 1444 PM_a030_aebCancelReason 2 "EPB_FAULT" 1 "DAS" 0 "NONE" ;
VAL_ 1444 PM_a036_ovfStackId 15 "SNA" ;
VAL_ 1444 PM_a042_GTW_drivetrainType 1 "AWD" 0 "RWD" ;
VAL_ 1444 PM_a042_expectedPerformanceCfg 1 "AWD" 0 "RWD" ;
VAL_ 1444 PM_a044_pmCruiseState 7 "PRE_CANCEL" 6 "PRE_FAULT" 5 "FAULT" 4 "OVERRIDE" 3 "STANDSTILL" 2 "ENABLED" 1 "STANDBY" 0 "UNAVAILABLE" ;
VAL_ 1444 PM_a044_diCruiseState 7 "PRE_CANCEL" 6 "PRE_FAULT" 5 "FAULT" 4 "OVERRIDE" 3 "STANDSTILL" 2 "ENABLED" 1 "STANDBY" 0 "UNAVAILABLE" ;
VAL_ 1444 PM_a044_pmAebState 7 "SNA" 5 "UNAVAILABLE_ALERT" 4 "FAULT" 3 "STANDSTILL" 2 "ENABLED" 1 "STANDBY" 0 "UNAVAILABLE" ;
VAL_ 1444 PM_a044_diAebState 7 "SNA" 5 "UNAVAILABLE_ALERT" 4 "FAULT" 3 "STANDSTILL" 2 "ENABLED" 1 "STANDBY" 0 "UNAVAILABLE" ;
VAL_ 1444 PM_a044_pmVehicleHoldState 7 "INIT" 6 "FAULT" 5 "PARK" 4 "BLEND_OUT" 3 "STANDSTILL" 2 "BLEND_IN" 1 "STANDBY" 0 "UNAVAILABLE" ;
VAL_ 1444 PM_a044_diVehicleHoldState 7 "INIT" 6 "FAULT" 5 "PARK" 4 "BLEND_OUT" 3 "STANDSTILL" 2 "BLEND_IN" 1 "STANDBY" 0 "UNAVAILABLE" ;
VAL_ 1444 PM_a044_regenBackfillPmState 2 "ACTIVE" 1 "STANDBY" 0 "UNAVAILABLE" ;
VAL_ 1444 PM_a045_regenBackfillPmState 2 "ACTIVE" 1 "STANDBY" 0 "UNAVAILABLE" ;
VAL_ 1444 PM_a045_regenBackfillDiState 2 "ACTIVE" 1 "STANDBY" 0 "UNAVAILABLE" ;
VAL_ 1444 PM_a045_unavailableReason 18 "DI_LATENT_FAULT_TRIP" 17 "EBR_FULL_FAULT" 16 "PM_DISABLE_REQUEST_BPED" 15 "PM_DISABLE_REQUEST_BLEND" 14 "CARBON_CERAMIC_BRAKES" 13 "BRAKE_TEMP" 12 "EBR_FAULT" 11 "PM_DISABLE_REQUEST" 10 "TRACK_MODE_ACTIVE" 9 "VELOCITY_ESTIMATOR_UNAVAILABLE" 8 "TRACTION_CONTROL_UNAVAILABLE" 7 "ACTIVE_DAMPING_UNAVAILABLE" 6 "UI_COASTDOWN_MODE" 5 "SYSTEM_STATE" 4 "NON_DRIVE_GEAR" 3 "EBR_UNAVAILABLE" 2 "UI_DISABLE" 1 "GTW_DISABLE" 0 "NONE" ;
VAL_ 1444 PM_a046_diVhldState 7 "INIT" 6 "FAULT" 5 "PARK" 4 "BLEND_OUT" 3 "STANDSTILL" 2 "BLEND_IN" 1 "STANDBY" 0 "UNAVAILABLE" ;
VAL_ 1444 PM_a046_pmVhldState 7 "INIT" 6 "FAULT" 5 "PARK" 4 "BLEND_OUT" 3 "STANDSTILL" 2 "BLEND_IN" 1 "STANDBY" 0 "UNAVAILABLE" ;
VAL_ 1444 PM_a046_vhldFaultReason 7 "REQUESTED" 6 "WHEEL_SPDS_INVAL" 5 "EPB_MIA" 4 "ESP_MIA" 3 "ESP_FAULT" 2 "BRAKE_INVALID" 1 "EBR_FAULT" 0 "NONE" ;
VAL_ 1444 PM_a046_vhldUnavailableReason 9 "EBR" 8 "AEB_ACTIVE" 7 "CRUISE_ACTIVE" 6 "SPEED" 5 "GEAR" 4 "SKID" 3 "DI_FAULT" 2 "EPB_FAULT" 1 "EPB" 0 "NONE" ;
VAL_ 1444 PM_a047_pmAutoparkState 15 "SNA" 9 "SELFPARK_STARTED" 8 "UNPARK_COMPLETE" 7 "RESUMED" 6 "ABORTED" 5 "PAUSED" 4 "COMPLETE" 3 "ACTIVE" 2 "STARTED" 1 "STANDBY" 0 "UNAVAILABLE" ;
VAL_ 1444 PM_a047_diAutoparkState 15 "SNA" 9 "SELFPARK_STARTED" 8 "UNPARK_COMPLETE" 7 "RESUMED" 6 "ABORTED" 5 "PAUSED" 4 "COMPLETE" 3 "ACTIVE" 2 "STARTED" 1 "STANDBY" 0 "UNAVAILABLE" ;
VAL_ 1444 PM_a047_autoparkCancelReason 3 "CANCEL_SPEED_VIOLATION" 2 "CRUISE_CANCEL_TIMEOUT" 1 "CANCEL_BRAKE_APPLY" 0 "CANCEL_NONE" ;
VAL_ 1444 PM_a048_vdcFaultReason 9 "OUTPUT_RATIONALITY" 8 "CP_ESTIMATE_MISMATCH" 7 "EXCESSIVE_TSC_ACTIVITY" 6 "INVALID_REQUEST" 5 "INVALID_GEAR" 4 "EXCESSIVE_YAW_TORQUE" 3 "REVERSAL_YAW_TORQUE" 2 "DECEL_UNINTENDED" 1 "DECEL_INABILITY" 0 "NONE" ;
VAL_ 1444 PM_a062_errorType 12 "RAM_CORRECTABLE_DMA" 11 "RAM_CORRECTABLE_CLA" 10 "RAM_CORRECTABLE_CPU" 9 "RAM_UNCORRECTABLE_DMA" 8 "RAM_UNCORRECTABLE_CLA" 7 "RAM_UNCORRECTABLE_CPU" 6 "FLASH_FAIL1_HIGH" 5 "FLASH_FAIL1_LOW" 4 "FLASH_FAIL0_HIGH" 3 "FLASH_FAIL0_LOW" 2 "FLASH_UNCORRECTABLE_HIGH" 1 "FLASH_UNCORRECTABLE_LOW" 0 "UNKNOWN" ;
VAL_ 1444 PM_a064_interventionType 15 "excessiveMotorMz" 14 "inconsistentAxleTorque" 13 "diHeartbeat" 12 "currentAfterIntervention" 11 "switchingAfterIntervention" 10 "switchOffPathTestFail" 9 "inconsistentTorqueSign" 8 "torqueInNeutral" 7 "excessiveRegenTorque" 6 "torqueReversal" 5 "accumulatedTorque" 4 "motorMovementDetected" 3 "cruiseFault" 2 "torqueCmdInvalid" 1 "resolver" 0 "masterTorqueMonitorShutoff" ;
VAL_ 1444 PM_a064_torqueCmdState 8 "Invalid" 6 "Valid" 0 "SNA" ;
VAL_ 1444 PM_a064_UI_stoppingMode 2 "HOLD" 1 "CREEP" 0 "STANDARD" ;
VAL_ 1444 PM_a064_diCrsState 7 "PRE_CANCEL" 6 "PRE_FAULT" 5 "FAULT" 4 "OVERRIDE" 3 "STANDSTILL" 2 "ENABLED" 1 "STANDBY" 0 "UNAVAILABLE" ;
VAL_ 1444 PM_a064_pmCrsState 7 "PRE_CANCEL" 6 "PRE_FAULT" 5 "FAULT" 4 "OVERRIDE" 3 "STANDSTILL" 2 "ENABLED" 1 "STANDBY" 0 "UNAVAILABLE" ;
VAL_ 1444 PM_a070_unitTorqueActualMonitor 4 "TRIP_SOFT_LANDING" 3 "TRIP_UNDER_BRAKING" 2 "TRIP_UNINTENDED_BRAKING" 1 "TRIP_EXCESSIVE_BRAKING" 0 "NO_TRIP" ;
VAL_ 1444 PM_a070_unitTorqueCommandedMonit 4 "TRIP_SOFT_LANDING" 3 "TRIP_UNDER_BRAKING" 2 "TRIP_UNINTENDED_BRAKING" 1 "TRIP_EXCESSIVE_BRAKING" 0 "NO_TRIP" ;
VAL_ 1444 PM_a070_diTorqueCommandedMonitor 4 "TRIP_SOFT_LANDING" 3 "TRIP_UNDER_BRAKING" 2 "TRIP_UNINTENDED_BRAKING" 1 "TRIP_EXCESSIVE_BRAKING" 0 "NO_TRIP" ;
VAL_ 1444 PM_a070_faultReason 11 "SOFT_LANDING" 10 "EBR_INVALID_NONZERO" 9 "VELOCITY_EST_FAULT" 8 "REAR_AXLE_TORQUE_LIM" 7 "EBR_OR_BACKFILL" 6 "PM_UNHEALTHY" 5 "MISSING_INPUTS" 4 "TORQUE_CMD_RATIONALITY" 3 "BRAKE_PEDAL_MAP" 2 "REGEN_BLENDING" 1 "BRAKE_BOOSTER" 0 "NONE" ;
VAL_ 1444 PM_a084_firewallId 17 "HSM_SLV" 16 "R5SS1_CORE1_AHB_MST" 15 "R5SS1_CORE0_AHB_MST" 14 "R5SS0_CORE1_AHB_MST" 13 "R5SS0_CORE0_AHB_MST" 12 "SCRM2SCRP1_SLV" 11 "SCRM2SCRP0_SLV" 10 "QSPI0_SLV" 9 "MBOX_RAM_SLV" 8 "DTHE_SLV" 7 "R5SS1_CORE1_AXIS_SLV" 6 "R5SS1_CORE0_AXIS_SLV" 5 "R5SS0_CORE1_AXIS_SLV" 4 "R5SS0_CORE0_AXIS_SLV" 3 "L2OCRAM_BANK3_SLV" 2 "L2OCRAM_BANK2_SLV" 1 "L2OCRAM_BANK1_SLV" 0 "L2OCRAM_BANK0_SLV" ;
VAL_ 1444 PM_a084_privId 10 "CPSW" 9 "ICSSM" 7 "R5FSS1_1" 6 "R5FSS1_0" 5 "R5FSS0_1" 4 "R5FSS0_0" 1 "M4FSS0_0" ;
VAL_ 1444 PM_a084_faultType 6 "SUPER_READ" 5 "SUPER_WRITE" 4 "SUPER_EXE" 3 "USER_READ" 2 "USER_WRITE" 1 "USER_EXE" 0 "NO_FAULT" ;
VAL_ 1444 PM_a087_errorType 5 "IPC_TX_OVERRUN" 4 "IPC_RX_OVERRUN" 3 "TX_OVERRUN" 2 "RX_OVERRUN" 1 "TX" 0 "RX" ;
VAL_ 1444 PM_a092_pllClockSource 2 "INTOSC1" 1 "XTAL" 0 "INTOSC2" ;
VAL_ 1444 PM_a110_itpmsWarningFrL 2 "HARD" 1 "SOFT" 0 "NONE" ;
VAL_ 1444 PM_a110_itpmsWarningFrR 2 "HARD" 1 "SOFT" 0 "NONE" ;
VAL_ 1444 PM_a110_itpmsWarningReL 2 "HARD" 1 "SOFT" 0 "NONE" ;
VAL_ 1444 PM_a110_itpmsWarningReR 2 "HARD" 1 "SOFT" 0 "NONE" ;
VAL_ 1444 PM_a111_prevGearUnit0 7 "SNA" 4 "D" 3 "N" 2 "R" 1 "P" 0 "INVALID" ;
VAL_ 1444 PM_a111_prevGearUnit1 7 "SNA" 4 "D" 3 "N" 2 "R" 1 "P" 0 "INVALID" ;
VAL_ 1444 PM_a111_prevGearUnit2 7 "SNA" 4 "D" 3 "N" 2 "R" 1 "P" 0 "INVALID" ;
VAL_ 1444 PM_a111_recoveryTargetGear 7 "SNA" 4 "D" 3 "N" 2 "R" 1 "P" 0 "INVALID" ;
VAL_ 1444 PM_a111_failureReason 10 "SAFETY_CONDITIONS_CHANGED" 9 "NO_UNINTENDED_RESET" 8 "EEPROM_WRITE_FAILED" 7 "SSM_NOT_READY" 6 "SPEED_POLARITY_MISMATCH" 5 "EPB_MIA_OR_ENGAGED" 4 "NOT_IN_NEUTRAL" 3 "UNIT_CONSENSUS_FAILED" 2 "RETRY_LIMIT_EXCEEDED" 1 "EEPROM_INVALID" 0 "RECOVERY_SUCCESS" ;
VAL_ 1444 PM_a112_itpmsWarningFrL 2 "HARD" 1 "SOFT" 0 "NONE" ;
VAL_ 1444 PM_a112_itpmsWarningFrR 2 "HARD" 1 "SOFT" 0 "NONE" ;
VAL_ 1444 PM_a112_itpmsWarningReL 2 "HARD" 1 "SOFT" 0 "NONE" ;
VAL_ 1444 PM_a112_itpmsWarningReR 2 "HARD" 1 "SOFT" 0 "NONE" ;
VAL_ 900 PM_matrixIndex 2 "AlertMatrix2" 1 "AlertMatrix1" 0 "AlertMatrix0" ;
VAL_ 2022 PM_infoIndex 255 "END" 21 "DI_BUILD_DATA" 20 "UDS_PROTOCOL_BOOTCRC" 19 "VERSION_DEPRECATED" 18 "BOOTLOADER_GITHASH" 17 "APP_GITHASH" 16 "SUBCOMPONENT" 15 "BOOTLOADER_CRC" 14 "BOOTLOADER_SVN" 13 "APP_CRC" 11 "PCBAID_ASSYID_USAGEID" 10 "BUILD_HWID_COMPONENTID" 9 "DEPRECATED_9" 8 "DEPRECATED_8" 7 "DEPRECATED_7" 6 "DEPRECATED_6" 5 "DEPRECATED_5" 4 "DEPRECATED_4" 3 "DEPRECATED_3" 2 "DEPRECATED_2" 1 "DEPRECATED_1" 0 "DEPRECATED_0" ;
VAL_ 2022 PM_buildType 4 "INFO_MFG_BUILD" 3 "INFO_TRACEABLE_CI_BUILD" 2 "INFO_LOCAL_BUILD" 1 "INFO_PLATFORM_BUILD" 0 "INFO_UNKNOWN_BUILD" ;
VAL_ 2022 PM_hardwareId 252 "CONFIGURABLE_HWID_PLACEHOLDER" ;
VAL_ 1973 PM_itpmsDisplaySelector 3 "Mux3" 2 "Mux2" 1 "Mux1" 0 "Mux0" ;
VAL_ 1973 PM_indirectTPMSTellTale 2 "TPMS_TELLTALE_FLASHING" 1 "TPMS_TELLTALE_SOLID" 0 "TPMS_TELLTALE_OFF" ;
VAL_ 1973 PM_indirectTPMSDisplayState 3 "FAULTED" 2 "CALIBRATED" 1 "CALIBRATING" 0 "UNAVAILABLE" ;
VAL_ 1973 PM_indirectTPMSDisplayWarningInd 2 "HARD" 1 "SOFT" 0 "NONE" ;
VAL_ 1973 PM_indirectTPMSDisplayWarni_0001 2 "HARD" 1 "SOFT" 0 "NONE" ;
VAL_ 1973 PM_indirectTPMSDisplayWarni_0002 2 "HARD" 1 "SOFT" 0 "NONE" ;
VAL_ 1973 PM_indirectTPMSDisplayWarni_0003 2 "HARD" 1 "SOFT" 0 "NONE" ;
VAL_ 1973 PM_indirectTPMSRecommendedColdPr 255 "SNA" 254 "OVER_RANGE" ;
VAL_ 1973 PM_indirectTPMSRecommendedC_0001 255 "SNA" 254 "OVER_RANGE" ;
VAL_ 485 PM_shiftState 7 "DI_GEAR_SNA" 4 "DI_GEAR_D" 3 "DI_GEAR_N" 2 "DI_GEAR_R" 1 "DI_GEAR_P" 0 "DI_GEAR_INVALID" ;
VAL_ 485 PM_cruiseState 7 "CRS_STATE_PRE_CANCEL" 6 "CRS_STATE_PRE_FAULT" 5 "CRS_STATE_FAULT" 4 "CRS_STATE_OVERRIDE" 3 "CRS_STATE_STANDSTILL" 2 "CRS_STATE_ENABLED" 1 "CRS_STATE_STANDBY" 0 "CRS_STATE_UNAVAILABLE" ;
VAL_ 485 PM_vehicleHoldRequest 1 "PM_VHLD_OFF_REQUEST" 0 "PM_NO_VHLD_REQUEST" ;
VAL_ 485 PM_aebRequest 1 "PM_AEB_OFF_REQUEST" 0 "PM_NO_AEB_REQUEST" ;
VAL_ 485 PM_torqueCmdState 8 "TorqueCmd_Invalid" 6 "TorqueCmd_Valid" 0 "TorqueCmd_SNA" ;
VAL_ 485 PM_btcCmdState 1 "BTC_CMD_VALID" 0 "BTC_CMD_INVALID" ;
VAL_ 485 PM_autoparkState 15 "DI_APC_SNA" 9 "DI_APC_SELFPARK_STARTED" 8 "DI_APC_UNPARK_COMPLETE" 7 "DI_APC_RESUMED" 6 "DI_APC_ABORTED" 5 "DI_APC_PAUSED" 4 "DI_APC_COMPLETE" 3 "DI_APC_ACTIVE" 2 "DI_APC_STARTED" 1 "DI_APC_STANDBY" 0 "DI_APC_UNAVAILABLE" ;
VAL_ 485 PM_regenBlendCmdQF 1 "BRAKE_COMMAND_VALID" 0 "BRAKE_COMMAND_INVALID" ;
VAL_ 485 PM_brakePedalCmdQF 1 "BRAKE_COMMAND_VALID" 0 "BRAKE_COMMAND_INVALID" ;
VAL_ 485 PM_hvilSystemStatus 3 "SNA" 2 "CLOSED" 1 "OPEN" 0 "DISABLED" ;
